VERSION ""

NS_ :

BS_:

BU_: HVESP01 HVESS

BO_ 2499742056 HVESP01_modTemperature_4: 8 HVESP01
 SG_ HVESP01_modTemperature_01_4 m0 : 16|8@1- (1,25) [-103|152] "Celsius"  HVESP01
 SG_ HVESP01_modTemperature_02_4 m0 : 24|8@1- (1,25) [-103|152] "Celsius"  HVESP01
 SG_ HVESP01_modTemperature_03_4 m0 : 32|8@1- (1,25) [-103|152] "Celsius"  HVESP01
 SG_ HVESP01_modTemperature_04_4 m0 : 40|8@1- (1,25) [-103|152] "Celsius"  HVESP01
 SG_ HVESP01_modTemperature_05_4 m0 : 48|8@1- (1,25) [-103|152] "Celsius"  HVESP01
 SG_ HVESP01_modTemperature_06_4 m1 : 16|8@1- (1,25) [-103|152] "Celsius"  HVESP01
 SG_ HVESP01_modTemperature_07_4 m1 : 24|8@1- (1,25) [-103|152] "Celsius"  HVESP01
 SG_ HVESP01_modTemperature_08_4 m1 : 32|8@1- (1,25) [-103|152] "Celsius"  HVESP01
 SG_ HVESP01_modTemperature_09_4 m1 : 40|8@1- (1,25) [-103|152] "Celsius"  HVESP01
 SG_ HVESP01_modTemperature_10_4 m1 : 48|8@1- (1,25) [-103|152] "Celsius"  HVESP01
 SG_ HVESP01_modTemperature_11_4 m2 : 16|8@1- (1,25) [-103|152] "Celsius"  HVESP01
 SG_ HVESP01_modTemperature_12_4 m2 : 24|8@1- (1,25) [-103|152] "Celsius"  HVESP01
 SG_ HVESP01_modTemperature_13_4 m2 : 32|8@1- (1,25) [-103|152] "Celsius"  HVESP01
 SG_ HVESP01_modTemperature_14_4 m2 : 40|8@1- (1,25) [-103|152] "Celsius"  HVESP01
 SG_ HVESP01_modTemperature_15_4 m2 : 48|8@1- (1,25) [-103|152] "Celsius"  HVESP01
 SG_ HVESP01_modTemperature_16_4 m3 : 16|8@1- (1,25) [-103|152] "Celsius"  HVESP01
 SG_ HVESP01_modTemperature_17_4 m3 : 24|8@1- (1,25) [-103|152] "Celsius"  HVESP01
 SG_ HVESP01_modTemperature_18_4 m3 : 32|8@1- (1,25) [-103|152] "Celsius"  HVESP01
 SG_ HVESP01_modTemperature_19_4 m3 : 40|8@1- (1,25) [-103|152] "Celsius"  HVESP01
 SG_ HVESP01_modTemperature_20_4 m3 : 48|8@1- (1,25) [-103|152] "Celsius"  HVESP01
 SG_ HVESP01_modTemperature_21_4 m4 : 16|8@1- (1,25) [-103|152] "Celsius"  HVESP01
 SG_ HVESP01_modTemperature_22_4 m4 : 24|8@1- (1,25) [-103|152] "Celsius"  HVESP01
 SG_ HVESP01_modTemperature_23_4 m4 : 32|8@1- (1,25) [-103|152] "Celsius"  HVESP01
 SG_ HVESP01_modTemperature_24_4 m4 : 40|8@1- (1,25) [-103|152] "Celsius"  HVESP01
 SG_ HVESP01_modTemperature_25_4 m4 : 48|8@1- (1,25) [-103|152] "Celsius"  HVESP01
 SG_ HVESP01_modTemperature_26_4 m5 : 16|8@1- (1,25) [-103|152] "Celsius"  HVESP01
 SG_ HVESP01_modTemperature_27_4 m5 : 24|8@1- (1,25) [-103|152] "Celsius"  HVESP01
 SG_ HVESP01_modTemperature_28_4 m5 : 32|8@1- (1,25) [-103|152] "Celsius"  HVESP01
 SG_ HVESP01_modTemperature_29_4 m5 : 40|8@1- (1,25) [-103|152] "Celsius"  HVESP01
 SG_ HVESP01_modTemperature_30_4 m5 : 48|8@1- (1,25) [-103|152] "Celsius"  HVESP01
 SG_ HVESP01_modTemperature_31_4 m6 : 16|8@1- (1,25) [-103|152] "Celsius"  HVESP01
 SG_ HVESP01_modTemperature_32_4 m6 : 24|8@1- (1,25) [-103|152] "Celsius"  HVESP01
 SG_ HVESP01_modTemperature_33_4 m6 : 32|8@1- (1,25) [-103|152] "Celsius"  HVESP01
 SG_ HVESP01_modTemperature_34_4 m6 : 40|8@1- (1,25) [-103|152] "Celsius"  HVESP01
 SG_ HVESP01_modTemperature_35_4 m6 : 48|8@1- (1,25) [-103|152] "Celsius"  HVESP01
 SG_ HVESP01_modTemperature_36_4 m7 : 16|8@1- (1,25) [-103|152] "Celsius"  HVESP01
 SG_ HVESP01_modTemperature_37_4 m7 : 24|8@1- (1,25) [-103|152] "Celsius"  HVESP01
 SG_ HVESP01_modTemperature_38_4 m7 : 32|8@1- (1,25) [-103|152] "Celsius"  HVESP01
 SG_ HVESP01_modTemperature_39_4 m7 : 40|8@1- (1,25) [-103|152] "Celsius"  HVESP01
 SG_ HVESP01_modTemperature_40_4 m7 : 48|8@1- (1,25) [-103|152] "Celsius"  HVESP01
 SG_ HVESP01_modTemperature_41_4 m8 : 16|8@1- (1,25) [-103|152] "Celsius"  HVESP01
 SG_ HVESP01_modTemperature_42_4 m8 : 24|8@1- (1,25) [-103|152] "Celsius"  HVESP01
 SG_ HVESP01_modTemperature_43_4 m8 : 32|8@1- (1,25) [-103|152] "Celsius"  HVESP01
 SG_ HVESP01_modTemperature_44_4 m8 : 40|8@1- (1,25) [-103|152] "Celsius"  HVESP01
 SG_ multiplexormt_4 M : 0|9@1+ (1,0) [0|255] ""  HVESP01

BO_ 2499742057 HVESP01_modTemperature_5: 8 HVESP01
 SG_ HVESP01_modTemperature_01_5 m0 : 16|8@1- (1,25) [-103|152] "Celsius"  HVESP01
 SG_ HVESP01_modTemperature_02_5 m0 : 24|8@1- (1,25) [-103|152] "Celsius"  HVESP01
 SG_ HVESP01_modTemperature_03_5 m0 : 32|8@1- (1,25) [-103|152] "Celsius"  HVESP01
 SG_ HVESP01_modTemperature_04_5 m0 : 40|8@1- (1,25) [-103|152] "Celsius"  HVESP01
 SG_ HVESP01_modTemperature_05_5 m0 : 48|8@1- (1,25) [-103|152] "Celsius"  HVESP01
 SG_ HVESP01_modTemperature_06_5 m1 : 16|8@1- (1,25) [-103|152] "Celsius"  HVESP01
 SG_ HVESP01_modTemperature_07_5 m1 : 24|8@1- (1,25) [-103|152] "Celsius"  HVESP01
 SG_ HVESP01_modTemperature_08_5 m1 : 32|8@1- (1,25) [-103|152] "Celsius"  HVESP01
 SG_ HVESP01_modTemperature_09_5 m1 : 40|8@1- (1,25) [-103|152] "Celsius"  HVESP01
 SG_ HVESP01_modTemperature_10_5 m1 : 48|8@1- (1,25) [-103|152] "Celsius"  HVESP01
 SG_ HVESP01_modTemperature_11_5 m2 : 16|8@1- (1,25) [-103|152] "Celsius"  HVESP01
 SG_ HVESP01_modTemperature_12_5 m2 : 24|8@1- (1,25) [-103|152] "Celsius"  HVESP01
 SG_ HVESP01_modTemperature_13_5 m2 : 32|8@1- (1,25) [-103|152] "Celsius"  HVESP01
 SG_ HVESP01_modTemperature_14_5 m2 : 40|8@1- (1,25) [-103|152] "Celsius"  HVESP01
 SG_ HVESP01_modTemperature_15_5 m2 : 48|8@1- (1,25) [-103|152] "Celsius"  HVESP01
 SG_ HVESP01_modTemperature_16_5 m3 : 16|8@1- (1,25) [-103|152] "Celsius"  HVESP01
 SG_ HVESP01_modTemperature_17_5 m3 : 24|8@1- (1,25) [-103|152] "Celsius"  HVESP01
 SG_ HVESP01_modTemperature_18_5 m3 : 32|8@1- (1,25) [-103|152] "Celsius"  HVESP01
 SG_ HVESP01_modTemperature_19_5 m3 : 40|8@1- (1,25) [-103|152] "Celsius"  HVESP01
 SG_ HVESP01_modTemperature_20_5 m3 : 48|8@1- (1,25) [-103|152] "Celsius"  HVESP01
 SG_ HVESP01_modTemperature_21_5 m4 : 16|8@1- (1,25) [-103|152] "Celsius"  HVESP01
 SG_ HVESP01_modTemperature_22_5 m4 : 24|8@1- (1,25) [-103|152] "Celsius"  HVESP01
 SG_ HVESP01_modTemperature_23_5 m4 : 32|8@1- (1,25) [-103|152] "Celsius"  HVESP01
 SG_ HVESP01_modTemperature_24_5 m4 : 40|8@1- (1,25) [-103|152] "Celsius"  HVESP01
 SG_ HVESP01_modTemperature_25_5 m4 : 48|8@1- (1,25) [-103|152] "Celsius"  HVESP01
 SG_ HVESP01_modTemperature_26_5 m5 : 16|8@1- (1,25) [-103|152] "Celsius"  HVESP01
 SG_ HVESP01_modTemperature_27_5 m5 : 24|8@1- (1,25) [-103|152] "Celsius"  HVESP01
 SG_ HVESP01_modTemperature_28_5 m5 : 32|8@1- (1,25) [-103|152] "Celsius"  HVESP01
 SG_ HVESP01_modTemperature_29_5 m5 : 40|8@1- (1,25) [-103|152] "Celsius"  HVESP01
 SG_ HVESP01_modTemperature_30_5 m5 : 48|8@1- (1,25) [-103|152] "Celsius"  HVESP01
 SG_ HVESP01_modTemperature_31_5 m6 : 16|8@1- (1,25) [-103|152] "Celsius"  HVESP01
 SG_ HVESP01_modTemperature_32_5 m6 : 24|8@1- (1,25) [-103|152] "Celsius"  HVESP01
 SG_ HVESP01_modTemperature_33_5 m6 : 32|8@1- (1,25) [-103|152] "Celsius"  HVESP01
 SG_ HVESP01_modTemperature_34_5 m6 : 40|8@1- (1,25) [-103|152] "Celsius"  HVESP01
 SG_ HVESP01_modTemperature_35_5 m6 : 48|8@1- (1,25) [-103|152] "Celsius"  HVESP01
 SG_ HVESP01_modTemperature_36_5 m7 : 16|8@1- (1,25) [-103|152] "Celsius"  HVESP01
 SG_ HVESP01_modTemperature_37_5 m7 : 24|8@1- (1,25) [-103|152] "Celsius"  HVESP01
 SG_ HVESP01_modTemperature_38_5 m7 : 32|8@1- (1,25) [-103|152] "Celsius"  HVESP01
 SG_ HVESP01_modTemperature_39_5 m7 : 40|8@1- (1,25) [-103|152] "Celsius"  HVESP01
 SG_ HVESP01_modTemperature_40_5 m7 : 48|8@1- (1,25) [-103|152] "Celsius"  HVESP01
 SG_ HVESP01_modTemperature_41_5 m8 : 16|8@1- (1,25) [-103|152] "Celsius"  HVESP01
 SG_ HVESP01_modTemperature_42_5 m8 : 24|8@1- (1,25) [-103|152] "Celsius"  HVESP01
 SG_ HVESP01_modTemperature_43_5 m8 : 32|8@1- (1,25) [-103|152] "Celsius"  HVESP01
 SG_ HVESP01_modTemperature_44_5 m8 : 40|8@1- (1,25) [-103|152] "Celsius"  HVESP01
 SG_ multiplexormt_5 M : 0|9@1+ (1,0) [0|255] ""  HVESP01

BO_ 2499742058 HVESP01_modTemperature_6: 8 HVESP01
 SG_ HVESP01_modTemperature_01_6 m0 : 16|8@1- (1,25) [-103|152] "Celsius"  HVESP01
 SG_ HVESP01_modTemperature_02_6 m0 : 24|8@1- (1,25) [-103|152] "Celsius"  HVESP01
 SG_ HVESP01_modTemperature_03_6 m0 : 32|8@1- (1,25) [-103|152] "Celsius"  HVESP01
 SG_ HVESP01_modTemperature_04_6 m0 : 40|8@1- (1,25) [-103|152] "Celsius"  HVESP01
 SG_ HVESP01_modTemperature_05_6 m0 : 48|8@1- (1,25) [-103|152] "Celsius"  HVESP01
 SG_ HVESP01_modTemperature_06_6 m1 : 16|8@1- (1,25) [-103|152] "Celsius"  HVESP01
 SG_ HVESP01_modTemperature_07_6 m1 : 24|8@1- (1,25) [-103|152] "Celsius"  HVESP01
 SG_ HVESP01_modTemperature_08_6 m1 : 32|8@1- (1,25) [-103|152] "Celsius"  HVESP01
 SG_ HVESP01_modTemperature_09_6 m1 : 40|8@1- (1,25) [-103|152] "Celsius"  HVESP01
 SG_ HVESP01_modTemperature_10_6 m1 : 48|8@1- (1,25) [-103|152] "Celsius"  HVESP01
 SG_ HVESP01_modTemperature_11_6 m2 : 16|8@1- (1,25) [-103|152] "Celsius"  HVESP01
 SG_ HVESP01_modTemperature_12_6 m2 : 24|8@1- (1,25) [-103|152] "Celsius"  HVESP01
 SG_ HVESP01_modTemperature_13_6 m2 : 32|8@1- (1,25) [-103|152] "Celsius"  HVESP01
 SG_ HVESP01_modTemperature_14_6 m2 : 40|8@1- (1,25) [-103|152] "Celsius"  HVESP01
 SG_ HVESP01_modTemperature_15_6 m2 : 48|8@1- (1,25) [-103|152] "Celsius"  HVESP01
 SG_ HVESP01_modTemperature_16_6 m3 : 16|8@1- (1,25) [-103|152] "Celsius"  HVESP01
 SG_ HVESP01_modTemperature_17_6 m3 : 24|8@1- (1,25) [-103|152] "Celsius"  HVESP01
 SG_ HVESP01_modTemperature_18_6 m3 : 32|8@1- (1,25) [-103|152] "Celsius"  HVESP01
 SG_ HVESP01_modTemperature_19_6 m3 : 40|8@1- (1,25) [-103|152] "Celsius"  HVESP01
 SG_ HVESP01_modTemperature_20_6 m3 : 48|8@1- (1,25) [-103|152] "Celsius"  HVESP01
 SG_ HVESP01_modTemperature_21_6 m4 : 16|8@1- (1,25) [-103|152] "Celsius"  HVESP01
 SG_ HVESP01_modTemperature_22_6 m4 : 24|8@1- (1,25) [-103|152] "Celsius"  HVESP01
 SG_ HVESP01_modTemperature_23_6 m4 : 32|8@1- (1,25) [-103|152] "Celsius"  HVESP01
 SG_ HVESP01_modTemperature_24_6 m4 : 40|8@1- (1,25) [-103|152] "Celsius"  HVESP01
 SG_ HVESP01_modTemperature_25_6 m4 : 48|8@1- (1,25) [-103|152] "Celsius"  HVESP01
 SG_ HVESP01_modTemperature_26_6 m5 : 16|8@1- (1,25) [-103|152] "Celsius"  HVESP01
 SG_ HVESP01_modTemperature_27_6 m5 : 24|8@1- (1,25) [-103|152] "Celsius"  HVESP01
 SG_ HVESP01_modTemperature_28_6 m5 : 32|8@1- (1,25) [-103|152] "Celsius"  HVESP01
 SG_ HVESP01_modTemperature_29_6 m5 : 40|8@1- (1,25) [-103|152] "Celsius"  HVESP01
 SG_ HVESP01_modTemperature_30_6 m5 : 48|8@1- (1,25) [-103|152] "Celsius"  HVESP01
 SG_ HVESP01_modTemperature_31_6 m6 : 16|8@1- (1,25) [-103|152] "Celsius"  HVESP01
 SG_ HVESP01_modTemperature_32_6 m6 : 24|8@1- (1,25) [-103|152] "Celsius"  HVESP01
 SG_ HVESP01_modTemperature_33_6 m6 : 32|8@1- (1,25) [-103|152] "Celsius"  HVESP01
 SG_ HVESP01_modTemperature_34_6 m6 : 40|8@1- (1,25) [-103|152] "Celsius"  HVESP01
 SG_ HVESP01_modTemperature_35_6 m6 : 48|8@1- (1,25) [-103|152] "Celsius"  HVESP01
 SG_ HVESP01_modTemperature_36_6 m7 : 16|8@1- (1,25) [-103|152] "Celsius"  HVESP01
 SG_ HVESP01_modTemperature_37_6 m7 : 24|8@1- (1,25) [-103|152] "Celsius"  HVESP01
 SG_ HVESP01_modTemperature_38_6 m7 : 32|8@1- (1,25) [-103|152] "Celsius"  HVESP01
 SG_ HVESP01_modTemperature_39_6 m7 : 40|8@1- (1,25) [-103|152] "Celsius"  HVESP01
 SG_ HVESP01_modTemperature_40_6 m7 : 48|8@1- (1,25) [-103|152] "Celsius"  HVESP01
 SG_ HVESP01_modTemperature_41_6 m8 : 16|8@1- (1,25) [-103|152] "Celsius"  HVESP01
 SG_ HVESP01_modTemperature_42_6 m8 : 24|8@1- (1,25) [-103|152] "Celsius"  HVESP01
 SG_ HVESP01_modTemperature_43_6 m8 : 32|8@1- (1,25) [-103|152] "Celsius"  HVESP01
 SG_ HVESP01_modTemperature_44_6 m8 : 40|8@1- (1,25) [-103|152] "Celsius"  HVESP01
 SG_ multiplexormt_6 M : 0|9@1+ (1,0) [0|255] ""  HVESP01

BO_ 2499742059 HVESP01_modTemperature_7: 8 HVESP01
 SG_ HVESP01_modTemperature_01_7 m0 : 16|8@1- (1,25) [-103|152] "Celsius"  HVESP01
 SG_ HVESP01_modTemperature_02_7 m0 : 24|8@1- (1,25) [-103|152] "Celsius"  HVESP01
 SG_ HVESP01_modTemperature_03_7 m0 : 32|8@1- (1,25) [-103|152] "Celsius"  HVESP01
 SG_ HVESP01_modTemperature_04_7 m0 : 40|8@1- (1,25) [-103|152] "Celsius"  HVESP01
 SG_ HVESP01_modTemperature_05_7 m0 : 48|8@1- (1,25) [-103|152] "Celsius"  HVESP01
 SG_ HVESP01_modTemperature_06_7 m1 : 16|8@1- (1,25) [-103|152] "Celsius"  HVESP01
 SG_ HVESP01_modTemperature_07_7 m1 : 24|8@1- (1,25) [-103|152] "Celsius"  HVESP01
 SG_ HVESP01_modTemperature_08_7 m1 : 32|8@1- (1,25) [-103|152] "Celsius"  HVESP01
 SG_ HVESP01_modTemperature_09_7 m1 : 40|8@1- (1,25) [-103|152] "Celsius"  HVESP01
 SG_ HVESP01_modTemperature_10_7 m1 : 48|8@1- (1,25) [-103|152] "Celsius"  HVESP01
 SG_ HVESP01_modTemperature_11_7 m2 : 16|8@1- (1,25) [-103|152] "Celsius"  HVESP01
 SG_ HVESP01_modTemperature_12_7 m2 : 24|8@1- (1,25) [-103|152] "Celsius"  HVESP01
 SG_ HVESP01_modTemperature_13_7 m2 : 32|8@1- (1,25) [-103|152] "Celsius"  HVESP01
 SG_ HVESP01_modTemperature_14_7 m2 : 40|8@1- (1,25) [-103|152] "Celsius"  HVESP01
 SG_ HVESP01_modTemperature_15_7 m2 : 48|8@1- (1,25) [-103|152] "Celsius"  HVESP01
 SG_ HVESP01_modTemperature_16_7 m3 : 16|8@1- (1,25) [-103|152] "Celsius"  HVESP01
 SG_ HVESP01_modTemperature_17_7 m3 : 24|8@1- (1,25) [-103|152] "Celsius"  HVESP01
 SG_ HVESP01_modTemperature_18_7 m3 : 32|8@1- (1,25) [-103|152] "Celsius"  HVESP01
 SG_ HVESP01_modTemperature_19_7 m3 : 40|8@1- (1,25) [-103|152] "Celsius"  HVESP01
 SG_ HVESP01_modTemperature_20_7 m3 : 48|8@1- (1,25) [-103|152] "Celsius"  HVESP01
 SG_ HVESP01_modTemperature_21_7 m4 : 16|8@1- (1,25) [-103|152] "Celsius"  HVESP01
 SG_ HVESP01_modTemperature_22_7 m4 : 24|8@1- (1,25) [-103|152] "Celsius"  HVESP01
 SG_ HVESP01_modTemperature_23_7 m4 : 32|8@1- (1,25) [-103|152] "Celsius"  HVESP01
 SG_ HVESP01_modTemperature_24_7 m4 : 40|8@1- (1,25) [-103|152] "Celsius"  HVESP01
 SG_ HVESP01_modTemperature_25_7 m4 : 48|8@1- (1,25) [-103|152] "Celsius"  HVESP01
 SG_ HVESP01_modTemperature_26_7 m5 : 16|8@1- (1,25) [-103|152] "Celsius"  HVESP01
 SG_ HVESP01_modTemperature_27_7 m5 : 24|8@1- (1,25) [-103|152] "Celsius"  HVESP01
 SG_ HVESP01_modTemperature_28_7 m5 : 32|8@1- (1,25) [-103|152] "Celsius"  HVESP01
 SG_ HVESP01_modTemperature_29_7 m5 : 40|8@1- (1,25) [-103|152] "Celsius"  HVESP01
 SG_ HVESP01_modTemperature_30_7 m5 : 48|8@1- (1,25) [-103|152] "Celsius"  HVESP01
 SG_ HVESP01_modTemperature_31_7 m6 : 16|8@1- (1,25) [-103|152] "Celsius"  HVESP01
 SG_ HVESP01_modTemperature_32_7 m6 : 24|8@1- (1,25) [-103|152] "Celsius"  HVESP01
 SG_ HVESP01_modTemperature_33_7 m6 : 32|8@1- (1,25) [-103|152] "Celsius"  HVESP01
 SG_ HVESP01_modTemperature_34_7 m6 : 40|8@1- (1,25) [-103|152] "Celsius"  HVESP01
 SG_ HVESP01_modTemperature_35_7 m6 : 48|8@1- (1,25) [-103|152] "Celsius"  HVESP01
 SG_ HVESP01_modTemperature_36_7 m7 : 16|8@1- (1,25) [-103|152] "Celsius"  HVESP01
 SG_ HVESP01_modTemperature_37_7 m7 : 24|8@1- (1,25) [-103|152] "Celsius"  HVESP01
 SG_ HVESP01_modTemperature_38_7 m7 : 32|8@1- (1,25) [-103|152] "Celsius"  HVESP01
 SG_ HVESP01_modTemperature_39_7 m7 : 40|8@1- (1,25) [-103|152] "Celsius"  HVESP01
 SG_ HVESP01_modTemperature_40_7 m7 : 48|8@1- (1,25) [-103|152] "Celsius"  HVESP01
 SG_ HVESP01_modTemperature_41_7 m8 : 16|8@1- (1,25) [-103|152] "Celsius"  HVESP01
 SG_ HVESP01_modTemperature_42_7 m8 : 24|8@1- (1,25) [-103|152] "Celsius"  HVESP01
 SG_ HVESP01_modTemperature_43_7 m8 : 32|8@1- (1,25) [-103|152] "Celsius"  HVESP01
 SG_ HVESP01_modTemperature_44_7 m8 : 40|8@1- (1,25) [-103|152] "Celsius"  HVESP01
 SG_ multiplexormt_7 M : 0|9@1+ (1,0) [0|255] ""  HVESP01

BO_ 2499742060 HVESP01_modTemperature_8: 8 HVESP01
 SG_ HVESP01_modTemperature_01_8 m0 : 16|8@1- (1,25) [-103|152] "Celsius"  HVESP01
 SG_ HVESP01_modTemperature_02_8 m0 : 24|8@1- (1,25) [-103|152] "Celsius"  HVESP01
 SG_ HVESP01_modTemperature_03_8 m0 : 32|8@1- (1,25) [-103|152] "Celsius"  HVESP01
 SG_ HVESP01_modTemperature_04_8 m0 : 40|8@1- (1,25) [-103|152] "Celsius"  HVESP01
 SG_ HVESP01_modTemperature_05_8 m0 : 48|8@1- (1,25) [-103|152] "Celsius"  HVESP01
 SG_ HVESP01_modTemperature_06_8 m1 : 16|8@1- (1,25) [-103|152] "Celsius"  HVESP01
 SG_ HVESP01_modTemperature_07_8 m1 : 24|8@1- (1,25) [-103|152] "Celsius"  HVESP01
 SG_ HVESP01_modTemperature_08_8 m1 : 32|8@1- (1,25) [-103|152] "Celsius"  HVESP01
 SG_ HVESP01_modTemperature_09_8 m1 : 40|8@1- (1,25) [-103|152] "Celsius"  HVESP01
 SG_ HVESP01_modTemperature_10_8 m1 : 48|8@1- (1,25) [-103|152] "Celsius"  HVESP01
 SG_ HVESP01_modTemperature_11_8 m2 : 16|8@1- (1,25) [-103|152] "Celsius"  HVESP01
 SG_ HVESP01_modTemperature_12_8 m2 : 24|8@1- (1,25) [-103|152] "Celsius"  HVESP01
 SG_ HVESP01_modTemperature_13_8 m2 : 32|8@1- (1,25) [-103|152] "Celsius"  HVESP01
 SG_ HVESP01_modTemperature_14_8 m2 : 40|8@1- (1,25) [-103|152] "Celsius"  HVESP01
 SG_ HVESP01_modTemperature_15_8 m2 : 48|8@1- (1,25) [-103|152] "Celsius"  HVESP01
 SG_ HVESP01_modTemperature_16_8 m3 : 16|8@1- (1,25) [-103|152] "Celsius"  HVESP01
 SG_ HVESP01_modTemperature_17_8 m3 : 24|8@1- (1,25) [-103|152] "Celsius"  HVESP01
 SG_ HVESP01_modTemperature_18_8 m3 : 32|8@1- (1,25) [-103|152] "Celsius"  HVESP01
 SG_ HVESP01_modTemperature_19_8 m3 : 40|8@1- (1,25) [-103|152] "Celsius"  HVESP01
 SG_ HVESP01_modTemperature_20_8 m3 : 48|8@1- (1,25) [-103|152] "Celsius"  HVESP01
 SG_ HVESP01_modTemperature_21_8 m4 : 16|8@1- (1,25) [-103|152] "Celsius"  HVESP01
 SG_ HVESP01_modTemperature_22_8 m4 : 24|8@1- (1,25) [-103|152] "Celsius"  HVESP01
 SG_ HVESP01_modTemperature_23_8 m4 : 32|8@1- (1,25) [-103|152] "Celsius"  HVESP01
 SG_ HVESP01_modTemperature_24_8 m4 : 40|8@1- (1,25) [-103|152] "Celsius"  HVESP01
 SG_ HVESP01_modTemperature_25_8 m4 : 48|8@1- (1,25) [-103|152] "Celsius"  HVESP01
 SG_ HVESP01_modTemperature_26_8 m5 : 16|8@1- (1,25) [-103|152] "Celsius"  HVESP01
 SG_ HVESP01_modTemperature_27_8 m5 : 24|8@1- (1,25) [-103|152] "Celsius"  HVESP01
 SG_ HVESP01_modTemperature_28_8 m5 : 32|8@1- (1,25) [-103|152] "Celsius"  HVESP01
 SG_ HVESP01_modTemperature_29_8 m5 : 40|8@1- (1,25) [-103|152] "Celsius"  HVESP01
 SG_ HVESP01_modTemperature_30_8 m5 : 48|8@1- (1,25) [-103|152] "Celsius"  HVESP01
 SG_ HVESP01_modTemperature_31_8 m6 : 16|8@1- (1,25) [-103|152] "Celsius"  HVESP01
 SG_ HVESP01_modTemperature_32_8 m6 : 24|8@1- (1,25) [-103|152] "Celsius"  HVESP01
 SG_ HVESP01_modTemperature_33_8 m6 : 32|8@1- (1,25) [-103|152] "Celsius"  HVESP01
 SG_ HVESP01_modTemperature_34_8 m6 : 40|8@1- (1,25) [-103|152] "Celsius"  HVESP01
 SG_ HVESP01_modTemperature_35_8 m6 : 48|8@1- (1,25) [-103|152] "Celsius"  HVESP01
 SG_ HVESP01_modTemperature_36_8 m7 : 16|8@1- (1,25) [-103|152] "Celsius"  HVESP01
 SG_ HVESP01_modTemperature_37_8 m7 : 24|8@1- (1,25) [-103|152] "Celsius"  HVESP01
 SG_ HVESP01_modTemperature_38_8 m7 : 32|8@1- (1,25) [-103|152] "Celsius"  HVESP01
 SG_ HVESP01_modTemperature_39_8 m7 : 40|8@1- (1,25) [-103|152] "Celsius"  HVESP01
 SG_ HVESP01_modTemperature_40_8 m7 : 48|8@1- (1,25) [-103|152] "Celsius"  HVESP01
 SG_ HVESP01_modTemperature_41_8 m8 : 16|8@1- (1,25) [-103|152] "Celsius"  HVESP01
 SG_ HVESP01_modTemperature_42_8 m8 : 24|8@1- (1,25) [-103|152] "Celsius"  HVESP01
 SG_ HVESP01_modTemperature_43_8 m8 : 32|8@1- (1,25) [-103|152] "Celsius"  HVESP01
 SG_ HVESP01_modTemperature_44_8 m8 : 40|8@1- (1,25) [-103|152] "Celsius"  HVESP01
 SG_ multiplexormt_8 M : 0|9@1+ (1,0) [0|255] ""  HVESP01

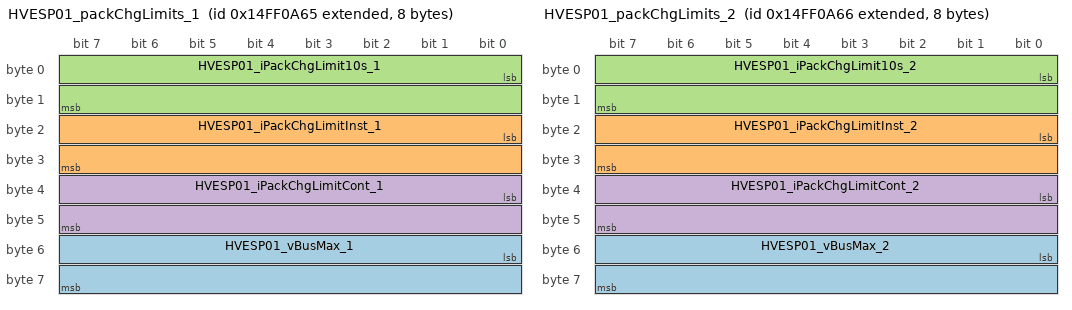
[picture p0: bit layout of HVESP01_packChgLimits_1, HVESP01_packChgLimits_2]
BO_ 2499742309 HVESP01_packChgLimits_1: 8 HVESP01
 SG_ HVESP01_vBusMax_1 : 48|16@1+ (0.02,0) [0|1310.7] "V"  HVESP01
 SG_ HVESP01_iPackChgLimitInst_1 : 16|16@1+ (0.025,0) [0|1638.375] "A"  HVESP01
 SG_ HVESP01_iPackChgLimit10s_1 : 0|16@1+ (0.025,0) [0|1638.375] "A"  HVESP01
 SG_ HVESP01_iPackChgLimitCont_1 : 32|16@1+ (0.01,0) [0|655.35] "A"  HVESP01

BO_ 2499742310 HVESP01_packChgLimits_2: 8 HVESP01
 SG_ HVESP01_vBusMax_2 : 48|16@1+ (0.02,0) [0|1310.7] "V"  HVESP01
 SG_ HVESP01_iPackChgLimitInst_2 : 16|16@1+ (0.025,0) [0|1638.375] "A"  HVESP01
 SG_ HVESP01_iPackChgLimit10s_2 : 0|16@1+ (0.025,0) [0|1638.375] "A"  HVESP01
 SG_ HVESP01_iPackChgLimitCont_2 : 32|16@1+ (0.01,0) [0|655.35] "A"  HVESP01

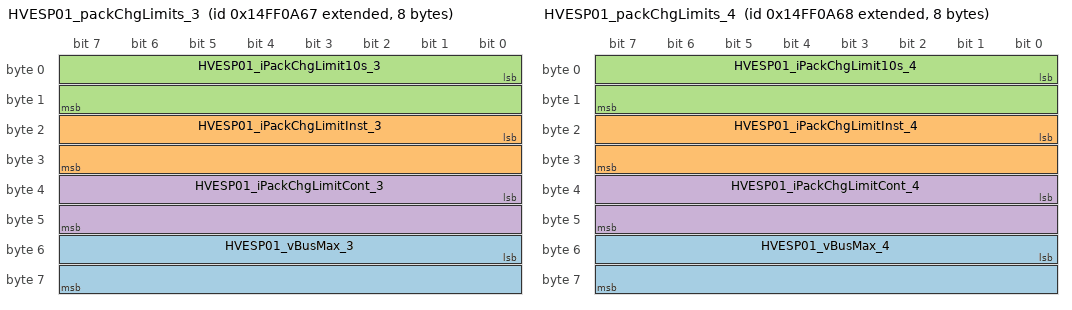
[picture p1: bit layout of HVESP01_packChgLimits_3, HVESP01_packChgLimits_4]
BO_ 2499742311 HVESP01_packChgLimits_3: 8 HVESP01
 SG_ HVESP01_vBusMax_3 : 48|16@1+ (0.02,0) [0|1310.7] "V"  HVESP01
 SG_ HVESP01_iPackChgLimitInst_3 : 16|16@1+ (0.025,0) [0|1638.375] "A"  HVESP01
 SG_ HVESP01_iPackChgLimit10s_3 : 0|16@1+ (0.025,0) [0|1638.375] "A"  HVESP01
 SG_ HVESP01_iPackChgLimitCont_3 : 32|16@1+ (0.01,0) [0|655.35] "A"  HVESP01

BO_ 2499742312 HVESP01_packChgLimits_4: 8 HVESP01
 SG_ HVESP01_vBusMax_4 : 48|16@1+ (0.02,0) [0|1310.7] "V"  HVESP01
 SG_ HVESP01_iPackChgLimitInst_4 : 16|16@1+ (0.025,0) [0|1638.375] "A"  HVESP01
 SG_ HVESP01_iPackChgLimit10s_4 : 0|16@1+ (0.025,0) [0|1638.375] "A"  HVESP01
 SG_ HVESP01_iPackChgLimitCont_4 : 32|16@1+ (0.01,0) [0|655.35] "A"  HVESP01

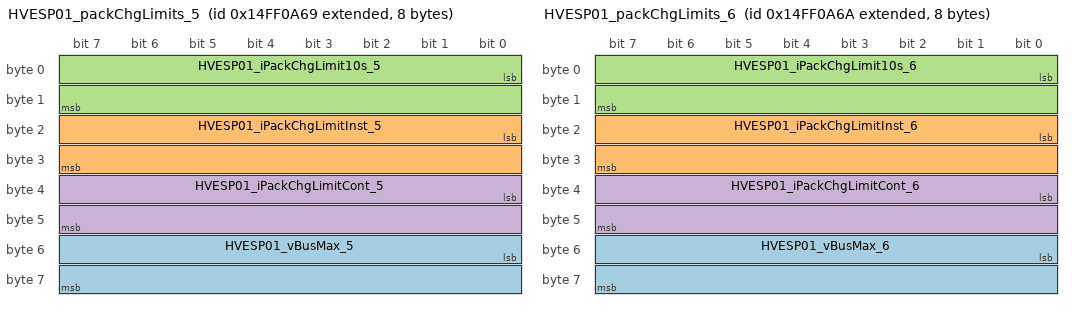
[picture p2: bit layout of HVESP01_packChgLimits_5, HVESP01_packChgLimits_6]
BO_ 2499742313 HVESP01_packChgLimits_5: 8 HVESP01
 SG_ HVESP01_vBusMax_5 : 48|16@1+ (0.02,0) [0|1310.7] "V"  HVESP01
 SG_ HVESP01_iPackChgLimitInst_5 : 16|16@1+ (0.025,0) [0|1638.375] "A"  HVESP01
 SG_ HVESP01_iPackChgLimit10s_5 : 0|16@1+ (0.025,0) [0|1638.375] "A"  HVESP01
 SG_ HVESP01_iPackChgLimitCont_5 : 32|16@1+ (0.01,0) [0|655.35] "A"  HVESP01

BO_ 2499742314 HVESP01_packChgLimits_6: 8 HVESP01
 SG_ HVESP01_vBusMax_6 : 48|16@1+ (0.02,0) [0|1310.7] "V"  HVESP01
 SG_ HVESP01_iPackChgLimitInst_6 : 16|16@1+ (0.025,0) [0|1638.375] "A"  HVESP01
 SG_ HVESP01_iPackChgLimit10s_6 : 0|16@1+ (0.025,0) [0|1638.375] "A"  HVESP01
 SG_ HVESP01_iPackChgLimitCont_6 : 32|16@1+ (0.01,0) [0|655.35] "A"  HVESP01

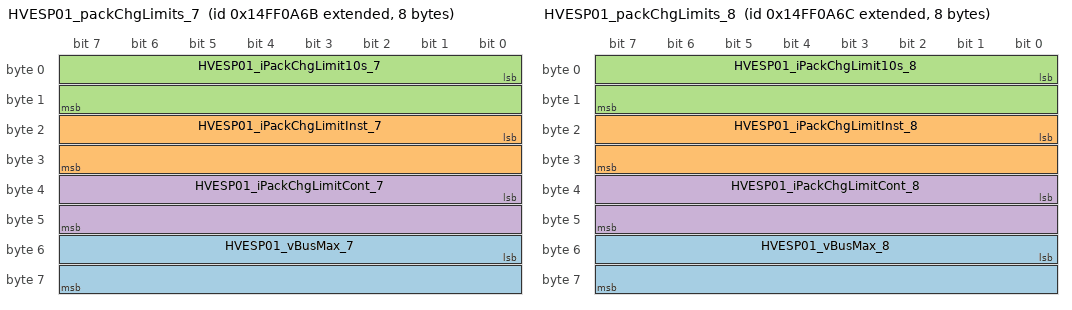
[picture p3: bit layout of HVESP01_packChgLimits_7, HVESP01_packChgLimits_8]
BO_ 2499742315 HVESP01_packChgLimits_7: 8 HVESP01
 SG_ HVESP01_vBusMax_7 : 48|16@1+ (0.02,0) [0|1310.7] "V"  HVESP01
 SG_ HVESP01_iPackChgLimitInst_7 : 16|16@1+ (0.025,0) [0|1638.375] "A"  HVESP01
 SG_ HVESP01_iPackChgLimit10s_7 : 0|16@1+ (0.025,0) [0|1638.375] "A"  HVESP01
 SG_ HVESP01_iPackChgLimitCont_7 : 32|16@1+ (0.01,0) [0|655.35] "A"  HVESP01

BO_ 2499742316 HVESP01_packChgLimits_8: 8 HVESP01
 SG_ HVESP01_vBusMax_8 : 48|16@1+ (0.02,0) [0|1310.7] "V"  HVESP01
 SG_ HVESP01_iPackChgLimitInst_8 : 16|16@1+ (0.025,0) [0|1638.375] "A"  HVESP01
 SG_ HVESP01_iPackChgLimit10s_8 : 0|16@1+ (0.025,0) [0|1638.375] "A"  HVESP01
 SG_ HVESP01_iPackChgLimitCont_8 : 32|16@1+ (0.01,0) [0|655.35] "A"  HVESP01

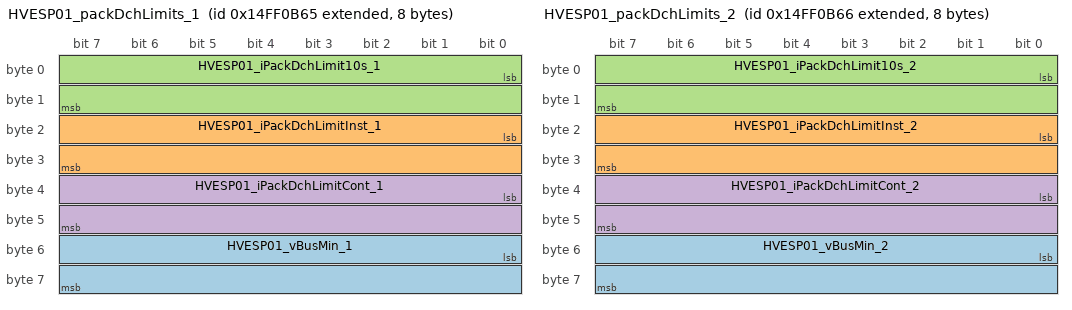
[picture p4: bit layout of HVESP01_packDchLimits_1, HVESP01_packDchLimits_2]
BO_ 2499742565 HVESP01_packDchLimits_1: 8 HVESP01
 SG_ HVESP01_vBusMin_1 : 48|16@1+ (0.02,0) [0|1310.7] "V"  HVESP01
 SG_ HVESP01_iPackDchLimitInst_1 : 16|16@1- (0.1,0) [-3276.8|0] "A"  HVESP01
 SG_ HVESP01_iPackDchLimit10s_1 : 0|16@1- (-0.1,0) [-3276.7|0] "A"  HVESP01
 SG_ HVESP01_iPackDchLimitCont_1 : 32|16@1- (0.02,0) [-655.36|0] "A"  HVESP01

BO_ 2499742566 HVESP01_packDchLimits_2: 8 HVESP01
 SG_ HVESP01_vBusMin_2 : 48|16@1+ (0.02,0) [0|1310.7] "V"  HVESP01
 SG_ HVESP01_iPackDchLimitInst_2 : 16|16@1- (0.1,0) [-3276.8|0] "A"  HVESP01
 SG_ HVESP01_iPackDchLimit10s_2 : 0|16@1- (-0.1,0) [-3276.7|0] "A"  HVESP01
 SG_ HVESP01_iPackDchLimitCont_2 : 32|16@1- (0.02,0) [-655.36|0] "A"  HVESP01

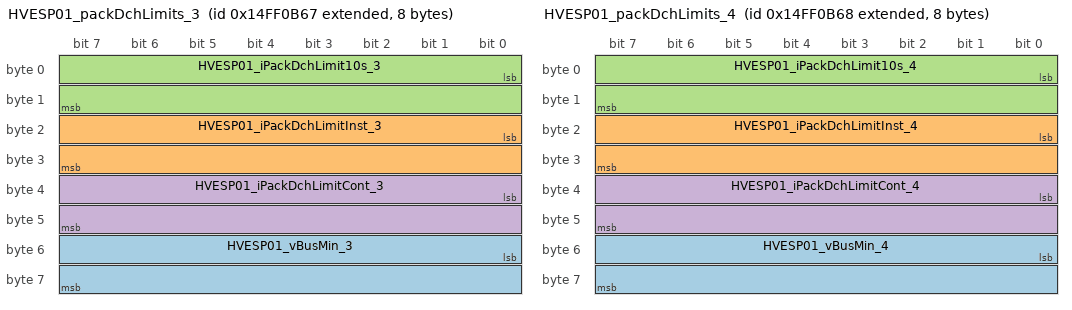
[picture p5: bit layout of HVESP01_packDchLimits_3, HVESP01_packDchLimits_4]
BO_ 2499742567 HVESP01_packDchLimits_3: 8 HVESP01
 SG_ HVESP01_vBusMin_3 : 48|16@1+ (0.02,0) [0|1310.7] "V"  HVESP01
 SG_ HVESP01_iPackDchLimitInst_3 : 16|16@1- (0.1,0) [-3276.8|0] "A"  HVESP01
 SG_ HVESP01_iPackDchLimit10s_3 : 0|16@1- (-0.1,0) [-3276.7|0] "A"  HVESP01
 SG_ HVESP01_iPackDchLimitCont_3 : 32|16@1- (0.02,0) [-655.36|0] "A"  HVESP01

BO_ 2499742568 HVESP01_packDchLimits_4: 8 HVESP01
 SG_ HVESP01_vBusMin_4 : 48|16@1+ (0.02,0) [0|1310.7] "V"  HVESP01
 SG_ HVESP01_iPackDchLimitInst_4 : 16|16@1- (0.1,0) [-3276.8|0] "A"  HVESP01
 SG_ HVESP01_iPackDchLimit10s_4 : 0|16@1- (-0.1,0) [-3276.7|0] "A"  HVESP01
 SG_ HVESP01_iPackDchLimitCont_4 : 32|16@1- (0.02,0) [-655.36|0] "A"  HVESP01

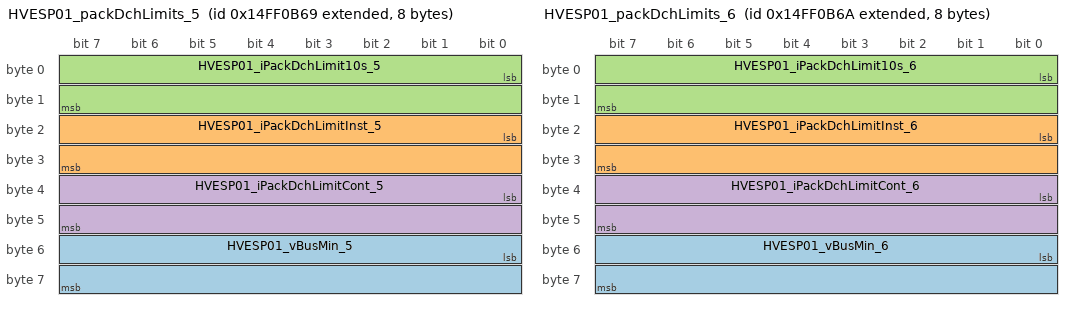
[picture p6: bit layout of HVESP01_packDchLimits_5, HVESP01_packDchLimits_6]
BO_ 2499742569 HVESP01_packDchLimits_5: 8 HVESP01
 SG_ HVESP01_vBusMin_5 : 48|16@1+ (0.02,0) [0|1310.7] "V"  HVESP01
 SG_ HVESP01_iPackDchLimitInst_5 : 16|16@1- (0.1,0) [-3276.8|0] "A"  HVESP01
 SG_ HVESP01_iPackDchLimit10s_5 : 0|16@1- (-0.1,0) [-3276.7|0] "A"  HVESP01
 SG_ HVESP01_iPackDchLimitCont_5 : 32|16@1- (0.02,0) [-655.36|0] "A"  HVESP01

BO_ 2499742570 HVESP01_packDchLimits_6: 8 HVESP01
 SG_ HVESP01_vBusMin_6 : 48|16@1+ (0.02,0) [0|1310.7] "V"  HVESP01
 SG_ HVESP01_iPackDchLimitInst_6 : 16|16@1- (0.1,0) [-3276.8|0] "A"  HVESP01
 SG_ HVESP01_iPackDchLimit10s_6 : 0|16@1- (-0.1,0) [-3276.7|0] "A"  HVESP01
 SG_ HVESP01_iPackDchLimitCont_6 : 32|16@1- (0.02,0) [-655.36|0] "A"  HVESP01

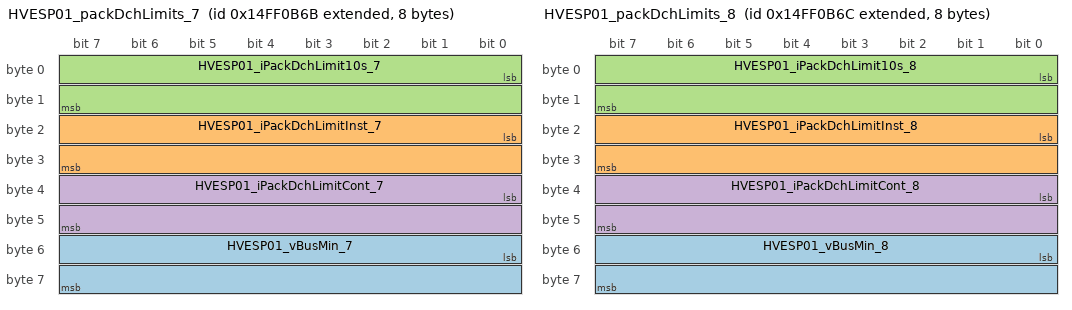
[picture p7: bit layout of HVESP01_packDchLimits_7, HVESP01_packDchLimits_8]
BO_ 2499742571 HVESP01_packDchLimits_7: 8 HVESP01
 SG_ HVESP01_vBusMin_7 : 48|16@1+ (0.02,0) [0|1310.7] "V"  HVESP01
 SG_ HVESP01_iPackDchLimitInst_7 : 16|16@1- (0.1,0) [-3276.8|0] "A"  HVESP01
 SG_ HVESP01_iPackDchLimit10s_7 : 0|16@1- (-0.1,0) [-3276.7|0] "A"  HVESP01
 SG_ HVESP01_iPackDchLimitCont_7 : 32|16@1- (0.02,0) [-655.36|0] "A"  HVESP01

BO_ 2499742572 HVESP01_packDchLimits_8: 8 HVESP01
 SG_ HVESP01_vBusMin_8 : 48|16@1+ (0.02,0) [0|1310.7] "V"  HVESP01
 SG_ HVESP01_iPackDchLimitInst_8 : 16|16@1- (0.1,0) [-3276.8|0] "A"  HVESP01
 SG_ HVESP01_iPackDchLimit10s_8 : 0|16@1- (-0.1,0) [-3276.7|0] "A"  HVESP01
 SG_ HVESP01_iPackDchLimitCont_8 : 32|16@1- (0.02,0) [-655.36|0] "A"  HVESP01

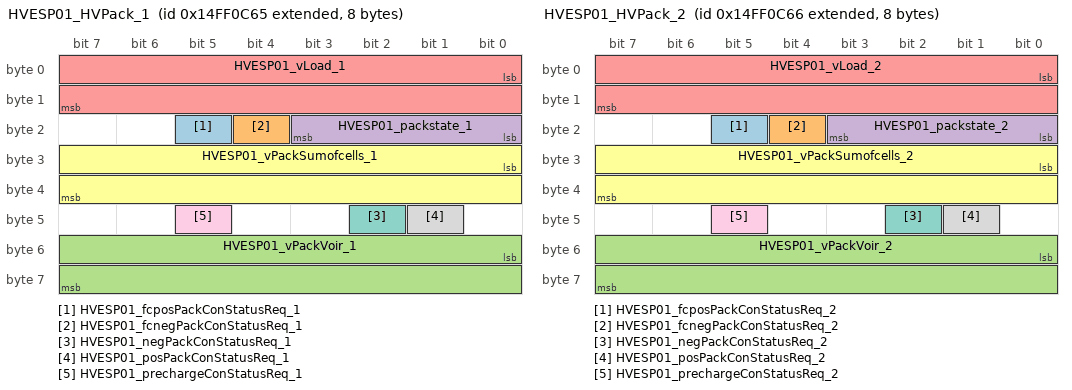
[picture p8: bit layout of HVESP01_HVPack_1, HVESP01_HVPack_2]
BO_ 2499742821 HVESP01_HVPack_1: 8 HVESP01
 SG_ HVESP01_fcposPackConStatusReq_1 : 21|1@1+ (1,0) [0|1] ""  HVESP01
 SG_ HVESP01_fcnegPackConStatusReq_1 : 20|1@1+ (1,0) [0|1] ""  HVESP01
 SG_ HVESP01_vPackVoir_1 : 48|16@1+ (0.05,0) [0|3276.75] "V"  HVESP01
 SG_ HVESP01_packstate_1 : 16|4@1+ (1,0) [0|15] ""  HVESP01
 SG_ HVESP01_vLoad_1 : 0|16@1+ (0.05,0) [0|3276.75] "V"  HVESP01
 SG_ HVESP01_vPackSumofcells_1 : 24|16@1+ (0.05,0) [0|3276.75] "V"  HVESP01
 SG_ HVESP01_negPackConStatusReq_1 : 42|1@1+ (1,0) [0|1] ""  HVESP01
 SG_ HVESP01_posPackConStatusReq_1 : 41|1@1+ (1,0) [0|1] ""  HVESP01
 SG_ HVESP01_prechargeConStatusReq_1 : 45|1@1+ (1,0) [0|1] ""  HVESP01

BO_ 2499742822 HVESP01_HVPack_2: 8 HVESP01
 SG_ HVESP01_fcposPackConStatusReq_2 : 21|1@1+ (1,0) [0|1] ""  HVESP01
 SG_ HVESP01_fcnegPackConStatusReq_2 : 20|1@1+ (1,0) [0|1] ""  HVESP01
 SG_ HVESP01_vPackVoir_2 : 48|16@1+ (0.05,0) [0|3276.75] "V"  HVESP01
 SG_ HVESP01_packstate_2 : 16|4@1+ (1,0) [0|15] ""  HVESP01
 SG_ HVESP01_vLoad_2 : 0|16@1+ (0.05,0) [0|3276.75] "V"  HVESP01
 SG_ HVESP01_vPackSumofcells_2 : 24|16@1+ (0.05,0) [0|3276.75] "V"  HVESP01
 SG_ HVESP01_negPackConStatusReq_2 : 42|1@1+ (1,0) [0|1] ""  HVESP01
 SG_ HVESP01_posPackConStatusReq_2 : 41|1@1+ (1,0) [0|1] ""  HVESP01
 SG_ HVESP01_prechargeConStatusReq_2 : 45|1@1+ (1,0) [0|1] ""  HVESP01

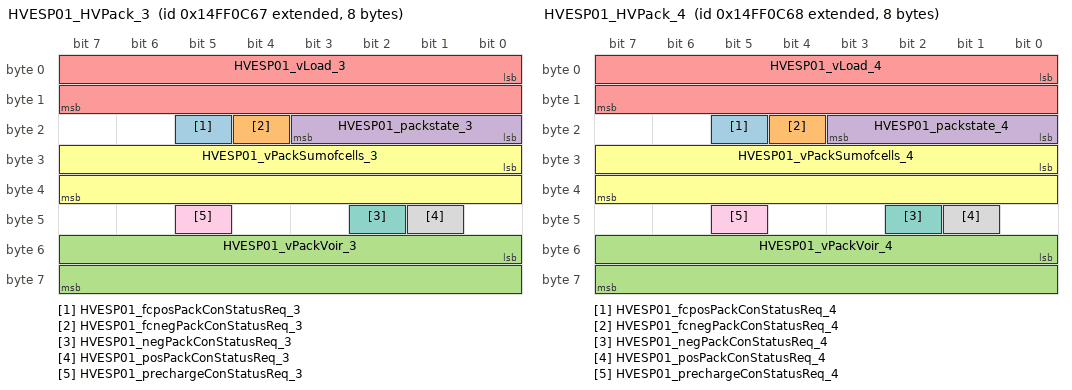
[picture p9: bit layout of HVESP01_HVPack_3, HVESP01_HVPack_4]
BO_ 2499742823 HVESP01_HVPack_3: 8 HVESP01
 SG_ HVESP01_fcposPackConStatusReq_3 : 21|1@1+ (1,0) [0|1] ""  HVESP01
 SG_ HVESP01_fcnegPackConStatusReq_3 : 20|1@1+ (1,0) [0|1] ""  HVESP01
 SG_ HVESP01_vPackVoir_3 : 48|16@1+ (0.05,0) [0|3276.75] "V"  HVESP01
 SG_ HVESP01_packstate_3 : 16|4@1+ (1,0) [0|15] ""  HVESP01
 SG_ HVESP01_vLoad_3 : 0|16@1+ (0.05,0) [0|3276.75] "V"  HVESP01
 SG_ HVESP01_vPackSumofcells_3 : 24|16@1+ (0.05,0) [0|3276.75] "V"  HVESP01
 SG_ HVESP01_negPackConStatusReq_3 : 42|1@1+ (1,0) [0|1] ""  HVESP01
 SG_ HVESP01_posPackConStatusReq_3 : 41|1@1+ (1,0) [0|1] ""  HVESP01
 SG_ HVESP01_prechargeConStatusReq_3 : 45|1@1+ (1,0) [0|1] ""  HVESP01

BO_ 2499742824 HVESP01_HVPack_4: 8 HVESP01
 SG_ HVESP01_fcposPackConStatusReq_4 : 21|1@1+ (1,0) [0|1] ""  HVESP01
 SG_ HVESP01_fcnegPackConStatusReq_4 : 20|1@1+ (1,0) [0|1] ""  HVESP01
 SG_ HVESP01_vPackVoir_4 : 48|16@1+ (0.05,0) [0|3276.75] "V"  HVESP01
 SG_ HVESP01_packstate_4 : 16|4@1+ (1,0) [0|15] ""  HVESP01
 SG_ HVESP01_vLoad_4 : 0|16@1+ (0.05,0) [0|3276.75] "V"  HVESP01
 SG_ HVESP01_vPackSumofcells_4 : 24|16@1+ (0.05,0) [0|3276.75] "V"  HVESP01
 SG_ HVESP01_negPackConStatusReq_4 : 42|1@1+ (1,0) [0|1] ""  HVESP01
 SG_ HVESP01_posPackConStatusReq_4 : 41|1@1+ (1,0) [0|1] ""  HVESP01
 SG_ HVESP01_prechargeConStatusReq_4 : 45|1@1+ (1,0) [0|1] ""  HVESP01

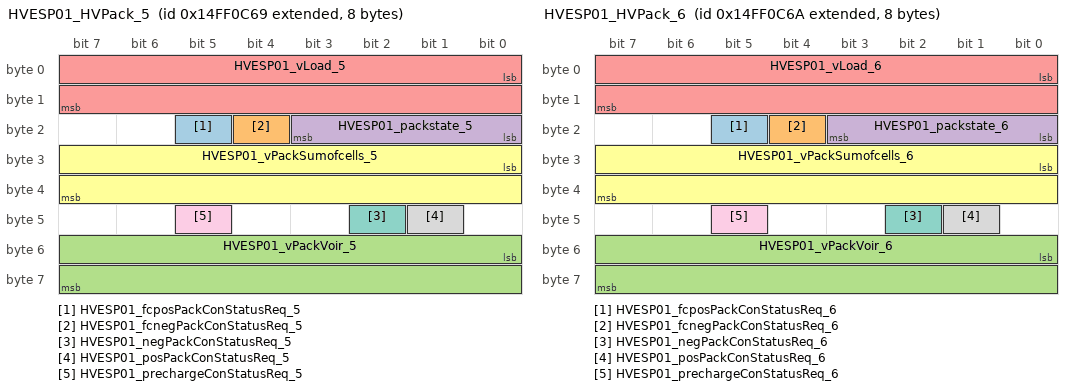
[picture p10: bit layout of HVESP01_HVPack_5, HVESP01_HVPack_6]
BO_ 2499742825 HVESP01_HVPack_5: 8 HVESP01
 SG_ HVESP01_fcposPackConStatusReq_5 : 21|1@1+ (1,0) [0|1] ""  HVESP01
 SG_ HVESP01_fcnegPackConStatusReq_5 : 20|1@1+ (1,0) [0|1] ""  HVESP01
 SG_ HVESP01_vPackVoir_5 : 48|16@1+ (0.05,0) [0|3276.75] "V"  HVESP01
 SG_ HVESP01_packstate_5 : 16|4@1+ (1,0) [0|15] ""  HVESP01
 SG_ HVESP01_vLoad_5 : 0|16@1+ (0.05,0) [0|3276.75] "V"  HVESP01
 SG_ HVESP01_vPackSumofcells_5 : 24|16@1+ (0.05,0) [0|3276.75] "V"  HVESP01
 SG_ HVESP01_negPackConStatusReq_5 : 42|1@1+ (1,0) [0|1] ""  HVESP01
 SG_ HVESP01_posPackConStatusReq_5 : 41|1@1+ (1,0) [0|1] ""  HVESP01
 SG_ HVESP01_prechargeConStatusReq_5 : 45|1@1+ (1,0) [0|1] ""  HVESP01

BO_ 2499742826 HVESP01_HVPack_6: 8 HVESP01
 SG_ HVESP01_fcposPackConStatusReq_6 : 21|1@1+ (1,0) [0|1] ""  HVESP01
 SG_ HVESP01_fcnegPackConStatusReq_6 : 20|1@1+ (1,0) [0|1] ""  HVESP01
 SG_ HVESP01_vPackVoir_6 : 48|16@1+ (0.05,0) [0|3276.75] "V"  HVESP01
 SG_ HVESP01_packstate_6 : 16|4@1+ (1,0) [0|15] ""  HVESP01
 SG_ HVESP01_vLoad_6 : 0|16@1+ (0.05,0) [0|3276.75] "V"  HVESP01
 SG_ HVESP01_vPackSumofcells_6 : 24|16@1+ (0.05,0) [0|3276.75] "V"  HVESP01
 SG_ HVESP01_negPackConStatusReq_6 : 42|1@1+ (1,0) [0|1] ""  HVESP01
 SG_ HVESP01_posPackConStatusReq_6 : 41|1@1+ (1,0) [0|1] ""  HVESP01
 SG_ HVESP01_prechargeConStatusReq_6 : 45|1@1+ (1,0) [0|1] ""  HVESP01

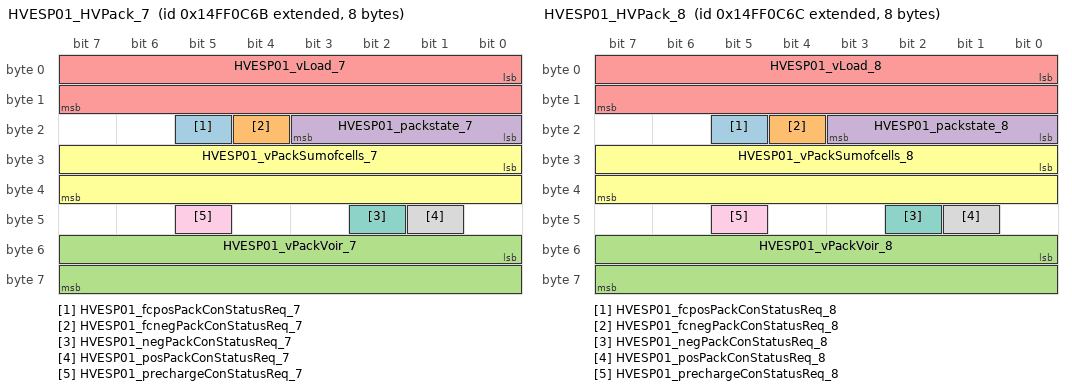
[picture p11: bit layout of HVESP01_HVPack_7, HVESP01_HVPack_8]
BO_ 2499742827 HVESP01_HVPack_7: 8 HVESP01
 SG_ HVESP01_fcposPackConStatusReq_7 : 21|1@1+ (1,0) [0|1] ""  HVESP01
 SG_ HVESP01_fcnegPackConStatusReq_7 : 20|1@1+ (1,0) [0|1] ""  HVESP01
 SG_ HVESP01_vPackVoir_7 : 48|16@1+ (0.05,0) [0|3276.75] "V"  HVESP01
 SG_ HVESP01_packstate_7 : 16|4@1+ (1,0) [0|15] ""  HVESP01
 SG_ HVESP01_vLoad_7 : 0|16@1+ (0.05,0) [0|3276.75] "V"  HVESP01
 SG_ HVESP01_vPackSumofcells_7 : 24|16@1+ (0.05,0) [0|3276.75] "V"  HVESP01
 SG_ HVESP01_negPackConStatusReq_7 : 42|1@1+ (1,0) [0|1] ""  HVESP01
 SG_ HVESP01_posPackConStatusReq_7 : 41|1@1+ (1,0) [0|1] ""  HVESP01
 SG_ HVESP01_prechargeConStatusReq_7 : 45|1@1+ (1,0) [0|1] ""  HVESP01

BO_ 2499742828 HVESP01_HVPack_8: 8 HVESP01
 SG_ HVESP01_fcposPackConStatusReq_8 : 21|1@1+ (1,0) [0|1] ""  HVESP01
 SG_ HVESP01_fcnegPackConStatusReq_8 : 20|1@1+ (1,0) [0|1] ""  HVESP01
 SG_ HVESP01_vPackVoir_8 : 48|16@1+ (0.05,0) [0|3276.75] "V"  HVESP01
 SG_ HVESP01_packstate_8 : 16|4@1+ (1,0) [0|15] ""  HVESP01
 SG_ HVESP01_vLoad_8 : 0|16@1+ (0.05,0) [0|3276.75] "V"  HVESP01
 SG_ HVESP01_vPackSumofcells_8 : 24|16@1+ (0.05,0) [0|3276.75] "V"  HVESP01
 SG_ HVESP01_negPackConStatusReq_8 : 42|1@1+ (1,0) [0|1] ""  HVESP01
 SG_ HVESP01_posPackConStatusReq_8 : 41|1@1+ (1,0) [0|1] ""  HVESP01
 SG_ HVESP01_prechargeConStatusReq_8 : 45|1@1+ (1,0) [0|1] ""  HVESP01

BO_ 2499743077 HVESP01_Version_1: 8 HVESP01
 SG_ HVESP01_SerNum_Prod_Serial_No_1 m4 : 32|16@1+ (1,0) [0|9999] ""  HVESP01
 SG_ HVESP01_SerNum_Location_1 m4 : 48|8@1+ (1,0) [0|3] ""  HVESP01
 SG_ HVESP01_SerNum_Julian_Date_1 m4 : 8|17@1+ (1,0) [0|9999] ""  HVESP01
 SG_ HVESP01_SerNum_PartNo_SubVersion m3 : 40|10@1+ (1,0) [0|1023] ""  HVESP01
 SG_ HVESP01_SerNum_PartNo_Main_1 m3 : 8|32@1+ (1,0) [0|99999999] ""  HVESP01
 SG_ HVESP01_SwVerSubMinorApp_1 m0 : 24|8@1+ (1,0) [0|255] ""  HVESP01
 SG_ HVESP01_SwVerMinorApp_1 m0 : 16|8@1+ (1,0) [0|255] ""  HVESP01
 SG_ HVESP01_SwVerMajorApp_1 m0 : 8|8@1+ (1,0) [0|255] ""  HVESP01
 SG_ HVESP01_HwVerApp_1 m0 : 32|8@1+ (1,0) [0|255] ""  HVESP01
 SG_ HVESP01_SwVerAbsCusApp_1 m0 : 40|8@1+ (1,0) [0|255] ""  HVESP01
 SG_ HVESP01_SwVerAbsIntApp_1 m0 : 48|8@1+ (1,0) [0|255] ""  HVESP01
 SG_ HVESP01_SwVerSubMinorBl_1 m1 : 24|8@1+ (1,0) [0|255] ""  HVESP01
 SG_ HVESP01_SwVerMinorBl_1 m1 : 16|8@1+ (1,0) [0|255] ""  HVESP01
 SG_ HVESP01_SwVerMajorBl_1 m1 : 8|8@1+ (1,0) [0|255] ""  HVESP01
 SG_ HVESP01_HwVerBl_1 m1 : 32|8@1+ (1,0) [0|255] ""  HVESP01
 SG_ HVESP01_SwVerAbsCusBl_1 m1 : 40|8@1+ (1,0) [0|255] ""  HVESP01
 SG_ HVESP01_SwVerAbsIntBl_1 m1 : 48|8@1+ (1,0) [0|255] ""  HVESP01
 SG_ HVESP01_SwVerSubMinorCal_1 m2 : 24|8@1+ (1,0) [0|255] ""  HVESP01
 SG_ HVESP01_SwVerMinorCal_1 m2 : 16|8@1+ (1,0) [0|255] ""  HVESP01
 SG_ HVESP01_SwVerMajorCal_1 m2 : 8|8@1+ (1,0) [0|255] ""  HVESP01
 SG_ HVESP01_HwVerCal_1 m2 : 32|8@1+ (1,0) [0|255] ""  HVESP01
 SG_ HVESP01_SwVerAbsCusCal_1 m2 : 40|8@1+ (1,0) [0|255] ""  HVESP01
 SG_ HVESP01_SwVerAbsIntCal_1 m2 : 48|8@1+ (1,0) [0|255] ""  HVESP01
 SG_ multiplexorvr_1 M : 0|4@1+ (1,0) [0|15] ""  HVESP01

BO_ 2499743078 HVESP01_Version_2: 8 HVESP01
 SG_ HVESP01_SerNum_Prod_Serial_No_2 m4 : 32|16@1+ (1,0) [0|9999] ""  HVESP01
 SG_ HVESP01_SerNum_Location_2 m4 : 48|8@1+ (1,0) [0|3] ""  HVESP01
 SG_ HVESP01_SerNum_Julian_Date_2 m4 : 8|17@1+ (1,0) [0|9999] ""  HVESP01
 SG_ HVESP01_SerNum_PartNo_SubVe_0000 m3 : 40|10@1+ (1,0) [0|1023] ""  HVESP01
 SG_ HVESP01_SerNum_PartNo_Main_2 m3 : 8|32@1+ (1,0) [0|99999999] ""  HVESP01
 SG_ HVESP01_SwVerSubMinorApp_2 m0 : 24|8@1+ (1,0) [0|255] ""  HVESP01
 SG_ HVESP01_SwVerMinorApp_2 m0 : 16|8@1+ (1,0) [0|255] ""  HVESP01
 SG_ HVESP01_SwVerMajorApp_2 m0 : 8|8@1+ (1,0) [0|255] ""  HVESP01
 SG_ HVESP01_HwVerApp_2 m0 : 32|8@1+ (1,0) [0|255] ""  HVESP01
 SG_ HVESP01_SwVerAbsCusApp_2 m0 : 40|8@1+ (1,0) [0|255] ""  HVESP01
 SG_ HVESP01_SwVerAbsIntApp_2 m0 : 48|8@1+ (1,0) [0|255] ""  HVESP01
 SG_ HVESP01_SwVerSubMinorBl_2 m1 : 24|8@1+ (1,0) [0|255] ""  HVESP01
 SG_ HVESP01_SwVerMinorBl_2 m1 : 16|8@1+ (1,0) [0|255] ""  HVESP01
 SG_ HVESP01_SwVerMajorBl_2 m1 : 8|8@1+ (1,0) [0|255] ""  HVESP01
 SG_ HVESP01_HwVerBl_2 m1 : 32|8@1+ (1,0) [0|255] ""  HVESP01
 SG_ HVESP01_SwVerAbsCusBl_2 m1 : 40|8@1+ (1,0) [0|255] ""  HVESP01
 SG_ HVESP01_SwVerAbsIntBl_2 m1 : 48|8@1+ (1,0) [0|255] ""  HVESP01
 SG_ HVESP01_SwVerSubMinorCal_2 m2 : 24|8@1+ (1,0) [0|255] ""  HVESP01
 SG_ HVESP01_SwVerMinorCal_2 m2 : 16|8@1+ (1,0) [0|255] ""  HVESP01
 SG_ HVESP01_SwVerMajorCal_2 m2 : 8|8@1+ (1,0) [0|255] ""  HVESP01
 SG_ HVESP01_HwVerCal_2 m2 : 32|8@1+ (1,0) [0|255] ""  HVESP01
 SG_ HVESP01_SwVerAbsCusCal_2 m2 : 40|8@1+ (1,0) [0|255] ""  HVESP01
 SG_ HVESP01_SwVerAbsIntCal_2 m2 : 48|8@1+ (1,0) [0|255] ""  HVESP01
 SG_ multiplexorvr_2 M : 0|4@1+ (1,0) [0|15] ""  HVESP01

BO_ 2499743079 HVESP01_Version_3: 8 HVESP01
 SG_ HVESP01_SerNum_Prod_Serial_No_3 m4 : 32|16@1+ (1,0) [0|9999] ""  HVESP01
 SG_ HVESP01_SerNum_Location_3 m4 : 48|8@1+ (1,0) [0|3] ""  HVESP01
 SG_ HVESP01_SerNum_Julian_Date_3 m4 : 8|17@1+ (1,0) [0|9999] ""  HVESP01
 SG_ HVESP01_SerNum_PartNo_SubVe_0001 m3 : 40|10@1+ (1,0) [0|1023] ""  HVESP01
 SG_ HVESP01_SerNum_PartNo_Main_3 m3 : 8|32@1+ (1,0) [0|99999999] ""  HVESP01
 SG_ HVESP01_SwVerSubMinorApp_3 m0 : 24|8@1+ (1,0) [0|255] ""  HVESP01
 SG_ HVESP01_SwVerMinorApp_3 m0 : 16|8@1+ (1,0) [0|255] ""  HVESP01
 SG_ HVESP01_SwVerMajorApp_3 m0 : 8|8@1+ (1,0) [0|255] ""  HVESP01
 SG_ HVESP01_HwVerApp_3 m0 : 32|8@1+ (1,0) [0|255] ""  HVESP01
 SG_ HVESP01_SwVerAbsCusApp_3 m0 : 40|8@1+ (1,0) [0|255] ""  HVESP01
 SG_ HVESP01_SwVerAbsIntApp_3 m0 : 48|8@1+ (1,0) [0|255] ""  HVESP01
 SG_ HVESP01_SwVerSubMinorBl_3 m1 : 24|8@1+ (1,0) [0|255] ""  HVESP01
 SG_ HVESP01_SwVerMinorBl_3 m1 : 16|8@1+ (1,0) [0|255] ""  HVESP01
 SG_ HVESP01_SwVerMajorBl_3 m1 : 8|8@1+ (1,0) [0|255] ""  HVESP01
 SG_ HVESP01_HwVerBl_3 m1 : 32|8@1+ (1,0) [0|255] ""  HVESP01
 SG_ HVESP01_SwVerAbsCusBl_3 m1 : 40|8@1+ (1,0) [0|255] ""  HVESP01
 SG_ HVESP01_SwVerAbsIntBl_3 m1 : 48|8@1+ (1,0) [0|255] ""  HVESP01
 SG_ HVESP01_SwVerSubMinorCal_3 m2 : 24|8@1+ (1,0) [0|255] ""  HVESP01
 SG_ HVESP01_SwVerMinorCal_3 m2 : 16|8@1+ (1,0) [0|255] ""  HVESP01
 SG_ HVESP01_SwVerMajorCal_3 m2 : 8|8@1+ (1,0) [0|255] ""  HVESP01
 SG_ HVESP01_HwVerCal_3 m2 : 32|8@1+ (1,0) [0|255] ""  HVESP01
 SG_ HVESP01_SwVerAbsCusCal_3 m2 : 40|8@1+ (1,0) [0|255] ""  HVESP01
 SG_ HVESP01_SwVerAbsIntCal_3 m2 : 48|8@1+ (1,0) [0|255] ""  HVESP01
 SG_ multiplexorvr_3 M : 0|4@1+ (1,0) [0|15] ""  HVESP01

BO_ 2499743080 HVESP01_Version_4: 8 HVESP01
 SG_ HVESP01_SerNum_Prod_Serial_No_4 m4 : 32|16@1+ (1,0) [0|9999] ""  HVESP01
 SG_ HVESP01_SerNum_Location_4 m4 : 48|8@1+ (1,0) [0|3] ""  HVESP01
 SG_ HVESP01_SerNum_Julian_Date_4 m4 : 8|17@1+ (1,0) [0|9999] ""  HVESP01
 SG_ HVESP01_SerNum_PartNo_SubVe_0002 m3 : 40|10@1+ (1,0) [0|1023] ""  HVESP01
 SG_ HVESP01_SerNum_PartNo_Main_4 m3 : 8|32@1+ (1,0) [0|99999999] ""  HVESP01
 SG_ HVESP01_SwVerSubMinorApp_4 m0 : 24|8@1+ (1,0) [0|255] ""  HVESP01
 SG_ HVESP01_SwVerMinorApp_4 m0 : 16|8@1+ (1,0) [0|255] ""  HVESP01
 SG_ HVESP01_SwVerMajorApp_4 m0 : 8|8@1+ (1,0) [0|255] ""  HVESP01
 SG_ HVESP01_HwVerApp_4 m0 : 32|8@1+ (1,0) [0|255] ""  HVESP01
 SG_ HVESP01_SwVerAbsCusApp_4 m0 : 40|8@1+ (1,0) [0|255] ""  HVESP01
 SG_ HVESP01_SwVerAbsIntApp_4 m0 : 48|8@1+ (1,0) [0|255] ""  HVESP01
 SG_ HVESP01_SwVerSubMinorBl_4 m1 : 24|8@1+ (1,0) [0|255] ""  HVESP01
 SG_ HVESP01_SwVerMinorBl_4 m1 : 16|8@1+ (1,0) [0|255] ""  HVESP01
 SG_ HVESP01_SwVerMajorBl_4 m1 : 8|8@1+ (1,0) [0|255] ""  HVESP01
 SG_ HVESP01_HwVerBl_4 m1 : 32|8@1+ (1,0) [0|255] ""  HVESP01
 SG_ HVESP01_SwVerAbsCusBl_4 m1 : 40|8@1+ (1,0) [0|255] ""  HVESP01
 SG_ HVESP01_SwVerAbsIntBl_4 m1 : 48|8@1+ (1,0) [0|255] ""  HVESP01
 SG_ HVESP01_SwVerSubMinorCal_4 m2 : 24|8@1+ (1,0) [0|255] ""  HVESP01
 SG_ HVESP01_SwVerMinorCal_4 m2 : 16|8@1+ (1,0) [0|255] ""  HVESP01
 SG_ HVESP01_SwVerMajorCal_4 m2 : 8|8@1+ (1,0) [0|255] ""  HVESP01
 SG_ HVESP01_HwVerCal_4 m2 : 32|8@1+ (1,0) [0|255] ""  HVESP01
 SG_ HVESP01_SwVerAbsCusCal_4 m2 : 40|8@1+ (1,0) [0|255] ""  HVESP01
 SG_ HVESP01_SwVerAbsIntCal_4 m2 : 48|8@1+ (1,0) [0|255] ""  HVESP01
 SG_ multiplexorvr_4 M : 0|4@1+ (1,0) [0|15] ""  HVESP01

BO_ 2499743081 HVESP01_Version_5: 8 HVESP01
 SG_ HVESP01_SerNum_Prod_Serial_No_5 m4 : 32|16@1+ (1,0) [0|9999] ""  HVESP01
 SG_ HVESP01_SerNum_Location_5 m4 : 48|8@1+ (1,0) [0|3] ""  HVESP01
 SG_ HVESP01_SerNum_Julian_Date_5 m4 : 8|17@1+ (1,0) [0|9999] ""  HVESP01
 SG_ HVESP01_SerNum_PartNo_SubVe_0003 m3 : 40|10@1+ (1,0) [0|1023] ""  HVESP01
 SG_ HVESP01_SerNum_PartNo_Main_5 m3 : 8|32@1+ (1,0) [0|99999999] ""  HVESP01
 SG_ HVESP01_SwVerSubMinorApp_5 m0 : 24|8@1+ (1,0) [0|255] ""  HVESP01
 SG_ HVESP01_SwVerMinorApp_5 m0 : 16|8@1+ (1,0) [0|255] ""  HVESP01
 SG_ HVESP01_SwVerMajorApp_5 m0 : 8|8@1+ (1,0) [0|255] ""  HVESP01
 SG_ HVESP01_HwVerApp_5 m0 : 32|8@1+ (1,0) [0|255] ""  HVESP01
 SG_ HVESP01_SwVerAbsCusApp_5 m0 : 40|8@1+ (1,0) [0|255] ""  HVESP01
 SG_ HVESP01_SwVerAbsIntApp_5 m0 : 48|8@1+ (1,0) [0|255] ""  HVESP01
 SG_ HVESP01_SwVerSubMinorBl_5 m1 : 24|8@1+ (1,0) [0|255] ""  HVESP01
 SG_ HVESP01_SwVerMinorBl_5 m1 : 16|8@1+ (1,0) [0|255] ""  HVESP01
 SG_ HVESP01_SwVerMajorBl_5 m1 : 8|8@1+ (1,0) [0|255] ""  HVESP01
 SG_ HVESP01_HwVerBl_5 m1 : 32|8@1+ (1,0) [0|255] ""  HVESP01
 SG_ HVESP01_SwVerAbsCusBl_5 m1 : 40|8@1+ (1,0) [0|255] ""  HVESP01
 SG_ HVESP01_SwVerAbsIntBl_5 m1 : 48|8@1+ (1,0) [0|255] ""  HVESP01
 SG_ HVESP01_SwVerSubMinorCal_5 m2 : 24|8@1+ (1,0) [0|255] ""  HVESP01
 SG_ HVESP01_SwVerMinorCal_5 m2 : 16|8@1+ (1,0) [0|255] ""  HVESP01
 SG_ HVESP01_SwVerMajorCal_5 m2 : 8|8@1+ (1,0) [0|255] ""  HVESP01
 SG_ HVESP01_HwVerCal_5 m2 : 32|8@1+ (1,0) [0|255] ""  HVESP01
 SG_ HVESP01_SwVerAbsCusCal_5 m2 : 40|8@1+ (1,0) [0|255] ""  HVESP01
 SG_ HVESP01_SwVerAbsIntCal_5 m2 : 48|8@1+ (1,0) [0|255] ""  HVESP01
 SG_ multiplexorvr_5 M : 0|4@1+ (1,0) [0|15] ""  HVESP01

BO_ 2499743082 HVESP01_Version_6: 8 HVESP01
 SG_ HVESP01_SerNum_Prod_Serial_No_6 m4 : 32|16@1+ (1,0) [0|9999] ""  HVESP01
 SG_ HVESP01_SerNum_Location_6 m4 : 48|8@1+ (1,0) [0|3] ""  HVESP01
 SG_ HVESP01_SerNum_Julian_Date_6 m4 : 8|17@1+ (1,0) [0|9999] ""  HVESP01
 SG_ HVESP01_SerNum_PartNo_SubVe_0004 m3 : 40|10@1+ (1,0) [0|1023] ""  HVESP01
 SG_ HVESP01_SerNum_PartNo_Main_6 m3 : 8|32@1+ (1,0) [0|99999999] ""  HVESP01
 SG_ HVESP01_SwVerSubMinorApp_6 m0 : 24|8@1+ (1,0) [0|255] ""  HVESP01
 SG_ HVESP01_SwVerMinorApp_6 m0 : 16|8@1+ (1,0) [0|255] ""  HVESP01
 SG_ HVESP01_SwVerMajorApp_6 m0 : 8|8@1+ (1,0) [0|255] ""  HVESP01
 SG_ HVESP01_HwVerApp_6 m0 : 32|8@1+ (1,0) [0|255] ""  HVESP01
 SG_ HVESP01_SwVerAbsCusApp_6 m0 : 40|8@1+ (1,0) [0|255] ""  HVESP01
 SG_ HVESP01_SwVerAbsIntApp_6 m0 : 48|8@1+ (1,0) [0|255] ""  HVESP01
 SG_ HVESP01_SwVerSubMinorBl_6 m1 : 24|8@1+ (1,0) [0|255] ""  HVESP01
 SG_ HVESP01_SwVerMinorBl_6 m1 : 16|8@1+ (1,0) [0|255] ""  HVESP01
 SG_ HVESP01_SwVerMajorBl_6 m1 : 8|8@1+ (1,0) [0|255] ""  HVESP01
 SG_ HVESP01_HwVerBl_6 m1 : 32|8@1+ (1,0) [0|255] ""  HVESP01
 SG_ HVESP01_SwVerAbsCusBl_6 m1 : 40|8@1+ (1,0) [0|255] ""  HVESP01
 SG_ HVESP01_SwVerAbsIntBl_6 m1 : 48|8@1+ (1,0) [0|255] ""  HVESP01
 SG_ HVESP01_SwVerSubMinorCal_6 m2 : 24|8@1+ (1,0) [0|255] ""  HVESP01
 SG_ HVESP01_SwVerMinorCal_6 m2 : 16|8@1+ (1,0) [0|255] ""  HVESP01
 SG_ HVESP01_SwVerMajorCal_6 m2 : 8|8@1+ (1,0) [0|255] ""  HVESP01
 SG_ HVESP01_HwVerCal_6 m2 : 32|8@1+ (1,0) [0|255] ""  HVESP01
 SG_ HVESP01_SwVerAbsCusCal_6 m2 : 40|8@1+ (1,0) [0|255] ""  HVESP01
 SG_ HVESP01_SwVerAbsIntCal_6 m2 : 48|8@1+ (1,0) [0|255] ""  HVESP01
 SG_ multiplexorvr_6 M : 0|4@1+ (1,0) [0|15] ""  HVESP01

BO_ 2499743083 HVESP01_Version_7: 8 HVESP01
 SG_ HVESP01_SerNum_Prod_Serial_No_7 m4 : 32|16@1+ (1,0) [0|9999] ""  HVESP01
 SG_ HVESP01_SerNum_Location_7 m4 : 48|8@1+ (1,0) [0|3] ""  HVESP01
 SG_ HVESP01_SerNum_Julian_Date_7 m4 : 8|17@1+ (1,0) [0|9999] ""  HVESP01
 SG_ HVESP01_SerNum_PartNo_SubVe_0005 m3 : 40|10@1+ (1,0) [0|1023] ""  HVESP01
 SG_ HVESP01_SerNum_PartNo_Main_7 m3 : 8|32@1+ (1,0) [0|99999999] ""  HVESP01
 SG_ HVESP01_SwVerSubMinorApp_7 m0 : 24|8@1+ (1,0) [0|255] ""  HVESP01
 SG_ HVESP01_SwVerMinorApp_7 m0 : 16|8@1+ (1,0) [0|255] ""  HVESP01
 SG_ HVESP01_SwVerMajorApp_7 m0 : 8|8@1+ (1,0) [0|255] ""  HVESP01
 SG_ HVESP01_HwVerApp_7 m0 : 32|8@1+ (1,0) [0|255] ""  HVESP01
 SG_ HVESP01_SwVerAbsCusApp_7 m0 : 40|8@1+ (1,0) [0|255] ""  HVESP01
 SG_ HVESP01_SwVerAbsIntApp_7 m0 : 48|8@1+ (1,0) [0|255] ""  HVESP01
 SG_ HVESP01_SwVerSubMinorBl_7 m1 : 24|8@1+ (1,0) [0|255] ""  HVESP01
 SG_ HVESP01_SwVerMinorBl_7 m1 : 16|8@1+ (1,0) [0|255] ""  HVESP01
 SG_ HVESP01_SwVerMajorBl_7 m1 : 8|8@1+ (1,0) [0|255] ""  HVESP01
 SG_ HVESP01_HwVerBl_7 m1 : 32|8@1+ (1,0) [0|255] ""  HVESP01
 SG_ HVESP01_SwVerAbsCusBl_7 m1 : 40|8@1+ (1,0) [0|255] ""  HVESP01
 SG_ HVESP01_SwVerAbsIntBl_7 m1 : 48|8@1+ (1,0) [0|255] ""  HVESP01
 SG_ HVESP01_SwVerSubMinorCal_7 m2 : 24|8@1+ (1,0) [0|255] ""  HVESP01
 SG_ HVESP01_SwVerMinorCal_7 m2 : 16|8@1+ (1,0) [0|255] ""  HVESP01
 SG_ HVESP01_SwVerMajorCal_7 m2 : 8|8@1+ (1,0) [0|255] ""  HVESP01
 SG_ HVESP01_HwVerCal_7 m2 : 32|8@1+ (1,0) [0|255] ""  HVESP01
 SG_ HVESP01_SwVerAbsCusCal_7 m2 : 40|8@1+ (1,0) [0|255] ""  HVESP01
 SG_ HVESP01_SwVerAbsIntCal_7 m2 : 48|8@1+ (1,0) [0|255] ""  HVESP01
 SG_ multiplexorvr_7 M : 0|4@1+ (1,0) [0|15] ""  HVESP01

BO_ 2499743084 HVESP01_Version_8: 8 HVESP01
 SG_ HVESP01_SerNum_Prod_Serial_No_8 m4 : 32|16@1+ (1,0) [0|9999] ""  HVESP01
 SG_ HVESP01_SerNum_Location_8 m4 : 48|8@1+ (1,0) [0|3] ""  HVESP01
 SG_ HVESP01_SerNum_Julian_Date_8 m4 : 8|17@1+ (1,0) [0|9999] ""  HVESP01
 SG_ HVESP01_SerNum_PartNo_SubVe_0006 m3 : 40|10@1+ (1,0) [0|1023] ""  HVESP01
 SG_ HVESP01_SerNum_PartNo_Main_8 m3 : 8|32@1+ (1,0) [0|99999999] ""  HVESP01
 SG_ HVESP01_SwVerSubMinorApp_8 m0 : 24|8@1+ (1,0) [0|255] ""  HVESP01
 SG_ HVESP01_SwVerMinorApp_8 m0 : 16|8@1+ (1,0) [0|255] ""  HVESP01
 SG_ HVESP01_SwVerMajorApp_8 m0 : 8|8@1+ (1,0) [0|255] ""  HVESP01
 SG_ HVESP01_HwVerApp_8 m0 : 32|8@1+ (1,0) [0|255] ""  HVESP01
 SG_ HVESP01_SwVerAbsCusApp_8 m0 : 40|8@1+ (1,0) [0|255] ""  HVESP01
 SG_ HVESP01_SwVerAbsIntApp_8 m0 : 48|8@1+ (1,0) [0|255] ""  HVESP01
 SG_ HVESP01_SwVerSubMinorBl_8 m1 : 24|8@1+ (1,0) [0|255] ""  HVESP01
 SG_ HVESP01_SwVerMinorBl_8 m1 : 16|8@1+ (1,0) [0|255] ""  HVESP01
 SG_ HVESP01_SwVerMajorBl_8 m1 : 8|8@1+ (1,0) [0|255] ""  HVESP01
 SG_ HVESP01_HwVerBl_8 m1 : 32|8@1+ (1,0) [0|255] ""  HVESP01
 SG_ HVESP01_SwVerAbsCusBl_8 m1 : 40|8@1+ (1,0) [0|255] ""  HVESP01
 SG_ HVESP01_SwVerAbsIntBl_8 m1 : 48|8@1+ (1,0) [0|255] ""  HVESP01
 SG_ HVESP01_SwVerSubMinorCal_8 m2 : 24|8@1+ (1,0) [0|255] ""  HVESP01
 SG_ HVESP01_SwVerMinorCal_8 m2 : 16|8@1+ (1,0) [0|255] ""  HVESP01
 SG_ HVESP01_SwVerMajorCal_8 m2 : 8|8@1+ (1,0) [0|255] ""  HVESP01
 SG_ HVESP01_HwVerCal_8 m2 : 32|8@1+ (1,0) [0|255] ""  HVESP01
 SG_ HVESP01_SwVerAbsCusCal_8 m2 : 40|8@1+ (1,0) [0|255] ""  HVESP01
 SG_ HVESP01_SwVerAbsIntCal_8 m2 : 48|8@1+ (1,0) [0|255] ""  HVESP01
 SG_ multiplexorvr_8 M : 0|4@1+ (1,0) [0|15] ""  HVESP01

BO_ 2499743333 HVESP01_CellBalance_1: 8 HVESP01
 SG_ HVESP01_CellBalance_01_1 m0 : 8|1@1+ (1,0) [0|1] ""  HVESP01
 SG_ HVESP01_CellBalance_02_1 m0 : 9|1@1+ (1,0) [0|1] ""  HVESP01
 SG_ HVESP01_CellBalance_03_1 m0 : 10|1@1+ (1,0) [0|1] ""  HVESP01
 SG_ HVESP01_CellBalance_04_1 m0 : 11|1@1+ (1,0) [0|1] ""  HVESP01
 SG_ HVESP01_CellBalance_05_1 m0 : 12|1@1+ (1,0) [0|1] ""  HVESP01
 SG_ HVESP01_CellBalance_06_1 m0 : 13|1@1+ (1,0) [0|1] ""  HVESP01
 SG_ HVESP01_CellBalance_07_1 m0 : 14|1@1+ (1,0) [0|1] ""  HVESP01
 SG_ HVESP01_CellBalance_08_1 m0 : 15|1@1+ (1,0) [0|1] ""  HVESP01
 SG_ HVESP01_CellBalance_09_1 m1 : 8|1@1+ (1,0) [0|1] ""  HVESP01
 SG_ HVESP01_CellBalance_10_1 m1 : 9|1@1+ (1,0) [0|1] ""  HVESP01
 SG_ HVESP01_CellBalance_11_1 m1 : 10|1@1+ (1,0) [0|1] ""  HVESP01
 SG_ HVESP01_CellBalance_12_1 m1 : 11|1@1+ (1,0) [0|1] ""  HVESP01
 SG_ HVESP01_CellBalance_13_1 m1 : 12|1@1+ (1,0) [0|1] ""  HVESP01
 SG_ HVESP01_CellBalance_14_1 m1 : 13|1@1+ (1,0) [0|1] ""  HVESP01
 SG_ HVESP01_CellBalance_15_1 m1 : 14|1@1+ (1,0) [0|1] ""  HVESP01
 SG_ HVESP01_CellBalance_16_1 m1 : 15|1@1+ (1,0) [0|1] ""  HVESP01
 SG_ HVESP01_CellBalance_17_1 m2 : 8|1@1+ (1,0) [0|1] ""  HVESP01
 SG_ HVESP01_CellBalance_18_1 m2 : 9|1@1+ (1,0) [0|1] ""  HVESP01
 SG_ HVESP01_CellBalance_19_1 m2 : 10|1@1+ (1,0) [0|1] ""  HVESP01
 SG_ HVESP01_CellBalance_20_1 m2 : 11|1@1+ (1,0) [0|1] ""  HVESP01
 SG_ HVESP01_CellBalance_21_1 m2 : 12|1@1+ (1,0) [0|1] ""  HVESP01
 SG_ HVESP01_CellBalance_22_1 m2 : 13|1@1+ (1,0) [0|1] ""  HVESP01
 SG_ HVESP01_CellBalance_23_1 m2 : 14|1@1+ (1,0) [0|1] ""  HVESP01
 SG_ HVESP01_CellBalance_24_1 m2 : 15|1@1+ (1,0) [0|1] ""  HVESP01
 SG_ HVESP01_CellBalance_25_1 m3 : 8|1@1+ (1,0) [0|1] ""  HVESP01
 SG_ HVESP01_CellBalance_26_1 m3 : 9|1@1+ (1,0) [0|1] ""  HVESP01
 SG_ HVESP01_CellBalance_27_1 m3 : 10|1@1+ (1,0) [0|1] ""  HVESP01
 SG_ HVESP01_CellBalance_28_1 m3 : 11|1@1+ (1,0) [0|1] ""  HVESP01
 SG_ HVESP01_CellBalance_29_1 m3 : 12|1@1+ (1,0) [0|1] ""  HVESP01
 SG_ HVESP01_CellBalance_30_1 m3 : 13|1@1+ (1,0) [0|1] ""  HVESP01
 SG_ HVESP01_CellBalance_31_1 m3 : 14|1@1+ (1,0) [0|1] ""  HVESP01
 SG_ HVESP01_CellBalance_32_1 m3 : 15|1@1+ (1,0) [0|1] ""  HVESP01
 SG_ HVESP01_CellBalance_33_1 m4 : 8|1@1+ (1,0) [0|1] ""  HVESP01
 SG_ HVESP01_CellBalance_34_1 m4 : 9|1@1+ (1,0) [0|1] ""  HVESP01
 SG_ HVESP01_CellBalance_35_1 m4 : 10|1@1+ (1,0) [0|1] ""  HVESP01
 SG_ HVESP01_CellBalance_36_1 m4 : 11|1@1+ (1,0) [0|1] ""  HVESP01
 SG_ HVESP01_CellBalance_37_1 m4 : 12|1@1+ (1,0) [0|1] ""  HVESP01
 SG_ HVESP01_CellBalance_38_1 m4 : 13|1@1+ (1,0) [0|1] ""  HVESP01
 SG_ HVESP01_CellBalance_39_1 m4 : 14|1@1+ (1,0) [0|1] ""  HVESP01
 SG_ HVESP01_CellBalance_40_1 m4 : 15|1@1+ (1,0) [0|1] ""  HVESP01
 SG_ HVESP01_CellBalance_41_1 m5 : 8|1@1+ (1,0) [0|1] ""  HVESP01
 SG_ HVESP01_CellBalance_42_1 m5 : 9|1@1+ (1,0) [0|1] ""  HVESP01
 SG_ HVESP01_CellBalance_43_1 m5 : 10|1@1+ (1,0) [0|1] ""  HVESP01
 SG_ HVESP01_CellBalance_44_1 m5 : 11|1@1+ (1,0) [0|1] ""  HVESP01
 SG_ HVESP01_CellBalance_45_1 m5 : 12|1@1+ (1,0) [0|1] ""  HVESP01
 SG_ HVESP01_CellBalance_46_1 m5 : 13|1@1+ (1,0) [0|1] ""  HVESP01
 SG_ HVESP01_CellBalance_47_1 m5 : 14|1@1+ (1,0) [0|1] ""  HVESP01
 SG_ HVESP01_CellBalance_48_1 m5 : 15|1@1+ (1,0) [0|1] ""  HVESP01
 SG_ HVESP01_CellBalance_49_1 m6 : 8|1@1+ (1,0) [0|1] ""  HVESP01
 SG_ HVESP01_CellBalance_50_1 m6 : 9|1@1+ (1,0) [0|1] ""  HVESP01
 SG_ HVESP01_CellBalance_51_1 m6 : 10|1@1+ (1,0) [0|1] ""  HVESP01
 SG_ HVESP01_CellBalance_52_1 m6 : 11|1@1+ (1,0) [0|1] ""  HVESP01
 SG_ HVESP01_CellBalance_53_1 m6 : 12|1@1+ (1,0) [0|1] ""  HVESP01
 SG_ HVESP01_CellBalance_54_1 m6 : 13|1@1+ (1,0) [0|1] ""  HVESP01
 SG_ HVESP01_CellBalance_55_1 m6 : 14|1@1+ (1,0) [0|1] ""  HVESP01
 SG_ HVESP01_CellBalance_56_1 m6 : 15|1@1+ (1,0) [0|1] ""  HVESP01
 SG_ HVESP01_CellBalance_57_1 m7 : 8|1@1+ (1,0) [0|1] ""  HVESP01
 SG_ HVESP01_CellBalance_58_1 m7 : 9|1@1+ (1,0) [0|1] ""  HVESP01
 SG_ HVESP01_CellBalance_59_1 m7 : 10|1@1+ (1,0) [0|1] ""  HVESP01
 SG_ HVESP01_CellBalance_60_1 m7 : 11|1@1+ (1,0) [0|1] ""  HVESP01
 SG_ HVESP01_CellBalance_61_1 m7 : 12|1@1+ (1,0) [0|1] ""  HVESP01
 SG_ HVESP01_CellBalance_62_1 m7 : 13|1@1+ (1,0) [0|1] ""  HVESP01
 SG_ HVESP01_CellBalance_63_1 m7 : 14|1@1+ (1,0) [0|1] ""  HVESP01
 SG_ HVESP01_CellBalance_64_1 m7 : 15|1@1+ (1,0) [0|1] ""  HVESP01
 SG_ HVESP01_CellBalance_65_1 m8 : 8|1@1+ (1,0) [0|1] ""  HVESP01
 SG_ HVESP01_CellBalance_66_1 m8 : 9|1@1+ (1,0) [0|1] ""  HVESP01
 SG_ HVESP01_CellBalance_67_1 m8 : 10|1@1+ (1,0) [0|1] ""  HVESP01
 SG_ HVESP01_CellBalance_68_1 m8 : 11|1@1+ (1,0) [0|1] ""  HVESP01
 SG_ HVESP01_CellBalance_69_1 m8 : 12|1@1+ (1,0) [0|1] ""  HVESP01
 SG_ HVESP01_CellBalance_70_1 m8 : 13|1@1+ (1,0) [0|1] ""  HVESP01
 SG_ HVESP01_CellBalance_71_1 m8 : 14|1@1+ (1,0) [0|1] ""  HVESP01
 SG_ HVESP01_CellBalance_72_1 m8 : 15|1@1+ (1,0) [0|1] ""  HVESP01
 SG_ HVESP01_CellBalance_73_1 m9 : 8|1@1+ (1,0) [0|1] ""  HVESP01
 SG_ HVESP01_CellBalance_74_1 m9 : 9|1@1+ (1,0) [0|1] ""  HVESP01
 SG_ HVESP01_CellBalance_75_1 m9 : 10|1@1+ (1,0) [0|1] ""  HVESP01
 SG_ HVESP01_CellBalance_76_1 m9 : 11|1@1+ (1,0) [0|1] ""  HVESP01
 SG_ HVESP01_CellBalance_77_1 m9 : 12|1@1+ (1,0) [0|1] ""  HVESP01
 SG_ HVESP01_CellBalance_78_1 m9 : 13|1@1+ (1,0) [0|1] ""  HVESP01
 SG_ HVESP01_CellBalance_79_1 m9 : 14|1@1+ (1,0) [0|1] ""  HVESP01
 SG_ HVESP01_CellBalance_80_1 m9 : 15|1@1+ (1,0) [0|1] ""  HVESP01
 SG_ HVESP01_CellBalance_81_1 m10 : 8|1@1+ (1,0) [0|1] ""  HVESP01
 SG_ HVESP01_CellBalance_82_1 m10 : 9|1@1+ (1,0) [0|1] ""  HVESP01
 SG_ HVESP01_CellBalance_83_1 m10 : 10|1@1+ (1,0) [0|1] ""  HVESP01
 SG_ HVESP01_CellBalance_84_1 m10 : 11|1@1+ (1,0) [0|1] ""  HVESP01
 SG_ HVESP01_CellBalance_85_1 m10 : 12|1@1+ (1,0) [0|1] ""  HVESP01
 SG_ HVESP01_CellBalance_86_1 m10 : 13|1@1+ (1,0) [0|1] ""  HVESP01
 SG_ HVESP01_CellBalance_87_1 m10 : 14|1@1+ (1,0) [0|1] ""  HVESP01
 SG_ HVESP01_CellBalance_88_1 m10 : 15|1@1+ (1,0) [0|1] ""  HVESP01
 SG_ HVESP01_CellBalance_89_1 m11 : 8|1@1+ (1,0) [0|1] ""  HVESP01
 SG_ HVESP01_CellBalance_90_1 m11 : 9|1@1+ (1,0) [0|1] ""  HVESP01
 SG_ HVESP01_CellBalance_91_1 m11 : 10|1@1+ (1,0) [0|1] ""  HVESP01
 SG_ HVESP01_CellBalance_92_1 m11 : 11|1@1+ (1,0) [0|1] ""  HVESP01
 SG_ HVESP01_CellBalance_93_1 m11 : 12|1@1+ (1,0) [0|1] ""  HVESP01
 SG_ HVESP01_CellBalance_94_1 m11 : 13|1@1+ (1,0) [0|1] ""  HVESP01
 SG_ HVESP01_CellBalance_95_1 m11 : 14|1@1+ (1,0) [0|1] ""  HVESP01
 SG_ HVESP01_CellBalance_96_1 m11 : 15|1@1+ (1,0) [0|1] ""  HVESP01
 SG_ HVESP01_CellBalance_97_1 m12 : 8|1@1+ (1,0) [0|1] ""  HVESP01
 SG_ HVESP01_CellBalance_98_1 m12 : 9|1@1+ (1,0) [0|1] ""  HVESP01
 SG_ HVESP01_CellBalance_99_1 m12 : 10|1@1+ (1,0) [0|1] ""  HVESP01
 SG_ HVESP01_CellBalance_100_1 m12 : 11|1@1+ (1,0) [0|1] ""  HVESP01
 SG_ HVESP01_CellBalance_101_1 m12 : 12|1@1+ (1,0) [0|1] ""  HVESP01
 SG_ HVESP01_CellBalance_102_1 m12 : 13|1@1+ (1,0) [0|1] ""  HVESP01
 SG_ HVESP01_CellBalance_103_1 m12 : 14|1@1+ (1,0) [0|1] ""  HVESP01
 SG_ HVESP01_CellBalance_104_1 m12 : 15|1@1+ (1,0) [0|1] ""  HVESP01
 SG_ HVESP01_CellBalance_105_1 m13 : 8|1@1+ (1,0) [0|1] ""  HVESP01
 SG_ HVESP01_CellBalance_106_1 m13 : 9|1@1+ (1,0) [0|1] ""  HVESP01
 SG_ HVESP01_CellBalance_107_1 m13 : 10|1@1+ (1,0) [0|1] ""  HVESP01
 SG_ HVESP01_CellBalance_108_1 m13 : 11|1@1+ (1,0) [0|1] ""  HVESP01
 SG_ HVESP01_CellBalance_109_1 m13 : 12|1@1+ (1,0) [0|1] ""  HVESP01
 SG_ HVESP01_CellBalance_110_1 m13 : 13|1@1+ (1,0) [0|1] ""  HVESP01
 SG_ HVESP01_CellBalance_111_1 m13 : 14|1@1+ (1,0) [0|1] ""  HVESP01
 SG_ HVESP01_CellBalance_112_1 m13 : 15|1@1+ (1,0) [0|1] ""  HVESP01
 SG_ HVESP01_CellBalance_113_1 m14 : 8|1@1+ (1,0) [0|1] ""  HVESP01
 SG_ HVESP01_CellBalance_114_1 m14 : 9|1@1+ (1,0) [0|1] ""  HVESP01
 SG_ HVESP01_CellBalance_115_1 m14 : 10|1@1+ (1,0) [0|1] ""  HVESP01
 SG_ HVESP01_CellBalance_116_1 m14 : 11|1@1+ (1,0) [0|1] ""  HVESP01
 SG_ HVESP01_CellBalance_117_1 m14 : 12|1@1+ (1,0) [0|1] ""  HVESP01
 SG_ HVESP01_CellBalance_118_1 m14 : 13|1@1+ (1,0) [0|1] ""  HVESP01
 SG_ HVESP01_CellBalance_119_1 m14 : 14|1@1+ (1,0) [0|1] ""  HVESP01
 SG_ HVESP01_CellBalance_120_1 m14 : 15|1@1+ (1,0) [0|1] ""  HVESP01
 SG_ HVESP01_CellBalance_121_1 m15 : 8|1@1+ (1,0) [0|1] ""  HVESP01
 SG_ HVESP01_CellBalance_122_1 m15 : 9|1@1+ (1,0) [0|1] ""  HVESP01
 SG_ HVESP01_CellBalance_123_1 m15 : 10|1@1+ (1,0) [0|1] ""  HVESP01
 SG_ HVESP01_CellBalance_124_1 m15 : 11|1@1+ (1,0) [0|1] ""  HVESP01
 SG_ HVESP01_CellBalance_125_1 m15 : 12|1@1+ (1,0) [0|1] ""  HVESP01
 SG_ HVESP01_CellBalance_126_1 m15 : 13|1@1+ (1,0) [0|1] ""  HVESP01
 SG_ HVESP01_CellBalance_127_1 m15 : 14|1@1+ (1,0) [0|1] ""  HVESP01
 SG_ HVESP01_CellBalance_128_1 m15 : 15|1@1+ (1,0) [0|1] ""  HVESP01
 SG_ HVESP01_CellBalance_129_1 m16 : 8|1@1+ (1,0) [0|1] ""  HVESP01
 SG_ HVESP01_CellBalance_130_1 m16 : 9|1@1+ (1,0) [0|1] ""  HVESP01
 SG_ HVESP01_CellBalance_131_1 m16 : 10|1@1+ (1,0) [0|1] ""  HVESP01
 SG_ HVESP01_CellBalance_132_1 m16 : 11|1@1+ (1,0) [0|1] ""  HVESP01
 SG_ HVESP01_CellBalance_133_1 m16 : 12|1@1+ (1,0) [0|1] ""  HVESP01
 SG_ HVESP01_CellBalance_134_1 m16 : 13|1@1+ (1,0) [0|1] ""  HVESP01
 SG_ HVESP01_CellBalance_135_1 m16 : 14|1@1+ (1,0) [0|1] ""  HVESP01
 SG_ HVESP01_CellBalance_136_1 m16 : 15|1@1+ (1,0) [0|1] ""  HVESP01
 SG_ HVESP01_CellBalance_137_1 m17 : 8|1@1+ (1,0) [0|1] ""  HVESP01
 SG_ HVESP01_CellBalance_138_1 m17 : 9|1@1+ (1,0) [0|1] ""  HVESP01
 SG_ HVESP01_CellBalance_139_1 m17 : 10|1@1+ (1,0) [0|1] ""  HVESP01
 SG_ HVESP01_CellBalance_140_1 m17 : 11|1@1+ (1,0) [0|1] ""  HVESP01
 SG_ HVESP01_CellBalance_141_1 m17 : 12|1@1+ (1,0) [0|1] ""  HVESP01
 SG_ HVESP01_CellBalance_142_1 m17 : 13|1@1+ (1,0) [0|1] ""  HVESP01
 SG_ HVESP01_CellBalance_143_1 m17 : 14|1@1+ (1,0) [0|1] ""  HVESP01
 SG_ HVESP01_CellBalance_144_1 m17 : 15|1@1+ (1,0) [0|1] ""  HVESP01
 SG_ HVESP01_CellBalance_145_1 m18 : 8|1@1+ (1,0) [0|1] ""  HVESP01
 SG_ HVESP01_CellBalance_146_1 m18 : 9|1@1+ (1,0) [0|1] ""  HVESP01
 SG_ HVESP01_CellBalance_147_1 m18 : 10|1@1+ (1,0) [0|1] ""  HVESP01
 SG_ HVESP01_CellBalance_148_1 m18 : 11|1@1+ (1,0) [0|1] ""  HVESP01
 SG_ HVESP01_CellBalance_149_1 m18 : 12|1@1+ (1,0) [0|1] ""  HVESP01
 SG_ HVESP01_CellBalance_150_1 m18 : 13|1@1+ (1,0) [0|1] ""  HVESP01
 SG_ HVESP01_CellBalance_151_1 m18 : 14|1@1+ (1,0) [0|1] ""  HVESP01
 SG_ HVESP01_CellBalance_152_1 m18 : 15|1@1+ (1,0) [0|1] ""  HVESP01
 SG_ HVESP01_CellBalance_153_1 m19 : 8|1@1+ (1,0) [0|1] ""  HVESP01
 SG_ HVESP01_CellBalance_154_1 m19 : 9|1@1+ (1,0) [0|1] ""  HVESP01
 SG_ HVESP01_CellBalance_155_1 m19 : 10|1@1+ (1,0) [0|1] ""  HVESP01
 SG_ HVESP01_CellBalance_156_1 m19 : 11|1@1+ (1,0) [0|1] ""  HVESP01
 SG_ HVESP01_CellBalance_157_1 m19 : 12|1@1+ (1,0) [0|1] ""  HVESP01
 SG_ HVESP01_CellBalance_158_1 m19 : 13|1@1+ (1,0) [0|1] ""  HVESP01
 SG_ HVESP01_CellBalance_159_1 m19 : 14|1@1+ (1,0) [0|1] ""  HVESP01
 SG_ HVESP01_CellBalance_160_1 m19 : 15|1@1+ (1,0) [0|1] ""  HVESP01
 SG_ HVESP01_CellBalance_161_1 m20 : 8|1@1+ (1,0) [0|1] ""  HVESP01
 SG_ HVESP01_CellBalance_162_1 m20 : 9|1@1+ (1,0) [0|1] ""  HVESP01
 SG_ HVESP01_CellBalance_163_1 m20 : 10|1@1+ (1,0) [0|1] ""  HVESP01
 SG_ HVESP01_CellBalance_164_1 m20 : 11|1@1+ (1,0) [0|1] ""  HVESP01
 SG_ HVESP01_CellBalance_165_1 m20 : 12|1@1+ (1,0) [0|1] ""  HVESP01
 SG_ HVESP01_CellBalance_166_1 m20 : 13|1@1+ (1,0) [0|1] ""  HVESP01
 SG_ HVESP01_CellBalance_167_1 m20 : 14|1@1+ (1,0) [0|1] ""  HVESP01
 SG_ HVESP01_CellBalance_168_1 m20 : 15|1@1+ (1,0) [0|1] ""  HVESP01
 SG_ HVESP01_CellBalance_169_1 m21 : 8|1@1+ (1,0) [0|1] ""  HVESP01
 SG_ HVESP01_CellBalance_170_1 m21 : 9|1@1+ (1,0) [0|1] ""  HVESP01
 SG_ HVESP01_CellBalance_171_1 m21 : 10|1@1+ (1,0) [0|1] ""  HVESP01
 SG_ HVESP01_CellBalance_172_1 m21 : 11|1@1+ (1,0) [0|1] ""  HVESP01
 SG_ HVESP01_CellBalance_173_1 m21 : 12|1@1+ (1,0) [0|1] ""  HVESP01
 SG_ HVESP01_CellBalance_174_1 m21 : 13|1@1+ (1,0) [0|1] ""  HVESP01
 SG_ HVESP01_CellBalance_175_1 m21 : 14|1@1+ (1,0) [0|1] ""  HVESP01
 SG_ HVESP01_CellBalance_176_1 m21 : 15|1@1+ (1,0) [0|1] ""  HVESP01
 SG_ HVESP01_CellBalance_177_1 m22 : 8|1@1+ (1,0) [0|1] ""  HVESP01
 SG_ HVESP01_CellBalance_178_1 m22 : 9|1@1+ (1,0) [0|1] ""  HVESP01
 SG_ HVESP01_CellBalance_179_1 m22 : 10|1@1+ (1,0) [0|1] ""  HVESP01
 SG_ HVESP01_CellBalance_180_1 m22 : 11|1@1+ (1,0) [0|1] ""  HVESP01
 SG_ HVESP01_CellBalance_181_1 m22 : 12|1@1+ (1,0) [0|1] ""  HVESP01
 SG_ HVESP01_CellBalance_182_1 m22 : 13|1@1+ (1,0) [0|1] ""  HVESP01
 SG_ HVESP01_CellBalance_183_1 m22 : 14|1@1+ (1,0) [0|1] ""  HVESP01
 SG_ HVESP01_CellBalance_184_1 m22 : 15|1@1+ (1,0) [0|1] ""  HVESP01
 SG_ multiplexorcb_1 M : 0|8@1+ (1,0) [0|255] ""  HVESP01

BO_ 2499743334 HVESP01_CellBalance_2: 8 HVESP01
 SG_ HVESP01_CellBalance_01_2 m0 : 8|1@1+ (1,0) [0|1] ""  HVESP01
 SG_ HVESP01_CellBalance_02_2 m0 : 9|1@1+ (1,0) [0|1] ""  HVESP01
 SG_ HVESP01_CellBalance_03_2 m0 : 10|1@1+ (1,0) [0|1] ""  HVESP01
 SG_ HVESP01_CellBalance_04_2 m0 : 11|1@1+ (1,0) [0|1] ""  HVESP01
 SG_ HVESP01_CellBalance_05_2 m0 : 12|1@1+ (1,0) [0|1] ""  HVESP01
 SG_ HVESP01_CellBalance_06_2 m0 : 13|1@1+ (1,0) [0|1] ""  HVESP01
 SG_ HVESP01_CellBalance_07_2 m0 : 14|1@1+ (1,0) [0|1] ""  HVESP01
 SG_ HVESP01_CellBalance_08_2 m0 : 15|1@1+ (1,0) [0|1] ""  HVESP01
 SG_ HVESP01_CellBalance_09_2 m1 : 8|1@1+ (1,0) [0|1] ""  HVESP01
 SG_ HVESP01_CellBalance_10_2 m1 : 9|1@1+ (1,0) [0|1] ""  HVESP01
 SG_ HVESP01_CellBalance_11_2 m1 : 10|1@1+ (1,0) [0|1] ""  HVESP01
 SG_ HVESP01_CellBalance_12_2 m1 : 11|1@1+ (1,0) [0|1] ""  HVESP01
 SG_ HVESP01_CellBalance_13_2 m1 : 12|1@1+ (1,0) [0|1] ""  HVESP01
 SG_ HVESP01_CellBalance_14_2 m1 : 13|1@1+ (1,0) [0|1] ""  HVESP01
 SG_ HVESP01_CellBalance_15_2 m1 : 14|1@1+ (1,0) [0|1] ""  HVESP01
 SG_ HVESP01_CellBalance_16_2 m1 : 15|1@1+ (1,0) [0|1] ""  HVESP01
 SG_ HVESP01_CellBalance_17_2 m2 : 8|1@1+ (1,0) [0|1] ""  HVESP01
 SG_ HVESP01_CellBalance_18_2 m2 : 9|1@1+ (1,0) [0|1] ""  HVESP01
 SG_ HVESP01_CellBalance_19_2 m2 : 10|1@1+ (1,0) [0|1] ""  HVESP01
 SG_ HVESP01_CellBalance_20_2 m2 : 11|1@1+ (1,0) [0|1] ""  HVESP01
 SG_ HVESP01_CellBalance_21_2 m2 : 12|1@1+ (1,0) [0|1] ""  HVESP01
 SG_ HVESP01_CellBalance_22_2 m2 : 13|1@1+ (1,0) [0|1] ""  HVESP01
 SG_ HVESP01_CellBalance_23_2 m2 : 14|1@1+ (1,0) [0|1] ""  HVESP01
 SG_ HVESP01_CellBalance_24_2 m2 : 15|1@1+ (1,0) [0|1] ""  HVESP01
 SG_ HVESP01_CellBalance_25_2 m3 : 8|1@1+ (1,0) [0|1] ""  HVESP01
 SG_ HVESP01_CellBalance_26_2 m3 : 9|1@1+ (1,0) [0|1] ""  HVESP01
 SG_ HVESP01_CellBalance_27_2 m3 : 10|1@1+ (1,0) [0|1] ""  HVESP01
 SG_ HVESP01_CellBalance_28_2 m3 : 11|1@1+ (1,0) [0|1] ""  HVESP01
 SG_ HVESP01_CellBalance_29_2 m3 : 12|1@1+ (1,0) [0|1] ""  HVESP01
 SG_ HVESP01_CellBalance_30_2 m3 : 13|1@1+ (1,0) [0|1] ""  HVESP01
 SG_ HVESP01_CellBalance_31_2 m3 : 14|1@1+ (1,0) [0|1] ""  HVESP01
 SG_ HVESP01_CellBalance_32_2 m3 : 15|1@1+ (1,0) [0|1] ""  HVESP01
 SG_ HVESP01_CellBalance_33_2 m4 : 8|1@1+ (1,0) [0|1] ""  HVESP01
 SG_ HVESP01_CellBalance_34_2 m4 : 9|1@1+ (1,0) [0|1] ""  HVESP01
 SG_ HVESP01_CellBalance_35_2 m4 : 10|1@1+ (1,0) [0|1] ""  HVESP01
 SG_ HVESP01_CellBalance_36_2 m4 : 11|1@1+ (1,0) [0|1] ""  HVESP01
 SG_ HVESP01_CellBalance_37_2 m4 : 12|1@1+ (1,0) [0|1] ""  HVESP01
 SG_ HVESP01_CellBalance_38_2 m4 : 13|1@1+ (1,0) [0|1] ""  HVESP01
 SG_ HVESP01_CellBalance_39_2 m4 : 14|1@1+ (1,0) [0|1] ""  HVESP01
 SG_ HVESP01_CellBalance_40_2 m4 : 15|1@1+ (1,0) [0|1] ""  HVESP01
 SG_ HVESP01_CellBalance_41_2 m5 : 8|1@1+ (1,0) [0|1] ""  HVESP01
 SG_ HVESP01_CellBalance_42_2 m5 : 9|1@1+ (1,0) [0|1] ""  HVESP01
 SG_ HVESP01_CellBalance_43_2 m5 : 10|1@1+ (1,0) [0|1] ""  HVESP01
 SG_ HVESP01_CellBalance_44_2 m5 : 11|1@1+ (1,0) [0|1] ""  HVESP01
 SG_ HVESP01_CellBalance_45_2 m5 : 12|1@1+ (1,0) [0|1] ""  HVESP01
 SG_ HVESP01_CellBalance_46_2 m5 : 13|1@1+ (1,0) [0|1] ""  HVESP01
 SG_ HVESP01_CellBalance_47_2 m5 : 14|1@1+ (1,0) [0|1] ""  HVESP01
 SG_ HVESP01_CellBalance_48_2 m5 : 15|1@1+ (1,0) [0|1] ""  HVESP01
 SG_ HVESP01_CellBalance_49_2 m6 : 8|1@1+ (1,0) [0|1] ""  HVESP01
 SG_ HVESP01_CellBalance_50_2 m6 : 9|1@1+ (1,0) [0|1] ""  HVESP01
 SG_ HVESP01_CellBalance_51_2 m6 : 10|1@1+ (1,0) [0|1] ""  HVESP01
 SG_ HVESP01_CellBalance_52_2 m6 : 11|1@1+ (1,0) [0|1] ""  HVESP01
 SG_ HVESP01_CellBalance_53_2 m6 : 12|1@1+ (1,0) [0|1] ""  HVESP01
 SG_ HVESP01_CellBalance_54_2 m6 : 13|1@1+ (1,0) [0|1] ""  HVESP01
 SG_ HVESP01_CellBalance_55_2 m6 : 14|1@1+ (1,0) [0|1] ""  HVESP01
 SG_ HVESP01_CellBalance_56_2 m6 : 15|1@1+ (1,0) [0|1] ""  HVESP01
 SG_ HVESP01_CellBalance_57_2 m7 : 8|1@1+ (1,0) [0|1] ""  HVESP01
 SG_ HVESP01_CellBalance_58_2 m7 : 9|1@1+ (1,0) [0|1] ""  HVESP01
 SG_ HVESP01_CellBalance_59_2 m7 : 10|1@1+ (1,0) [0|1] ""  HVESP01
 SG_ HVESP01_CellBalance_60_2 m7 : 11|1@1+ (1,0) [0|1] ""  HVESP01
 SG_ HVESP01_CellBalance_61_2 m7 : 12|1@1+ (1,0) [0|1] ""  HVESP01
 SG_ HVESP01_CellBalance_62_2 m7 : 13|1@1+ (1,0) [0|1] ""  HVESP01
 SG_ HVESP01_CellBalance_63_2 m7 : 14|1@1+ (1,0) [0|1] ""  HVESP01
 SG_ HVESP01_CellBalance_64_2 m7 : 15|1@1+ (1,0) [0|1] ""  HVESP01
 SG_ HVESP01_CellBalance_65_2 m8 : 8|1@1+ (1,0) [0|1] ""  HVESP01
 SG_ HVESP01_CellBalance_66_2 m8 : 9|1@1+ (1,0) [0|1] ""  HVESP01
 SG_ HVESP01_CellBalance_67_2 m8 : 10|1@1+ (1,0) [0|1] ""  HVESP01
 SG_ HVESP01_CellBalance_68_2 m8 : 11|1@1+ (1,0) [0|1] ""  HVESP01
 SG_ HVESP01_CellBalance_69_2 m8 : 12|1@1+ (1,0) [0|1] ""  HVESP01
 SG_ HVESP01_CellBalance_70_2 m8 : 13|1@1+ (1,0) [0|1] ""  HVESP01
 SG_ HVESP01_CellBalance_71_2 m8 : 14|1@1+ (1,0) [0|1] ""  HVESP01
 SG_ HVESP01_CellBalance_72_2 m8 : 15|1@1+ (1,0) [0|1] ""  HVESP01
 SG_ HVESP01_CellBalance_73_2 m9 : 8|1@1+ (1,0) [0|1] ""  HVESP01
 SG_ HVESP01_CellBalance_74_2 m9 : 9|1@1+ (1,0) [0|1] ""  HVESP01
 SG_ HVESP01_CellBalance_75_2 m9 : 10|1@1+ (1,0) [0|1] ""  HVESP01
 SG_ HVESP01_CellBalance_76_2 m9 : 11|1@1+ (1,0) [0|1] ""  HVESP01
 SG_ HVESP01_CellBalance_77_2 m9 : 12|1@1+ (1,0) [0|1] ""  HVESP01
 SG_ HVESP01_CellBalance_78_2 m9 : 13|1@1+ (1,0) [0|1] ""  HVESP01
 SG_ HVESP01_CellBalance_79_2 m9 : 14|1@1+ (1,0) [0|1] ""  HVESP01
 SG_ HVESP01_CellBalance_80_2 m9 : 15|1@1+ (1,0) [0|1] ""  HVESP01
 SG_ HVESP01_CellBalance_81_2 m10 : 8|1@1+ (1,0) [0|1] ""  HVESP01
 SG_ HVESP01_CellBalance_82_2 m10 : 9|1@1+ (1,0) [0|1] ""  HVESP01
 SG_ HVESP01_CellBalance_83_2 m10 : 10|1@1+ (1,0) [0|1] ""  HVESP01
 SG_ HVESP01_CellBalance_84_2 m10 : 11|1@1+ (1,0) [0|1] ""  HVESP01
 SG_ HVESP01_CellBalance_85_2 m10 : 12|1@1+ (1,0) [0|1] ""  HVESP01
 SG_ HVESP01_CellBalance_86_2 m10 : 13|1@1+ (1,0) [0|1] ""  HVESP01
 SG_ HVESP01_CellBalance_87_2 m10 : 14|1@1+ (1,0) [0|1] ""  HVESP01
 SG_ HVESP01_CellBalance_88_2 m10 : 15|1@1+ (1,0) [0|1] ""  HVESP01
 SG_ HVESP01_CellBalance_89_2 m11 : 8|1@1+ (1,0) [0|1] ""  HVESP01
 SG_ HVESP01_CellBalance_90_2 m11 : 9|1@1+ (1,0) [0|1] ""  HVESP01
 SG_ HVESP01_CellBalance_91_2 m11 : 10|1@1+ (1,0) [0|1] ""  HVESP01
 SG_ HVESP01_CellBalance_92_2 m11 : 11|1@1+ (1,0) [0|1] ""  HVESP01
 SG_ HVESP01_CellBalance_93_2 m11 : 12|1@1+ (1,0) [0|1] ""  HVESP01
 SG_ HVESP01_CellBalance_94_2 m11 : 13|1@1+ (1,0) [0|1] ""  HVESP01
 SG_ HVESP01_CellBalance_95_2 m11 : 14|1@1+ (1,0) [0|1] ""  HVESP01
 SG_ HVESP01_CellBalance_96_2 m11 : 15|1@1+ (1,0) [0|1] ""  HVESP01
 SG_ HVESP01_CellBalance_97_2 m12 : 8|1@1+ (1,0) [0|1] ""  HVESP01
 SG_ HVESP01_CellBalance_98_2 m12 : 9|1@1+ (1,0) [0|1] ""  HVESP01
 SG_ HVESP01_CellBalance_99_2 m12 : 10|1@1+ (1,0) [0|1] ""  HVESP01
 SG_ HVESP01_CellBalance_100_2 m12 : 11|1@1+ (1,0) [0|1] ""  HVESP01
 SG_ HVESP01_CellBalance_101_2 m12 : 12|1@1+ (1,0) [0|1] ""  HVESP01
 SG_ HVESP01_CellBalance_102_2 m12 : 13|1@1+ (1,0) [0|1] ""  HVESP01
 SG_ HVESP01_CellBalance_103_2 m12 : 14|1@1+ (1,0) [0|1] ""  HVESP01
 SG_ HVESP01_CellBalance_104_2 m12 : 15|1@1+ (1,0) [0|1] ""  HVESP01
 SG_ HVESP01_CellBalance_105_2 m13 : 8|1@1+ (1,0) [0|1] ""  HVESP01
 SG_ HVESP01_CellBalance_106_2 m13 : 9|1@1+ (1,0) [0|1] ""  HVESP01
 SG_ HVESP01_CellBalance_107_2 m13 : 10|1@1+ (1,0) [0|1] ""  HVESP01
 SG_ HVESP01_CellBalance_108_2 m13 : 11|1@1+ (1,0) [0|1] ""  HVESP01
 SG_ HVESP01_CellBalance_109_2 m13 : 12|1@1+ (1,0) [0|1] ""  HVESP01
 SG_ HVESP01_CellBalance_110_2 m13 : 13|1@1+ (1,0) [0|1] ""  HVESP01
 SG_ HVESP01_CellBalance_111_2 m13 : 14|1@1+ (1,0) [0|1] ""  HVESP01
 SG_ HVESP01_CellBalance_112_2 m13 : 15|1@1+ (1,0) [0|1] ""  HVESP01
 SG_ HVESP01_CellBalance_113_2 m14 : 8|1@1+ (1,0) [0|1] ""  HVESP01
 SG_ HVESP01_CellBalance_114_2 m14 : 9|1@1+ (1,0) [0|1] ""  HVESP01
 SG_ HVESP01_CellBalance_115_2 m14 : 10|1@1+ (1,0) [0|1] ""  HVESP01
 SG_ HVESP01_CellBalance_116_2 m14 : 11|1@1+ (1,0) [0|1] ""  HVESP01
 SG_ HVESP01_CellBalance_117_2 m14 : 12|1@1+ (1,0) [0|1] ""  HVESP01
 SG_ HVESP01_CellBalance_118_2 m14 : 13|1@1+ (1,0) [0|1] ""  HVESP01
 SG_ HVESP01_CellBalance_119_2 m14 : 14|1@1+ (1,0) [0|1] ""  HVESP01
 SG_ HVESP01_CellBalance_120_2 m14 : 15|1@1+ (1,0) [0|1] ""  HVESP01
 SG_ HVESP01_CellBalance_121_2 m15 : 8|1@1+ (1,0) [0|1] ""  HVESP01
 SG_ HVESP01_CellBalance_122_2 m15 : 9|1@1+ (1,0) [0|1] ""  HVESP01
 SG_ HVESP01_CellBalance_123_2 m15 : 10|1@1+ (1,0) [0|1] ""  HVESP01
 SG_ HVESP01_CellBalance_124_2 m15 : 11|1@1+ (1,0) [0|1] ""  HVESP01
 SG_ HVESP01_CellBalance_125_2 m15 : 12|1@1+ (1,0) [0|1] ""  HVESP01
 SG_ HVESP01_CellBalance_126_2 m15 : 13|1@1+ (1,0) [0|1] ""  HVESP01
 SG_ HVESP01_CellBalance_127_2 m15 : 14|1@1+ (1,0) [0|1] ""  HVESP01
 SG_ HVESP01_CellBalance_128_2 m15 : 15|1@1+ (1,0) [0|1] ""  HVESP01
 SG_ HVESP01_CellBalance_129_2 m16 : 8|1@1+ (1,0) [0|1] ""  HVESP01
 SG_ HVESP01_CellBalance_130_2 m16 : 9|1@1+ (1,0) [0|1] ""  HVESP01
 SG_ HVESP01_CellBalance_131_2 m16 : 10|1@1+ (1,0) [0|1] ""  HVESP01
 SG_ HVESP01_CellBalance_132_2 m16 : 11|1@1+ (1,0) [0|1] ""  HVESP01
 SG_ HVESP01_CellBalance_133_2 m16 : 12|1@1+ (1,0) [0|1] ""  HVESP01
 SG_ HVESP01_CellBalance_134_2 m16 : 13|1@1+ (1,0) [0|1] ""  HVESP01
 SG_ HVESP01_CellBalance_135_2 m16 : 14|1@1+ (1,0) [0|1] ""  HVESP01
 SG_ HVESP01_CellBalance_136_2 m16 : 15|1@1+ (1,0) [0|1] ""  HVESP01
 SG_ HVESP01_CellBalance_137_2 m17 : 8|1@1+ (1,0) [0|1] ""  HVESP01
 SG_ HVESP01_CellBalance_138_2 m17 : 9|1@1+ (1,0) [0|1] ""  HVESP01
 SG_ HVESP01_CellBalance_139_2 m17 : 10|1@1+ (1,0) [0|1] ""  HVESP01
 SG_ HVESP01_CellBalance_140_2 m17 : 11|1@1+ (1,0) [0|1] ""  HVESP01
 SG_ HVESP01_CellBalance_141_2 m17 : 12|1@1+ (1,0) [0|1] ""  HVESP01
 SG_ HVESP01_CellBalance_142_2 m17 : 13|1@1+ (1,0) [0|1] ""  HVESP01
 SG_ HVESP01_CellBalance_143_2 m17 : 14|1@1+ (1,0) [0|1] ""  HVESP01
 SG_ HVESP01_CellBalance_144_2 m17 : 15|1@1+ (1,0) [0|1] ""  HVESP01
 SG_ HVESP01_CellBalance_145_2 m18 : 8|1@1+ (1,0) [0|1] ""  HVESP01
 SG_ HVESP01_CellBalance_146_2 m18 : 9|1@1+ (1,0) [0|1] ""  HVESP01
 SG_ HVESP01_CellBalance_147_2 m18 : 10|1@1+ (1,0) [0|1] ""  HVESP01
 SG_ HVESP01_CellBalance_148_2 m18 : 11|1@1+ (1,0) [0|1] ""  HVESP01
 SG_ HVESP01_CellBalance_149_2 m18 : 12|1@1+ (1,0) [0|1] ""  HVESP01
 SG_ HVESP01_CellBalance_150_2 m18 : 13|1@1+ (1,0) [0|1] ""  HVESP01
 SG_ HVESP01_CellBalance_151_2 m18 : 14|1@1+ (1,0) [0|1] ""  HVESP01
 SG_ HVESP01_CellBalance_152_2 m18 : 15|1@1+ (1,0) [0|1] ""  HVESP01
 SG_ HVESP01_CellBalance_153_2 m19 : 8|1@1+ (1,0) [0|1] ""  HVESP01
 SG_ HVESP01_CellBalance_154_2 m19 : 9|1@1+ (1,0) [0|1] ""  HVESP01
 SG_ HVESP01_CellBalance_155_2 m19 : 10|1@1+ (1,0) [0|1] ""  HVESP01
 SG_ HVESP01_CellBalance_156_2 m19 : 11|1@1+ (1,0) [0|1] ""  HVESP01
 SG_ HVESP01_CellBalance_157_2 m19 : 12|1@1+ (1,0) [0|1] ""  HVESP01
 SG_ HVESP01_CellBalance_158_2 m19 : 13|1@1+ (1,0) [0|1] ""  HVESP01
 SG_ HVESP01_CellBalance_159_2 m19 : 14|1@1+ (1,0) [0|1] ""  HVESP01
 SG_ HVESP01_CellBalance_160_2 m19 : 15|1@1+ (1,0) [0|1] ""  HVESP01
 SG_ HVESP01_CellBalance_161_2 m20 : 8|1@1+ (1,0) [0|1] ""  HVESP01
 SG_ HVESP01_CellBalance_162_2 m20 : 9|1@1+ (1,0) [0|1] ""  HVESP01
 SG_ HVESP01_CellBalance_163_2 m20 : 10|1@1+ (1,0) [0|1] ""  HVESP01
 SG_ HVESP01_CellBalance_164_2 m20 : 11|1@1+ (1,0) [0|1] ""  HVESP01
 SG_ HVESP01_CellBalance_165_2 m20 : 12|1@1+ (1,0) [0|1] ""  HVESP01
 SG_ HVESP01_CellBalance_166_2 m20 : 13|1@1+ (1,0) [0|1] ""  HVESP01
 SG_ HVESP01_CellBalance_167_2 m20 : 14|1@1+ (1,0) [0|1] ""  HVESP01
 SG_ HVESP01_CellBalance_168_2 m20 : 15|1@1+ (1,0) [0|1] ""  HVESP01
 SG_ HVESP01_CellBalance_169_2 m21 : 8|1@1+ (1,0) [0|1] ""  HVESP01
 SG_ HVESP01_CellBalance_170_2 m21 : 9|1@1+ (1,0) [0|1] ""  HVESP01
 SG_ HVESP01_CellBalance_171_2 m21 : 10|1@1+ (1,0) [0|1] ""  HVESP01
 SG_ HVESP01_CellBalance_172_2 m21 : 11|1@1+ (1,0) [0|1] ""  HVESP01
 SG_ HVESP01_CellBalance_173_2 m21 : 12|1@1+ (1,0) [0|1] ""  HVESP01
 SG_ HVESP01_CellBalance_174_2 m21 : 13|1@1+ (1,0) [0|1] ""  HVESP01
 SG_ HVESP01_CellBalance_175_2 m21 : 14|1@1+ (1,0) [0|1] ""  HVESP01
 SG_ HVESP01_CellBalance_176_2 m21 : 15|1@1+ (1,0) [0|1] ""  HVESP01
 SG_ HVESP01_CellBalance_177_2 m22 : 8|1@1+ (1,0) [0|1] ""  HVESP01
 SG_ HVESP01_CellBalance_178_2 m22 : 9|1@1+ (1,0) [0|1] ""  HVESP01
 SG_ HVESP01_CellBalance_179_2 m22 : 10|1@1+ (1,0) [0|1] ""  HVESP01
 SG_ HVESP01_CellBalance_180_2 m22 : 11|1@1+ (1,0) [0|1] ""  HVESP01
 SG_ HVESP01_CellBalance_181_2 m22 : 12|1@1+ (1,0) [0|1] ""  HVESP01
 SG_ HVESP01_CellBalance_182_2 m22 : 13|1@1+ (1,0) [0|1] ""  HVESP01
 SG_ HVESP01_CellBalance_183_2 m22 : 14|1@1+ (1,0) [0|1] ""  HVESP01
 SG_ HVESP01_CellBalance_184_2 m22 : 15|1@1+ (1,0) [0|1] ""  HVESP01
 SG_ multiplexorcb_2 M : 0|8@1+ (1,0) [0|255] ""  HVESP01

BO_ 2499743335 HVESP01_CellBalance_3: 8 HVESP01
 SG_ HVESP01_CellBalance_01_3 m0 : 8|1@1+ (1,0) [0|1] ""  HVESP01
 SG_ HVESP01_CellBalance_02_3 m0 : 9|1@1+ (1,0) [0|1] ""  HVESP01
 SG_ HVESP01_CellBalance_03_3 m0 : 10|1@1+ (1,0) [0|1] ""  HVESP01
 SG_ HVESP01_CellBalance_04_3 m0 : 11|1@1+ (1,0) [0|1] ""  HVESP01
 SG_ HVESP01_CellBalance_05_3 m0 : 12|1@1+ (1,0) [0|1] ""  HVESP01
 SG_ HVESP01_CellBalance_06_3 m0 : 13|1@1+ (1,0) [0|1] ""  HVESP01
 SG_ HVESP01_CellBalance_07_3 m0 : 14|1@1+ (1,0) [0|1] ""  HVESP01
 SG_ HVESP01_CellBalance_08_3 m0 : 15|1@1+ (1,0) [0|1] ""  HVESP01
 SG_ HVESP01_CellBalance_09_3 m1 : 8|1@1+ (1,0) [0|1] ""  HVESP01
 SG_ HVESP01_CellBalance_10_3 m1 : 9|1@1+ (1,0) [0|1] ""  HVESP01
 SG_ HVESP01_CellBalance_11_3 m1 : 10|1@1+ (1,0) [0|1] ""  HVESP01
 SG_ HVESP01_CellBalance_12_3 m1 : 11|1@1+ (1,0) [0|1] ""  HVESP01
 SG_ HVESP01_CellBalance_13_3 m1 : 12|1@1+ (1,0) [0|1] ""  HVESP01
 SG_ HVESP01_CellBalance_14_3 m1 : 13|1@1+ (1,0) [0|1] ""  HVESP01
 SG_ HVESP01_CellBalance_15_3 m1 : 14|1@1+ (1,0) [0|1] ""  HVESP01
 SG_ HVESP01_CellBalance_16_3 m1 : 15|1@1+ (1,0) [0|1] ""  HVESP01
 SG_ HVESP01_CellBalance_17_3 m2 : 8|1@1+ (1,0) [0|1] ""  HVESP01
 SG_ HVESP01_CellBalance_18_3 m2 : 9|1@1+ (1,0) [0|1] ""  HVESP01
 SG_ HVESP01_CellBalance_19_3 m2 : 10|1@1+ (1,0) [0|1] ""  HVESP01
 SG_ HVESP01_CellBalance_20_3 m2 : 11|1@1+ (1,0) [0|1] ""  HVESP01
 SG_ HVESP01_CellBalance_21_3 m2 : 12|1@1+ (1,0) [0|1] ""  HVESP01
 SG_ HVESP01_CellBalance_22_3 m2 : 13|1@1+ (1,0) [0|1] ""  HVESP01
 SG_ HVESP01_CellBalance_23_3 m2 : 14|1@1+ (1,0) [0|1] ""  HVESP01
 SG_ HVESP01_CellBalance_24_3 m2 : 15|1@1+ (1,0) [0|1] ""  HVESP01
 SG_ HVESP01_CellBalance_25_3 m3 : 8|1@1+ (1,0) [0|1] ""  HVESP01
 SG_ HVESP01_CellBalance_26_3 m3 : 9|1@1+ (1,0) [0|1] ""  HVESP01
 SG_ HVESP01_CellBalance_27_3 m3 : 10|1@1+ (1,0) [0|1] ""  HVESP01
 SG_ HVESP01_CellBalance_28_3 m3 : 11|1@1+ (1,0) [0|1] ""  HVESP01
 SG_ HVESP01_CellBalance_29_3 m3 : 12|1@1+ (1,0) [0|1] ""  HVESP01
 SG_ HVESP01_CellBalance_30_3 m3 : 13|1@1+ (1,0) [0|1] ""  HVESP01
 SG_ HVESP01_CellBalance_31_3 m3 : 14|1@1+ (1,0) [0|1] ""  HVESP01
 SG_ HVESP01_CellBalance_32_3 m3 : 15|1@1+ (1,0) [0|1] ""  HVESP01
 SG_ HVESP01_CellBalance_33_3 m4 : 8|1@1+ (1,0) [0|1] ""  HVESP01
 SG_ HVESP01_CellBalance_34_3 m4 : 9|1@1+ (1,0) [0|1] ""  HVESP01
 SG_ HVESP01_CellBalance_35_3 m4 : 10|1@1+ (1,0) [0|1] ""  HVESP01
 SG_ HVESP01_CellBalance_36_3 m4 : 11|1@1+ (1,0) [0|1] ""  HVESP01
 SG_ HVESP01_CellBalance_37_3 m4 : 12|1@1+ (1,0) [0|1] ""  HVESP01
 SG_ HVESP01_CellBalance_38_3 m4 : 13|1@1+ (1,0) [0|1] ""  HVESP01
 SG_ HVESP01_CellBalance_39_3 m4 : 14|1@1+ (1,0) [0|1] ""  HVESP01
 SG_ HVESP01_CellBalance_40_3 m4 : 15|1@1+ (1,0) [0|1] ""  HVESP01
 SG_ HVESP01_CellBalance_41_3 m5 : 8|1@1+ (1,0) [0|1] ""  HVESP01
 SG_ HVESP01_CellBalance_42_3 m5 : 9|1@1+ (1,0) [0|1] ""  HVESP01
 SG_ HVESP01_CellBalance_43_3 m5 : 10|1@1+ (1,0) [0|1] ""  HVESP01
 SG_ HVESP01_CellBalance_44_3 m5 : 11|1@1+ (1,0) [0|1] ""  HVESP01
 SG_ HVESP01_CellBalance_45_3 m5 : 12|1@1+ (1,0) [0|1] ""  HVESP01
 SG_ HVESP01_CellBalance_46_3 m5 : 13|1@1+ (1,0) [0|1] ""  HVESP01
 SG_ HVESP01_CellBalance_47_3 m5 : 14|1@1+ (1,0) [0|1] ""  HVESP01
 SG_ HVESP01_CellBalance_48_3 m5 : 15|1@1+ (1,0) [0|1] ""  HVESP01
 SG_ HVESP01_CellBalance_49_3 m6 : 8|1@1+ (1,0) [0|1] ""  HVESP01
 SG_ HVESP01_CellBalance_50_3 m6 : 9|1@1+ (1,0) [0|1] ""  HVESP01
 SG_ HVESP01_CellBalance_51_3 m6 : 10|1@1+ (1,0) [0|1] ""  HVESP01
 SG_ HVESP01_CellBalance_52_3 m6 : 11|1@1+ (1,0) [0|1] ""  HVESP01
 SG_ HVESP01_CellBalance_53_3 m6 : 12|1@1+ (1,0) [0|1] ""  HVESP01
 SG_ HVESP01_CellBalance_54_3 m6 : 13|1@1+ (1,0) [0|1] ""  HVESP01
 SG_ HVESP01_CellBalance_55_3 m6 : 14|1@1+ (1,0) [0|1] ""  HVESP01
 SG_ HVESP01_CellBalance_56_3 m6 : 15|1@1+ (1,0) [0|1] ""  HVESP01
 SG_ HVESP01_CellBalance_57_3 m7 : 8|1@1+ (1,0) [0|1] ""  HVESP01
 SG_ HVESP01_CellBalance_58_3 m7 : 9|1@1+ (1,0) [0|1] ""  HVESP01
 SG_ HVESP01_CellBalance_59_3 m7 : 10|1@1+ (1,0) [0|1] ""  HVESP01
 SG_ HVESP01_CellBalance_60_3 m7 : 11|1@1+ (1,0) [0|1] ""  HVESP01
 SG_ HVESP01_CellBalance_61_3 m7 : 12|1@1+ (1,0) [0|1] ""  HVESP01
 SG_ HVESP01_CellBalance_62_3 m7 : 13|1@1+ (1,0) [0|1] ""  HVESP01
 SG_ HVESP01_CellBalance_63_3 m7 : 14|1@1+ (1,0) [0|1] ""  HVESP01
 SG_ HVESP01_CellBalance_64_3 m7 : 15|1@1+ (1,0) [0|1] ""  HVESP01
 SG_ HVESP01_CellBalance_65_3 m8 : 8|1@1+ (1,0) [0|1] ""  HVESP01
 SG_ HVESP01_CellBalance_66_3 m8 : 9|1@1+ (1,0) [0|1] ""  HVESP01
 SG_ HVESP01_CellBalance_67_3 m8 : 10|1@1+ (1,0) [0|1] ""  HVESP01
 SG_ HVESP01_CellBalance_68_3 m8 : 11|1@1+ (1,0) [0|1] ""  HVESP01
 SG_ HVESP01_CellBalance_69_3 m8 : 12|1@1+ (1,0) [0|1] ""  HVESP01
 SG_ HVESP01_CellBalance_70_3 m8 : 13|1@1+ (1,0) [0|1] ""  HVESP01
 SG_ HVESP01_CellBalance_71_3 m8 : 14|1@1+ (1,0) [0|1] ""  HVESP01
 SG_ HVESP01_CellBalance_72_3 m8 : 15|1@1+ (1,0) [0|1] ""  HVESP01
 SG_ HVESP01_CellBalance_73_3 m9 : 8|1@1+ (1,0) [0|1] ""  HVESP01
 SG_ HVESP01_CellBalance_74_3 m9 : 9|1@1+ (1,0) [0|1] ""  HVESP01
 SG_ HVESP01_CellBalance_75_3 m9 : 10|1@1+ (1,0) [0|1] ""  HVESP01
 SG_ HVESP01_CellBalance_76_3 m9 : 11|1@1+ (1,0) [0|1] ""  HVESP01
 SG_ HVESP01_CellBalance_77_3 m9 : 12|1@1+ (1,0) [0|1] ""  HVESP01
 SG_ HVESP01_CellBalance_78_3 m9 : 13|1@1+ (1,0) [0|1] ""  HVESP01
 SG_ HVESP01_CellBalance_79_3 m9 : 14|1@1+ (1,0) [0|1] ""  HVESP01
 SG_ HVESP01_CellBalance_80_3 m9 : 15|1@1+ (1,0) [0|1] ""  HVESP01
 SG_ HVESP01_CellBalance_81_3 m10 : 8|1@1+ (1,0) [0|1] ""  HVESP01
 SG_ HVESP01_CellBalance_82_3 m10 : 9|1@1+ (1,0) [0|1] ""  HVESP01
 SG_ HVESP01_CellBalance_83_3 m10 : 10|1@1+ (1,0) [0|1] ""  HVESP01
 SG_ HVESP01_CellBalance_84_3 m10 : 11|1@1+ (1,0) [0|1] ""  HVESP01
 SG_ HVESP01_CellBalance_85_3 m10 : 12|1@1+ (1,0) [0|1] ""  HVESP01
 SG_ HVESP01_CellBalance_86_3 m10 : 13|1@1+ (1,0) [0|1] ""  HVESP01
 SG_ HVESP01_CellBalance_87_3 m10 : 14|1@1+ (1,0) [0|1] ""  HVESP01
 SG_ HVESP01_CellBalance_88_3 m10 : 15|1@1+ (1,0) [0|1] ""  HVESP01
 SG_ HVESP01_CellBalance_89_3 m11 : 8|1@1+ (1,0) [0|1] ""  HVESP01
 SG_ HVESP01_CellBalance_90_3 m11 : 9|1@1+ (1,0) [0|1] ""  HVESP01
 SG_ HVESP01_CellBalance_91_3 m11 : 10|1@1+ (1,0) [0|1] ""  HVESP01
 SG_ HVESP01_CellBalance_92_3 m11 : 11|1@1+ (1,0) [0|1] ""  HVESP01
 SG_ HVESP01_CellBalance_93_3 m11 : 12|1@1+ (1,0) [0|1] ""  HVESP01
 SG_ HVESP01_CellBalance_94_3 m11 : 13|1@1+ (1,0) [0|1] ""  HVESP01
 SG_ HVESP01_CellBalance_95_3 m11 : 14|1@1+ (1,0) [0|1] ""  HVESP01
 SG_ HVESP01_CellBalance_96_3 m11 : 15|1@1+ (1,0) [0|1] ""  HVESP01
 SG_ HVESP01_CellBalance_97_3 m12 : 8|1@1+ (1,0) [0|1] ""  HVESP01
 SG_ HVESP01_CellBalance_98_3 m12 : 9|1@1+ (1,0) [0|1] ""  HVESP01
 SG_ HVESP01_CellBalance_99_3 m12 : 10|1@1+ (1,0) [0|1] ""  HVESP01
 SG_ HVESP01_CellBalance_100_3 m12 : 11|1@1+ (1,0) [0|1] ""  HVESP01
 SG_ HVESP01_CellBalance_101_3 m12 : 12|1@1+ (1,0) [0|1] ""  HVESP01
 SG_ HVESP01_CellBalance_102_3 m12 : 13|1@1+ (1,0) [0|1] ""  HVESP01
 SG_ HVESP01_CellBalance_103_3 m12 : 14|1@1+ (1,0) [0|1] ""  HVESP01
 SG_ HVESP01_CellBalance_104_3 m12 : 15|1@1+ (1,0) [0|1] ""  HVESP01
 SG_ HVESP01_CellBalance_105_3 m13 : 8|1@1+ (1,0) [0|1] ""  HVESP01
 SG_ HVESP01_CellBalance_106_3 m13 : 9|1@1+ (1,0) [0|1] ""  HVESP01
 SG_ HVESP01_CellBalance_107_3 m13 : 10|1@1+ (1,0) [0|1] ""  HVESP01
 SG_ HVESP01_CellBalance_108_3 m13 : 11|1@1+ (1,0) [0|1] ""  HVESP01
 SG_ HVESP01_CellBalance_109_3 m13 : 12|1@1+ (1,0) [0|1] ""  HVESP01
 SG_ HVESP01_CellBalance_110_3 m13 : 13|1@1+ (1,0) [0|1] ""  HVESP01
 SG_ HVESP01_CellBalance_111_3 m13 : 14|1@1+ (1,0) [0|1] ""  HVESP01
 SG_ HVESP01_CellBalance_112_3 m13 : 15|1@1+ (1,0) [0|1] ""  HVESP01
 SG_ HVESP01_CellBalance_113_3 m14 : 8|1@1+ (1,0) [0|1] ""  HVESP01
 SG_ HVESP01_CellBalance_114_3 m14 : 9|1@1+ (1,0) [0|1] ""  HVESP01
 SG_ HVESP01_CellBalance_115_3 m14 : 10|1@1+ (1,0) [0|1] ""  HVESP01
 SG_ HVESP01_CellBalance_116_3 m14 : 11|1@1+ (1,0) [0|1] ""  HVESP01
 SG_ HVESP01_CellBalance_117_3 m14 : 12|1@1+ (1,0) [0|1] ""  HVESP01
 SG_ HVESP01_CellBalance_118_3 m14 : 13|1@1+ (1,0) [0|1] ""  HVESP01
 SG_ HVESP01_CellBalance_119_3 m14 : 14|1@1+ (1,0) [0|1] ""  HVESP01
 SG_ HVESP01_CellBalance_120_3 m14 : 15|1@1+ (1,0) [0|1] ""  HVESP01
 SG_ HVESP01_CellBalance_121_3 m15 : 8|1@1+ (1,0) [0|1] ""  HVESP01
 SG_ HVESP01_CellBalance_122_3 m15 : 9|1@1+ (1,0) [0|1] ""  HVESP01
 SG_ HVESP01_CellBalance_123_3 m15 : 10|1@1+ (1,0) [0|1] ""  HVESP01
 SG_ HVESP01_CellBalance_124_3 m15 : 11|1@1+ (1,0) [0|1] ""  HVESP01
 SG_ HVESP01_CellBalance_125_3 m15 : 12|1@1+ (1,0) [0|1] ""  HVESP01
 SG_ HVESP01_CellBalance_126_3 m15 : 13|1@1+ (1,0) [0|1] ""  HVESP01
 SG_ HVESP01_CellBalance_127_3 m15 : 14|1@1+ (1,0) [0|1] ""  HVESP01
 SG_ HVESP01_CellBalance_128_3 m15 : 15|1@1+ (1,0) [0|1] ""  HVESP01
 SG_ HVESP01_CellBalance_129_3 m16 : 8|1@1+ (1,0) [0|1] ""  HVESP01
 SG_ HVESP01_CellBalance_130_3 m16 : 9|1@1+ (1,0) [0|1] ""  HVESP01
 SG_ HVESP01_CellBalance_131_3 m16 : 10|1@1+ (1,0) [0|1] ""  HVESP01
 SG_ HVESP01_CellBalance_132_3 m16 : 11|1@1+ (1,0) [0|1] ""  HVESP01
 SG_ HVESP01_CellBalance_133_3 m16 : 12|1@1+ (1,0) [0|1] ""  HVESP01
 SG_ HVESP01_CellBalance_134_3 m16 : 13|1@1+ (1,0) [0|1] ""  HVESP01
 SG_ HVESP01_CellBalance_135_3 m16 : 14|1@1+ (1,0) [0|1] ""  HVESP01
 SG_ HVESP01_CellBalance_136_3 m16 : 15|1@1+ (1,0) [0|1] ""  HVESP01
 SG_ HVESP01_CellBalance_137_3 m17 : 8|1@1+ (1,0) [0|1] ""  HVESP01
 SG_ HVESP01_CellBalance_138_3 m17 : 9|1@1+ (1,0) [0|1] ""  HVESP01
 SG_ HVESP01_CellBalance_139_3 m17 : 10|1@1+ (1,0) [0|1] ""  HVESP01
 SG_ HVESP01_CellBalance_140_3 m17 : 11|1@1+ (1,0) [0|1] ""  HVESP01
 SG_ HVESP01_CellBalance_141_3 m17 : 12|1@1+ (1,0) [0|1] ""  HVESP01
 SG_ HVESP01_CellBalance_142_3 m17 : 13|1@1+ (1,0) [0|1] ""  HVESP01
 SG_ HVESP01_CellBalance_143_3 m17 : 14|1@1+ (1,0) [0|1] ""  HVESP01
 SG_ HVESP01_CellBalance_144_3 m17 : 15|1@1+ (1,0) [0|1] ""  HVESP01
 SG_ HVESP01_CellBalance_145_3 m18 : 8|1@1+ (1,0) [0|1] ""  HVESP01
 SG_ HVESP01_CellBalance_146_3 m18 : 9|1@1+ (1,0) [0|1] ""  HVESP01
 SG_ HVESP01_CellBalance_147_3 m18 : 10|1@1+ (1,0) [0|1] ""  HVESP01
 SG_ HVESP01_CellBalance_148_3 m18 : 11|1@1+ (1,0) [0|1] ""  HVESP01
 SG_ HVESP01_CellBalance_149_3 m18 : 12|1@1+ (1,0) [0|1] ""  HVESP01
 SG_ HVESP01_CellBalance_150_3 m18 : 13|1@1+ (1,0) [0|1] ""  HVESP01
 SG_ HVESP01_CellBalance_151_3 m18 : 14|1@1+ (1,0) [0|1] ""  HVESP01
 SG_ HVESP01_CellBalance_152_3 m18 : 15|1@1+ (1,0) [0|1] ""  HVESP01
 SG_ HVESP01_CellBalance_153_3 m19 : 8|1@1+ (1,0) [0|1] ""  HVESP01
 SG_ HVESP01_CellBalance_154_3 m19 : 9|1@1+ (1,0) [0|1] ""  HVESP01
 SG_ HVESP01_CellBalance_155_3 m19 : 10|1@1+ (1,0) [0|1] ""  HVESP01
 SG_ HVESP01_CellBalance_156_3 m19 : 11|1@1+ (1,0) [0|1] ""  HVESP01
 SG_ HVESP01_CellBalance_157_3 m19 : 12|1@1+ (1,0) [0|1] ""  HVESP01
 SG_ HVESP01_CellBalance_158_3 m19 : 13|1@1+ (1,0) [0|1] ""  HVESP01
 SG_ HVESP01_CellBalance_159_3 m19 : 14|1@1+ (1,0) [0|1] ""  HVESP01
 SG_ HVESP01_CellBalance_160_3 m19 : 15|1@1+ (1,0) [0|1] ""  HVESP01
 SG_ HVESP01_CellBalance_161_3 m20 : 8|1@1+ (1,0) [0|1] ""  HVESP01
 SG_ HVESP01_CellBalance_162_3 m20 : 9|1@1+ (1,0) [0|1] ""  HVESP01
 SG_ HVESP01_CellBalance_163_3 m20 : 10|1@1+ (1,0) [0|1] ""  HVESP01
 SG_ HVESP01_CellBalance_164_3 m20 : 11|1@1+ (1,0) [0|1] ""  HVESP01
 SG_ HVESP01_CellBalance_165_3 m20 : 12|1@1+ (1,0) [0|1] ""  HVESP01
 SG_ HVESP01_CellBalance_166_3 m20 : 13|1@1+ (1,0) [0|1] ""  HVESP01
 SG_ HVESP01_CellBalance_167_3 m20 : 14|1@1+ (1,0) [0|1] ""  HVESP01
 SG_ HVESP01_CellBalance_168_3 m20 : 15|1@1+ (1,0) [0|1] ""  HVESP01
 SG_ HVESP01_CellBalance_169_3 m21 : 8|1@1+ (1,0) [0|1] ""  HVESP01
 SG_ HVESP01_CellBalance_170_3 m21 : 9|1@1+ (1,0) [0|1] ""  HVESP01
 SG_ HVESP01_CellBalance_171_3 m21 : 10|1@1+ (1,0) [0|1] ""  HVESP01
 SG_ HVESP01_CellBalance_172_3 m21 : 11|1@1+ (1,0) [0|1] ""  HVESP01
 SG_ HVESP01_CellBalance_173_3 m21 : 12|1@1+ (1,0) [0|1] ""  HVESP01
 SG_ HVESP01_CellBalance_174_3 m21 : 13|1@1+ (1,0) [0|1] ""  HVESP01
 SG_ HVESP01_CellBalance_175_3 m21 : 14|1@1+ (1,0) [0|1] ""  HVESP01
 SG_ HVESP01_CellBalance_176_3 m21 : 15|1@1+ (1,0) [0|1] ""  HVESP01
 SG_ HVESP01_CellBalance_177_3 m22 : 8|1@1+ (1,0) [0|1] ""  HVESP01
 SG_ HVESP01_CellBalance_178_3 m22 : 9|1@1+ (1,0) [0|1] ""  HVESP01
 SG_ HVESP01_CellBalance_179_3 m22 : 10|1@1+ (1,0) [0|1] ""  HVESP01
 SG_ HVESP01_CellBalance_180_3 m22 : 11|1@1+ (1,0) [0|1] ""  HVESP01
 SG_ HVESP01_CellBalance_181_3 m22 : 12|1@1+ (1,0) [0|1] ""  HVESP01
 SG_ HVESP01_CellBalance_182_3 m22 : 13|1@1+ (1,0) [0|1] ""  HVESP01
 SG_ HVESP01_CellBalance_183_3 m22 : 14|1@1+ (1,0) [0|1] ""  HVESP01
 SG_ HVESP01_CellBalance_184_3 m22 : 15|1@1+ (1,0) [0|1] ""  HVESP01
 SG_ multiplexorcb_3 M : 0|8@1+ (1,0) [0|255] ""  HVESP01

BO_ 2499743336 HVESP01_CellBalance_4: 8 HVESP01
 SG_ HVESP01_CellBalance_01_4 m0 : 8|1@1+ (1,0) [0|1] ""  HVESP01
 SG_ HVESP01_CellBalance_02_4 m0 : 9|1@1+ (1,0) [0|1] ""  HVESP01
 SG_ HVESP01_CellBalance_03_4 m0 : 10|1@1+ (1,0) [0|1] ""  HVESP01
 SG_ HVESP01_CellBalance_04_4 m0 : 11|1@1+ (1,0) [0|1] ""  HVESP01
 SG_ HVESP01_CellBalance_05_4 m0 : 12|1@1+ (1,0) [0|1] ""  HVESP01
 SG_ HVESP01_CellBalance_06_4 m0 : 13|1@1+ (1,0) [0|1] ""  HVESP01
 SG_ HVESP01_CellBalance_07_4 m0 : 14|1@1+ (1,0) [0|1] ""  HVESP01
 SG_ HVESP01_CellBalance_08_4 m0 : 15|1@1+ (1,0) [0|1] ""  HVESP01
 SG_ HVESP01_CellBalance_09_4 m1 : 8|1@1+ (1,0) [0|1] ""  HVESP01
 SG_ HVESP01_CellBalance_10_4 m1 : 9|1@1+ (1,0) [0|1] ""  HVESP01
 SG_ HVESP01_CellBalance_11_4 m1 : 10|1@1+ (1,0) [0|1] ""  HVESP01
 SG_ HVESP01_CellBalance_12_4 m1 : 11|1@1+ (1,0) [0|1] ""  HVESP01
 SG_ HVESP01_CellBalance_13_4 m1 : 12|1@1+ (1,0) [0|1] ""  HVESP01
 SG_ HVESP01_CellBalance_14_4 m1 : 13|1@1+ (1,0) [0|1] ""  HVESP01
 SG_ HVESP01_CellBalance_15_4 m1 : 14|1@1+ (1,0) [0|1] ""  HVESP01
 SG_ HVESP01_CellBalance_16_4 m1 : 15|1@1+ (1,0) [0|1] ""  HVESP01
 SG_ HVESP01_CellBalance_17_4 m2 : 8|1@1+ (1,0) [0|1] ""  HVESP01
 SG_ HVESP01_CellBalance_18_4 m2 : 9|1@1+ (1,0) [0|1] ""  HVESP01
 SG_ HVESP01_CellBalance_19_4 m2 : 10|1@1+ (1,0) [0|1] ""  HVESP01
 SG_ HVESP01_CellBalance_20_4 m2 : 11|1@1+ (1,0) [0|1] ""  HVESP01
 SG_ HVESP01_CellBalance_21_4 m2 : 12|1@1+ (1,0) [0|1] ""  HVESP01
 SG_ HVESP01_CellBalance_22_4 m2 : 13|1@1+ (1,0) [0|1] ""  HVESP01
 SG_ HVESP01_CellBalance_23_4 m2 : 14|1@1+ (1,0) [0|1] ""  HVESP01
 SG_ HVESP01_CellBalance_24_4 m2 : 15|1@1+ (1,0) [0|1] ""  HVESP01
 SG_ HVESP01_CellBalance_25_4 m3 : 8|1@1+ (1,0) [0|1] ""  HVESP01
 SG_ HVESP01_CellBalance_26_4 m3 : 9|1@1+ (1,0) [0|1] ""  HVESP01
 SG_ HVESP01_CellBalance_27_4 m3 : 10|1@1+ (1,0) [0|1] ""  HVESP01
 SG_ HVESP01_CellBalance_28_4 m3 : 11|1@1+ (1,0) [0|1] ""  HVESP01
 SG_ HVESP01_CellBalance_29_4 m3 : 12|1@1+ (1,0) [0|1] ""  HVESP01
 SG_ HVESP01_CellBalance_30_4 m3 : 13|1@1+ (1,0) [0|1] ""  HVESP01
 SG_ HVESP01_CellBalance_31_4 m3 : 14|1@1+ (1,0) [0|1] ""  HVESP01
 SG_ HVESP01_CellBalance_32_4 m3 : 15|1@1+ (1,0) [0|1] ""  HVESP01
 SG_ HVESP01_CellBalance_33_4 m4 : 8|1@1+ (1,0) [0|1] ""  HVESP01
 SG_ HVESP01_CellBalance_34_4 m4 : 9|1@1+ (1,0) [0|1] ""  HVESP01
 SG_ HVESP01_CellBalance_35_4 m4 : 10|1@1+ (1,0) [0|1] ""  HVESP01
 SG_ HVESP01_CellBalance_36_4 m4 : 11|1@1+ (1,0) [0|1] ""  HVESP01
 SG_ HVESP01_CellBalance_37_4 m4 : 12|1@1+ (1,0) [0|1] ""  HVESP01
 SG_ HVESP01_CellBalance_38_4 m4 : 13|1@1+ (1,0) [0|1] ""  HVESP01
 SG_ HVESP01_CellBalance_39_4 m4 : 14|1@1+ (1,0) [0|1] ""  HVESP01
 SG_ HVESP01_CellBalance_40_4 m4 : 15|1@1+ (1,0) [0|1] ""  HVESP01
 SG_ HVESP01_CellBalance_41_4 m5 : 8|1@1+ (1,0) [0|1] ""  HVESP01
 SG_ HVESP01_CellBalance_42_4 m5 : 9|1@1+ (1,0) [0|1] ""  HVESP01
 SG_ HVESP01_CellBalance_43_4 m5 : 10|1@1+ (1,0) [0|1] ""  HVESP01
 SG_ HVESP01_CellBalance_44_4 m5 : 11|1@1+ (1,0) [0|1] ""  HVESP01
 SG_ HVESP01_CellBalance_45_4 m5 : 12|1@1+ (1,0) [0|1] ""  HVESP01
 SG_ HVESP01_CellBalance_46_4 m5 : 13|1@1+ (1,0) [0|1] ""  HVESP01
 SG_ HVESP01_CellBalance_47_4 m5 : 14|1@1+ (1,0) [0|1] ""  HVESP01
 SG_ HVESP01_CellBalance_48_4 m5 : 15|1@1+ (1,0) [0|1] ""  HVESP01
 SG_ HVESP01_CellBalance_49_4 m6 : 8|1@1+ (1,0) [0|1] ""  HVESP01
 SG_ HVESP01_CellBalance_50_4 m6 : 9|1@1+ (1,0) [0|1] ""  HVESP01
 SG_ HVESP01_CellBalance_51_4 m6 : 10|1@1+ (1,0) [0|1] ""  HVESP01
 SG_ HVESP01_CellBalance_52_4 m6 : 11|1@1+ (1,0) [0|1] ""  HVESP01
 SG_ HVESP01_CellBalance_53_4 m6 : 12|1@1+ (1,0) [0|1] ""  HVESP01
 SG_ HVESP01_CellBalance_54_4 m6 : 13|1@1+ (1,0) [0|1] ""  HVESP01
 SG_ HVESP01_CellBalance_55_4 m6 : 14|1@1+ (1,0) [0|1] ""  HVESP01
 SG_ HVESP01_CellBalance_56_4 m6 : 15|1@1+ (1,0) [0|1] ""  HVESP01
 SG_ HVESP01_CellBalance_57_4 m7 : 8|1@1+ (1,0) [0|1] ""  HVESP01
 SG_ HVESP01_CellBalance_58_4 m7 : 9|1@1+ (1,0) [0|1] ""  HVESP01
 SG_ HVESP01_CellBalance_59_4 m7 : 10|1@1+ (1,0) [0|1] ""  HVESP01
 SG_ HVESP01_CellBalance_60_4 m7 : 11|1@1+ (1,0) [0|1] ""  HVESP01
 SG_ HVESP01_CellBalance_61_4 m7 : 12|1@1+ (1,0) [0|1] ""  HVESP01
 SG_ HVESP01_CellBalance_62_4 m7 : 13|1@1+ (1,0) [0|1] ""  HVESP01
 SG_ HVESP01_CellBalance_63_4 m7 : 14|1@1+ (1,0) [0|1] ""  HVESP01
 SG_ HVESP01_CellBalance_64_4 m7 : 15|1@1+ (1,0) [0|1] ""  HVESP01
 SG_ HVESP01_CellBalance_65_4 m8 : 8|1@1+ (1,0) [0|1] ""  HVESP01
 SG_ HVESP01_CellBalance_66_4 m8 : 9|1@1+ (1,0) [0|1] ""  HVESP01
 SG_ HVESP01_CellBalance_67_4 m8 : 10|1@1+ (1,0) [0|1] ""  HVESP01
 SG_ HVESP01_CellBalance_68_4 m8 : 11|1@1+ (1,0) [0|1] ""  HVESP01
 SG_ HVESP01_CellBalance_69_4 m8 : 12|1@1+ (1,0) [0|1] ""  HVESP01
 SG_ HVESP01_CellBalance_70_4 m8 : 13|1@1+ (1,0) [0|1] ""  HVESP01
 SG_ HVESP01_CellBalance_71_4 m8 : 14|1@1+ (1,0) [0|1] ""  HVESP01
 SG_ HVESP01_CellBalance_72_4 m8 : 15|1@1+ (1,0) [0|1] ""  HVESP01
 SG_ HVESP01_CellBalance_73_4 m9 : 8|1@1+ (1,0) [0|1] ""  HVESP01
 SG_ HVESP01_CellBalance_74_4 m9 : 9|1@1+ (1,0) [0|1] ""  HVESP01
 SG_ HVESP01_CellBalance_75_4 m9 : 10|1@1+ (1,0) [0|1] ""  HVESP01
 SG_ HVESP01_CellBalance_76_4 m9 : 11|1@1+ (1,0) [0|1] ""  HVESP01
 SG_ HVESP01_CellBalance_77_4 m9 : 12|1@1+ (1,0) [0|1] ""  HVESP01
 SG_ HVESP01_CellBalance_78_4 m9 : 13|1@1+ (1,0) [0|1] ""  HVESP01
 SG_ HVESP01_CellBalance_79_4 m9 : 14|1@1+ (1,0) [0|1] ""  HVESP01
 SG_ HVESP01_CellBalance_80_4 m9 : 15|1@1+ (1,0) [0|1] ""  HVESP01
 SG_ HVESP01_CellBalance_81_4 m10 : 8|1@1+ (1,0) [0|1] ""  HVESP01
 SG_ HVESP01_CellBalance_82_4 m10 : 9|1@1+ (1,0) [0|1] ""  HVESP01
 SG_ HVESP01_CellBalance_83_4 m10 : 10|1@1+ (1,0) [0|1] ""  HVESP01
 SG_ HVESP01_CellBalance_84_4 m10 : 11|1@1+ (1,0) [0|1] ""  HVESP01
 SG_ HVESP01_CellBalance_85_4 m10 : 12|1@1+ (1,0) [0|1] ""  HVESP01
 SG_ HVESP01_CellBalance_86_4 m10 : 13|1@1+ (1,0) [0|1] ""  HVESP01
 SG_ HVESP01_CellBalance_87_4 m10 : 14|1@1+ (1,0) [0|1] ""  HVESP01
 SG_ HVESP01_CellBalance_88_4 m10 : 15|1@1+ (1,0) [0|1] ""  HVESP01
 SG_ HVESP01_CellBalance_89_4 m11 : 8|1@1+ (1,0) [0|1] ""  HVESP01
 SG_ HVESP01_CellBalance_90_4 m11 : 9|1@1+ (1,0) [0|1] ""  HVESP01
 SG_ HVESP01_CellBalance_91_4 m11 : 10|1@1+ (1,0) [0|1] ""  HVESP01
 SG_ HVESP01_CellBalance_92_4 m11 : 11|1@1+ (1,0) [0|1] ""  HVESP01
 SG_ HVESP01_CellBalance_93_4 m11 : 12|1@1+ (1,0) [0|1] ""  HVESP01
 SG_ HVESP01_CellBalance_94_4 m11 : 13|1@1+ (1,0) [0|1] ""  HVESP01
 SG_ HVESP01_CellBalance_95_4 m11 : 14|1@1+ (1,0) [0|1] ""  HVESP01
 SG_ HVESP01_CellBalance_96_4 m11 : 15|1@1+ (1,0) [0|1] ""  HVESP01
 SG_ HVESP01_CellBalance_97_4 m12 : 8|1@1+ (1,0) [0|1] ""  HVESP01
 SG_ HVESP01_CellBalance_98_4 m12 : 9|1@1+ (1,0) [0|1] ""  HVESP01
 SG_ HVESP01_CellBalance_99_4 m12 : 10|1@1+ (1,0) [0|1] ""  HVESP01
 SG_ HVESP01_CellBalance_100_4 m12 : 11|1@1+ (1,0) [0|1] ""  HVESP01
 SG_ HVESP01_CellBalance_101_4 m12 : 12|1@1+ (1,0) [0|1] ""  HVESP01
 SG_ HVESP01_CellBalance_102_4 m12 : 13|1@1+ (1,0) [0|1] ""  HVESP01
 SG_ HVESP01_CellBalance_103_4 m12 : 14|1@1+ (1,0) [0|1] ""  HVESP01
 SG_ HVESP01_CellBalance_104_4 m12 : 15|1@1+ (1,0) [0|1] ""  HVESP01
 SG_ HVESP01_CellBalance_105_4 m13 : 8|1@1+ (1,0) [0|1] ""  HVESP01
 SG_ HVESP01_CellBalance_106_4 m13 : 9|1@1+ (1,0) [0|1] ""  HVESP01
 SG_ HVESP01_CellBalance_107_4 m13 : 10|1@1+ (1,0) [0|1] ""  HVESP01
 SG_ HVESP01_CellBalance_108_4 m13 : 11|1@1+ (1,0) [0|1] ""  HVESP01
 SG_ HVESP01_CellBalance_109_4 m13 : 12|1@1+ (1,0) [0|1] ""  HVESP01
 SG_ HVESP01_CellBalance_110_4 m13 : 13|1@1+ (1,0) [0|1] ""  HVESP01
 SG_ HVESP01_CellBalance_111_4 m13 : 14|1@1+ (1,0) [0|1] ""  HVESP01
 SG_ HVESP01_CellBalance_112_4 m13 : 15|1@1+ (1,0) [0|1] ""  HVESP01
 SG_ HVESP01_CellBalance_113_4 m14 : 8|1@1+ (1,0) [0|1] ""  HVESP01
 SG_ HVESP01_CellBalance_114_4 m14 : 9|1@1+ (1,0) [0|1] ""  HVESP01
 SG_ HVESP01_CellBalance_115_4 m14 : 10|1@1+ (1,0) [0|1] ""  HVESP01
 SG_ HVESP01_CellBalance_116_4 m14 : 11|1@1+ (1,0) [0|1] ""  HVESP01
 SG_ HVESP01_CellBalance_117_4 m14 : 12|1@1+ (1,0) [0|1] ""  HVESP01
 SG_ HVESP01_CellBalance_118_4 m14 : 13|1@1+ (1,0) [0|1] ""  HVESP01
 SG_ HVESP01_CellBalance_119_4 m14 : 14|1@1+ (1,0) [0|1] ""  HVESP01
 SG_ HVESP01_CellBalance_120_4 m14 : 15|1@1+ (1,0) [0|1] ""  HVESP01
 SG_ HVESP01_CellBalance_121_4 m15 : 8|1@1+ (1,0) [0|1] ""  HVESP01
 SG_ HVESP01_CellBalance_122_4 m15 : 9|1@1+ (1,0) [0|1] ""  HVESP01
 SG_ HVESP01_CellBalance_123_4 m15 : 10|1@1+ (1,0) [0|1] ""  HVESP01
 SG_ HVESP01_CellBalance_124_4 m15 : 11|1@1+ (1,0) [0|1] ""  HVESP01
 SG_ HVESP01_CellBalance_125_4 m15 : 12|1@1+ (1,0) [0|1] ""  HVESP01
 SG_ HVESP01_CellBalance_126_4 m15 : 13|1@1+ (1,0) [0|1] ""  HVESP01
 SG_ HVESP01_CellBalance_127_4 m15 : 14|1@1+ (1,0) [0|1] ""  HVESP01
 SG_ HVESP01_CellBalance_128_4 m15 : 15|1@1+ (1,0) [0|1] ""  HVESP01
 SG_ HVESP01_CellBalance_129_4 m16 : 8|1@1+ (1,0) [0|1] ""  HVESP01
 SG_ HVESP01_CellBalance_130_4 m16 : 9|1@1+ (1,0) [0|1] ""  HVESP01
 SG_ HVESP01_CellBalance_131_4 m16 : 10|1@1+ (1,0) [0|1] ""  HVESP01
 SG_ HVESP01_CellBalance_132_4 m16 : 11|1@1+ (1,0) [0|1] ""  HVESP01
 SG_ HVESP01_CellBalance_133_4 m16 : 12|1@1+ (1,0) [0|1] ""  HVESP01
 SG_ HVESP01_CellBalance_134_4 m16 : 13|1@1+ (1,0) [0|1] ""  HVESP01
 SG_ HVESP01_CellBalance_135_4 m16 : 14|1@1+ (1,0) [0|1] ""  HVESP01
 SG_ HVESP01_CellBalance_136_4 m16 : 15|1@1+ (1,0) [0|1] ""  HVESP01
 SG_ HVESP01_CellBalance_137_4 m17 : 8|1@1+ (1,0) [0|1] ""  HVESP01
 SG_ HVESP01_CellBalance_138_4 m17 : 9|1@1+ (1,0) [0|1] ""  HVESP01
 SG_ HVESP01_CellBalance_139_4 m17 : 10|1@1+ (1,0) [0|1] ""  HVESP01
 SG_ HVESP01_CellBalance_140_4 m17 : 11|1@1+ (1,0) [0|1] ""  HVESP01
 SG_ HVESP01_CellBalance_141_4 m17 : 12|1@1+ (1,0) [0|1] ""  HVESP01
 SG_ HVESP01_CellBalance_142_4 m17 : 13|1@1+ (1,0) [0|1] ""  HVESP01
 SG_ HVESP01_CellBalance_143_4 m17 : 14|1@1+ (1,0) [0|1] ""  HVESP01
 SG_ HVESP01_CellBalance_144_4 m17 : 15|1@1+ (1,0) [0|1] ""  HVESP01
 SG_ HVESP01_CellBalance_145_4 m18 : 8|1@1+ (1,0) [0|1] ""  HVESP01
 SG_ HVESP01_CellBalance_146_4 m18 : 9|1@1+ (1,0) [0|1] ""  HVESP01
 SG_ HVESP01_CellBalance_147_4 m18 : 10|1@1+ (1,0) [0|1] ""  HVESP01
 SG_ HVESP01_CellBalance_148_4 m18 : 11|1@1+ (1,0) [0|1] ""  HVESP01
 SG_ HVESP01_CellBalance_149_4 m18 : 12|1@1+ (1,0) [0|1] ""  HVESP01
 SG_ HVESP01_CellBalance_150_4 m18 : 13|1@1+ (1,0) [0|1] ""  HVESP01
 SG_ HVESP01_CellBalance_151_4 m18 : 14|1@1+ (1,0) [0|1] ""  HVESP01
 SG_ HVESP01_CellBalance_152_4 m18 : 15|1@1+ (1,0) [0|1] ""  HVESP01
 SG_ HVESP01_CellBalance_153_4 m19 : 8|1@1+ (1,0) [0|1] ""  HVESP01
 SG_ HVESP01_CellBalance_154_4 m19 : 9|1@1+ (1,0) [0|1] ""  HVESP01
 SG_ HVESP01_CellBalance_155_4 m19 : 10|1@1+ (1,0) [0|1] ""  HVESP01
 SG_ HVESP01_CellBalance_156_4 m19 : 11|1@1+ (1,0) [0|1] ""  HVESP01
 SG_ HVESP01_CellBalance_157_4 m19 : 12|1@1+ (1,0) [0|1] ""  HVESP01
 SG_ HVESP01_CellBalance_158_4 m19 : 13|1@1+ (1,0) [0|1] ""  HVESP01
 SG_ HVESP01_CellBalance_159_4 m19 : 14|1@1+ (1,0) [0|1] ""  HVESP01
 SG_ HVESP01_CellBalance_160_4 m19 : 15|1@1+ (1,0) [0|1] ""  HVESP01
 SG_ HVESP01_CellBalance_161_4 m20 : 8|1@1+ (1,0) [0|1] ""  HVESP01
 SG_ HVESP01_CellBalance_162_4 m20 : 9|1@1+ (1,0) [0|1] ""  HVESP01
 SG_ HVESP01_CellBalance_163_4 m20 : 10|1@1+ (1,0) [0|1] ""  HVESP01
 SG_ HVESP01_CellBalance_164_4 m20 : 11|1@1+ (1,0) [0|1] ""  HVESP01
 SG_ HVESP01_CellBalance_165_4 m20 : 12|1@1+ (1,0) [0|1] ""  HVESP01
 SG_ HVESP01_CellBalance_166_4 m20 : 13|1@1+ (1,0) [0|1] ""  HVESP01
 SG_ HVESP01_CellBalance_167_4 m20 : 14|1@1+ (1,0) [0|1] ""  HVESP01
 SG_ HVESP01_CellBalance_168_4 m20 : 15|1@1+ (1,0) [0|1] ""  HVESP01
 SG_ HVESP01_CellBalance_169_4 m21 : 8|1@1+ (1,0) [0|1] ""  HVESP01
 SG_ HVESP01_CellBalance_170_4 m21 : 9|1@1+ (1,0) [0|1] ""  HVESP01
 SG_ HVESP01_CellBalance_171_4 m21 : 10|1@1+ (1,0) [0|1] ""  HVESP01
 SG_ HVESP01_CellBalance_172_4 m21 : 11|1@1+ (1,0) [0|1] ""  HVESP01
 SG_ HVESP01_CellBalance_173_4 m21 : 12|1@1+ (1,0) [0|1] ""  HVESP01
 SG_ HVESP01_CellBalance_174_4 m21 : 13|1@1+ (1,0) [0|1] ""  HVESP01
 SG_ HVESP01_CellBalance_175_4 m21 : 14|1@1+ (1,0) [0|1] ""  HVESP01
 SG_ HVESP01_CellBalance_176_4 m21 : 15|1@1+ (1,0) [0|1] ""  HVESP01
 SG_ HVESP01_CellBalance_177_4 m22 : 8|1@1+ (1,0) [0|1] ""  HVESP01
 SG_ HVESP01_CellBalance_178_4 m22 : 9|1@1+ (1,0) [0|1] ""  HVESP01
 SG_ HVESP01_CellBalance_179_4 m22 : 10|1@1+ (1,0) [0|1] ""  HVESP01
 SG_ HVESP01_CellBalance_180_4 m22 : 11|1@1+ (1,0) [0|1] ""  HVESP01
 SG_ HVESP01_CellBalance_181_4 m22 : 12|1@1+ (1,0) [0|1] ""  HVESP01
 SG_ HVESP01_CellBalance_182_4 m22 : 13|1@1+ (1,0) [0|1] ""  HVESP01
 SG_ HVESP01_CellBalance_183_4 m22 : 14|1@1+ (1,0) [0|1] ""  HVESP01
 SG_ HVESP01_CellBalance_184_4 m22 : 15|1@1+ (1,0) [0|1] ""  HVESP01
 SG_ multiplexorcb_4 M : 0|8@1+ (1,0) [0|255] ""  HVESP01

BO_ 2499743337 HVESP01_CellBalance_5: 8 HVESP01
 SG_ HVESP01_CellBalance_01_5 m0 : 8|1@1+ (1,0) [0|1] ""  HVESP01
 SG_ HVESP01_CellBalance_02_5 m0 : 9|1@1+ (1,0) [0|1] ""  HVESP01
 SG_ HVESP01_CellBalance_03_5 m0 : 10|1@1+ (1,0) [0|1] ""  HVESP01
 SG_ HVESP01_CellBalance_04_5 m0 : 11|1@1+ (1,0) [0|1] ""  HVESP01
 SG_ HVESP01_CellBalance_05_5 m0 : 12|1@1+ (1,0) [0|1] ""  HVESP01
 SG_ HVESP01_CellBalance_06_5 m0 : 13|1@1+ (1,0) [0|1] ""  HVESP01
 SG_ HVESP01_CellBalance_07_5 m0 : 14|1@1+ (1,0) [0|1] ""  HVESP01
 SG_ HVESP01_CellBalance_08_5 m0 : 15|1@1+ (1,0) [0|1] ""  HVESP01
 SG_ HVESP01_CellBalance_09_5 m1 : 8|1@1+ (1,0) [0|1] ""  HVESP01
 SG_ HVESP01_CellBalance_10_5 m1 : 9|1@1+ (1,0) [0|1] ""  HVESP01
 SG_ HVESP01_CellBalance_11_5 m1 : 10|1@1+ (1,0) [0|1] ""  HVESP01
 SG_ HVESP01_CellBalance_12_5 m1 : 11|1@1+ (1,0) [0|1] ""  HVESP01
 SG_ HVESP01_CellBalance_13_5 m1 : 12|1@1+ (1,0) [0|1] ""  HVESP01
 SG_ HVESP01_CellBalance_14_5 m1 : 13|1@1+ (1,0) [0|1] ""  HVESP01
 SG_ HVESP01_CellBalance_15_5 m1 : 14|1@1+ (1,0) [0|1] ""  HVESP01
 SG_ HVESP01_CellBalance_16_5 m1 : 15|1@1+ (1,0) [0|1] ""  HVESP01
 SG_ HVESP01_CellBalance_17_5 m2 : 8|1@1+ (1,0) [0|1] ""  HVESP01
 SG_ HVESP01_CellBalance_18_5 m2 : 9|1@1+ (1,0) [0|1] ""  HVESP01
 SG_ HVESP01_CellBalance_19_5 m2 : 10|1@1+ (1,0) [0|1] ""  HVESP01
 SG_ HVESP01_CellBalance_20_5 m2 : 11|1@1+ (1,0) [0|1] ""  HVESP01
 SG_ HVESP01_CellBalance_21_5 m2 : 12|1@1+ (1,0) [0|1] ""  HVESP01
 SG_ HVESP01_CellBalance_22_5 m2 : 13|1@1+ (1,0) [0|1] ""  HVESP01
 SG_ HVESP01_CellBalance_23_5 m2 : 14|1@1+ (1,0) [0|1] ""  HVESP01
 SG_ HVESP01_CellBalance_24_5 m2 : 15|1@1+ (1,0) [0|1] ""  HVESP01
 SG_ HVESP01_CellBalance_25_5 m3 : 8|1@1+ (1,0) [0|1] ""  HVESP01
 SG_ HVESP01_CellBalance_26_5 m3 : 9|1@1+ (1,0) [0|1] ""  HVESP01
 SG_ HVESP01_CellBalance_27_5 m3 : 10|1@1+ (1,0) [0|1] ""  HVESP01
 SG_ HVESP01_CellBalance_28_5 m3 : 11|1@1+ (1,0) [0|1] ""  HVESP01
 SG_ HVESP01_CellBalance_29_5 m3 : 12|1@1+ (1,0) [0|1] ""  HVESP01
 SG_ HVESP01_CellBalance_30_5 m3 : 13|1@1+ (1,0) [0|1] ""  HVESP01
 SG_ HVESP01_CellBalance_31_5 m3 : 14|1@1+ (1,0) [0|1] ""  HVESP01
 SG_ HVESP01_CellBalance_32_5 m3 : 15|1@1+ (1,0) [0|1] ""  HVESP01
 SG_ HVESP01_CellBalance_33_5 m4 : 8|1@1+ (1,0) [0|1] ""  HVESP01
 SG_ HVESP01_CellBalance_34_5 m4 : 9|1@1+ (1,0) [0|1] ""  HVESP01
 SG_ HVESP01_CellBalance_35_5 m4 : 10|1@1+ (1,0) [0|1] ""  HVESP01
 SG_ HVESP01_CellBalance_36_5 m4 : 11|1@1+ (1,0) [0|1] ""  HVESP01
 SG_ HVESP01_CellBalance_37_5 m4 : 12|1@1+ (1,0) [0|1] ""  HVESP01
 SG_ HVESP01_CellBalance_38_5 m4 : 13|1@1+ (1,0) [0|1] ""  HVESP01
 SG_ HVESP01_CellBalance_39_5 m4 : 14|1@1+ (1,0) [0|1] ""  HVESP01
 SG_ HVESP01_CellBalance_40_5 m4 : 15|1@1+ (1,0) [0|1] ""  HVESP01
 SG_ HVESP01_CellBalance_41_5 m5 : 8|1@1+ (1,0) [0|1] ""  HVESP01
 SG_ HVESP01_CellBalance_42_5 m5 : 9|1@1+ (1,0) [0|1] ""  HVESP01
 SG_ HVESP01_CellBalance_43_5 m5 : 10|1@1+ (1,0) [0|1] ""  HVESP01
 SG_ HVESP01_CellBalance_44_5 m5 : 11|1@1+ (1,0) [0|1] ""  HVESP01
 SG_ HVESP01_CellBalance_45_5 m5 : 12|1@1+ (1,0) [0|1] ""  HVESP01
 SG_ HVESP01_CellBalance_46_5 m5 : 13|1@1+ (1,0) [0|1] ""  HVESP01
 SG_ HVESP01_CellBalance_47_5 m5 : 14|1@1+ (1,0) [0|1] ""  HVESP01
 SG_ HVESP01_CellBalance_48_5 m5 : 15|1@1+ (1,0) [0|1] ""  HVESP01
 SG_ HVESP01_CellBalance_49_5 m6 : 8|1@1+ (1,0) [0|1] ""  HVESP01
 SG_ HVESP01_CellBalance_50_5 m6 : 9|1@1+ (1,0) [0|1] ""  HVESP01
 SG_ HVESP01_CellBalance_51_5 m6 : 10|1@1+ (1,0) [0|1] ""  HVESP01
 SG_ HVESP01_CellBalance_52_5 m6 : 11|1@1+ (1,0) [0|1] ""  HVESP01
 SG_ HVESP01_CellBalance_53_5 m6 : 12|1@1+ (1,0) [0|1] ""  HVESP01
 SG_ HVESP01_CellBalance_54_5 m6 : 13|1@1+ (1,0) [0|1] ""  HVESP01
 SG_ HVESP01_CellBalance_55_5 m6 : 14|1@1+ (1,0) [0|1] ""  HVESP01
 SG_ HVESP01_CellBalance_56_5 m6 : 15|1@1+ (1,0) [0|1] ""  HVESP01
 SG_ HVESP01_CellBalance_57_5 m7 : 8|1@1+ (1,0) [0|1] ""  HVESP01
 SG_ HVESP01_CellBalance_58_5 m7 : 9|1@1+ (1,0) [0|1] ""  HVESP01
 SG_ HVESP01_CellBalance_59_5 m7 : 10|1@1+ (1,0) [0|1] ""  HVESP01
 SG_ HVESP01_CellBalance_60_5 m7 : 11|1@1+ (1,0) [0|1] ""  HVESP01
 SG_ HVESP01_CellBalance_61_5 m7 : 12|1@1+ (1,0) [0|1] ""  HVESP01
 SG_ HVESP01_CellBalance_62_5 m7 : 13|1@1+ (1,0) [0|1] ""  HVESP01
 SG_ HVESP01_CellBalance_63_5 m7 : 14|1@1+ (1,0) [0|1] ""  HVESP01
 SG_ HVESP01_CellBalance_64_5 m7 : 15|1@1+ (1,0) [0|1] ""  HVESP01
 SG_ HVESP01_CellBalance_65_5 m8 : 8|1@1+ (1,0) [0|1] ""  HVESP01
 SG_ HVESP01_CellBalance_66_5 m8 : 9|1@1+ (1,0) [0|1] ""  HVESP01
 SG_ HVESP01_CellBalance_67_5 m8 : 10|1@1+ (1,0) [0|1] ""  HVESP01
 SG_ HVESP01_CellBalance_68_5 m8 : 11|1@1+ (1,0) [0|1] ""  HVESP01
 SG_ HVESP01_CellBalance_69_5 m8 : 12|1@1+ (1,0) [0|1] ""  HVESP01
 SG_ HVESP01_CellBalance_70_5 m8 : 13|1@1+ (1,0) [0|1] ""  HVESP01
 SG_ HVESP01_CellBalance_71_5 m8 : 14|1@1+ (1,0) [0|1] ""  HVESP01
 SG_ HVESP01_CellBalance_72_5 m8 : 15|1@1+ (1,0) [0|1] ""  HVESP01
 SG_ HVESP01_CellBalance_73_5 m9 : 8|1@1+ (1,0) [0|1] ""  HVESP01
 SG_ HVESP01_CellBalance_74_5 m9 : 9|1@1+ (1,0) [0|1] ""  HVESP01
 SG_ HVESP01_CellBalance_75_5 m9 : 10|1@1+ (1,0) [0|1] ""  HVESP01
 SG_ HVESP01_CellBalance_76_5 m9 : 11|1@1+ (1,0) [0|1] ""  HVESP01
 SG_ HVESP01_CellBalance_77_5 m9 : 12|1@1+ (1,0) [0|1] ""  HVESP01
 SG_ HVESP01_CellBalance_78_5 m9 : 13|1@1+ (1,0) [0|1] ""  HVESP01
 SG_ HVESP01_CellBalance_79_5 m9 : 14|1@1+ (1,0) [0|1] ""  HVESP01
 SG_ HVESP01_CellBalance_80_5 m9 : 15|1@1+ (1,0) [0|1] ""  HVESP01
 SG_ HVESP01_CellBalance_81_5 m10 : 8|1@1+ (1,0) [0|1] ""  HVESP01
 SG_ HVESP01_CellBalance_82_5 m10 : 9|1@1+ (1,0) [0|1] ""  HVESP01
 SG_ HVESP01_CellBalance_83_5 m10 : 10|1@1+ (1,0) [0|1] ""  HVESP01
 SG_ HVESP01_CellBalance_84_5 m10 : 11|1@1+ (1,0) [0|1] ""  HVESP01
 SG_ HVESP01_CellBalance_85_5 m10 : 12|1@1+ (1,0) [0|1] ""  HVESP01
 SG_ HVESP01_CellBalance_86_5 m10 : 13|1@1+ (1,0) [0|1] ""  HVESP01
 SG_ HVESP01_CellBalance_87_5 m10 : 14|1@1+ (1,0) [0|1] ""  HVESP01
 SG_ HVESP01_CellBalance_88_5 m10 : 15|1@1+ (1,0) [0|1] ""  HVESP01
 SG_ HVESP01_CellBalance_89_5 m11 : 8|1@1+ (1,0) [0|1] ""  HVESP01
 SG_ HVESP01_CellBalance_90_5 m11 : 9|1@1+ (1,0) [0|1] ""  HVESP01
 SG_ HVESP01_CellBalance_91_5 m11 : 10|1@1+ (1,0) [0|1] ""  HVESP01
 SG_ HVESP01_CellBalance_92_5 m11 : 11|1@1+ (1,0) [0|1] ""  HVESP01
 SG_ HVESP01_CellBalance_93_5 m11 : 12|1@1+ (1,0) [0|1] ""  HVESP01
 SG_ HVESP01_CellBalance_94_5 m11 : 13|1@1+ (1,0) [0|1] ""  HVESP01
 SG_ HVESP01_CellBalance_95_5 m11 : 14|1@1+ (1,0) [0|1] ""  HVESP01
 SG_ HVESP01_CellBalance_96_5 m11 : 15|1@1+ (1,0) [0|1] ""  HVESP01
 SG_ HVESP01_CellBalance_97_5 m12 : 8|1@1+ (1,0) [0|1] ""  HVESP01
 SG_ HVESP01_CellBalance_98_5 m12 : 9|1@1+ (1,0) [0|1] ""  HVESP01
 SG_ HVESP01_CellBalance_99_5 m12 : 10|1@1+ (1,0) [0|1] ""  HVESP01
 SG_ HVESP01_CellBalance_100_5 m12 : 11|1@1+ (1,0) [0|1] ""  HVESP01
 SG_ HVESP01_CellBalance_101_5 m12 : 12|1@1+ (1,0) [0|1] ""  HVESP01
 SG_ HVESP01_CellBalance_102_5 m12 : 13|1@1+ (1,0) [0|1] ""  HVESP01
 SG_ HVESP01_CellBalance_103_5 m12 : 14|1@1+ (1,0) [0|1] ""  HVESP01
 SG_ HVESP01_CellBalance_104_5 m12 : 15|1@1+ (1,0) [0|1] ""  HVESP01
 SG_ HVESP01_CellBalance_105_5 m13 : 8|1@1+ (1,0) [0|1] ""  HVESP01
 SG_ HVESP01_CellBalance_106_5 m13 : 9|1@1+ (1,0) [0|1] ""  HVESP01
 SG_ HVESP01_CellBalance_107_5 m13 : 10|1@1+ (1,0) [0|1] ""  HVESP01
 SG_ HVESP01_CellBalance_108_5 m13 : 11|1@1+ (1,0) [0|1] ""  HVESP01
 SG_ HVESP01_CellBalance_109_5 m13 : 12|1@1+ (1,0) [0|1] ""  HVESP01
 SG_ HVESP01_CellBalance_110_5 m13 : 13|1@1+ (1,0) [0|1] ""  HVESP01
 SG_ HVESP01_CellBalance_111_5 m13 : 14|1@1+ (1,0) [0|1] ""  HVESP01
 SG_ HVESP01_CellBalance_112_5 m13 : 15|1@1+ (1,0) [0|1] ""  HVESP01
 SG_ HVESP01_CellBalance_113_5 m14 : 8|1@1+ (1,0) [0|1] ""  HVESP01
 SG_ HVESP01_CellBalance_114_5 m14 : 9|1@1+ (1,0) [0|1] ""  HVESP01
 SG_ HVESP01_CellBalance_115_5 m14 : 10|1@1+ (1,0) [0|1] ""  HVESP01
 SG_ HVESP01_CellBalance_116_5 m14 : 11|1@1+ (1,0) [0|1] ""  HVESP01
 SG_ HVESP01_CellBalance_117_5 m14 : 12|1@1+ (1,0) [0|1] ""  HVESP01
 SG_ HVESP01_CellBalance_118_5 m14 : 13|1@1+ (1,0) [0|1] ""  HVESP01
 SG_ HVESP01_CellBalance_119_5 m14 : 14|1@1+ (1,0) [0|1] ""  HVESP01
 SG_ HVESP01_CellBalance_120_5 m14 : 15|1@1+ (1,0) [0|1] ""  HVESP01
 SG_ HVESP01_CellBalance_121_5 m15 : 8|1@1+ (1,0) [0|1] ""  HVESP01
 SG_ HVESP01_CellBalance_122_5 m15 : 9|1@1+ (1,0) [0|1] ""  HVESP01
 SG_ HVESP01_CellBalance_123_5 m15 : 10|1@1+ (1,0) [0|1] ""  HVESP01
 SG_ HVESP01_CellBalance_124_5 m15 : 11|1@1+ (1,0) [0|1] ""  HVESP01
 SG_ HVESP01_CellBalance_125_5 m15 : 12|1@1+ (1,0) [0|1] ""  HVESP01
 SG_ HVESP01_CellBalance_126_5 m15 : 13|1@1+ (1,0) [0|1] ""  HVESP01
 SG_ HVESP01_CellBalance_127_5 m15 : 14|1@1+ (1,0) [0|1] ""  HVESP01
 SG_ HVESP01_CellBalance_128_5 m15 : 15|1@1+ (1,0) [0|1] ""  HVESP01
 SG_ HVESP01_CellBalance_129_5 m16 : 8|1@1+ (1,0) [0|1] ""  HVESP01
 SG_ HVESP01_CellBalance_130_5 m16 : 9|1@1+ (1,0) [0|1] ""  HVESP01
 SG_ HVESP01_CellBalance_131_5 m16 : 10|1@1+ (1,0) [0|1] ""  HVESP01
 SG_ HVESP01_CellBalance_132_5 m16 : 11|1@1+ (1,0) [0|1] ""  HVESP01
 SG_ HVESP01_CellBalance_133_5 m16 : 12|1@1+ (1,0) [0|1] ""  HVESP01
 SG_ HVESP01_CellBalance_134_5 m16 : 13|1@1+ (1,0) [0|1] ""  HVESP01
 SG_ HVESP01_CellBalance_135_5 m16 : 14|1@1+ (1,0) [0|1] ""  HVESP01
 SG_ HVESP01_CellBalance_136_5 m16 : 15|1@1+ (1,0) [0|1] ""  HVESP01
 SG_ HVESP01_CellBalance_137_5 m17 : 8|1@1+ (1,0) [0|1] ""  HVESP01
 SG_ HVESP01_CellBalance_138_5 m17 : 9|1@1+ (1,0) [0|1] ""  HVESP01
 SG_ HVESP01_CellBalance_139_5 m17 : 10|1@1+ (1,0) [0|1] ""  HVESP01
 SG_ HVESP01_CellBalance_140_5 m17 : 11|1@1+ (1,0) [0|1] ""  HVESP01
 SG_ HVESP01_CellBalance_141_5 m17 : 12|1@1+ (1,0) [0|1] ""  HVESP01
 SG_ HVESP01_CellBalance_142_5 m17 : 13|1@1+ (1,0) [0|1] ""  HVESP01
 SG_ HVESP01_CellBalance_143_5 m17 : 14|1@1+ (1,0) [0|1] ""  HVESP01
 SG_ HVESP01_CellBalance_144_5 m17 : 15|1@1+ (1,0) [0|1] ""  HVESP01
 SG_ HVESP01_CellBalance_145_5 m18 : 8|1@1+ (1,0) [0|1] ""  HVESP01
 SG_ HVESP01_CellBalance_146_5 m18 : 9|1@1+ (1,0) [0|1] ""  HVESP01
 SG_ HVESP01_CellBalance_147_5 m18 : 10|1@1+ (1,0) [0|1] ""  HVESP01
 SG_ HVESP01_CellBalance_148_5 m18 : 11|1@1+ (1,0) [0|1] ""  HVESP01
 SG_ HVESP01_CellBalance_149_5 m18 : 12|1@1+ (1,0) [0|1] ""  HVESP01
 SG_ HVESP01_CellBalance_150_5 m18 : 13|1@1+ (1,0) [0|1] ""  HVESP01
 SG_ HVESP01_CellBalance_151_5 m18 : 14|1@1+ (1,0) [0|1] ""  HVESP01
 SG_ HVESP01_CellBalance_152_5 m18 : 15|1@1+ (1,0) [0|1] ""  HVESP01
 SG_ HVESP01_CellBalance_153_5 m19 : 8|1@1+ (1,0) [0|1] ""  HVESP01
 SG_ HVESP01_CellBalance_154_5 m19 : 9|1@1+ (1,0) [0|1] ""  HVESP01
 SG_ HVESP01_CellBalance_155_5 m19 : 10|1@1+ (1,0) [0|1] ""  HVESP01
 SG_ HVESP01_CellBalance_156_5 m19 : 11|1@1+ (1,0) [0|1] ""  HVESP01
 SG_ HVESP01_CellBalance_157_5 m19 : 12|1@1+ (1,0) [0|1] ""  HVESP01
 SG_ HVESP01_CellBalance_158_5 m19 : 13|1@1+ (1,0) [0|1] ""  HVESP01
 SG_ HVESP01_CellBalance_159_5 m19 : 14|1@1+ (1,0) [0|1] ""  HVESP01
 SG_ HVESP01_CellBalance_160_5 m19 : 15|1@1+ (1,0) [0|1] ""  HVESP01
 SG_ HVESP01_CellBalance_161_5 m20 : 8|1@1+ (1,0) [0|1] ""  HVESP01
 SG_ HVESP01_CellBalance_162_5 m20 : 9|1@1+ (1,0) [0|1] ""  HVESP01
 SG_ HVESP01_CellBalance_163_5 m20 : 10|1@1+ (1,0) [0|1] ""  HVESP01
 SG_ HVESP01_CellBalance_164_5 m20 : 11|1@1+ (1,0) [0|1] ""  HVESP01
 SG_ HVESP01_CellBalance_165_5 m20 : 12|1@1+ (1,0) [0|1] ""  HVESP01
 SG_ HVESP01_CellBalance_166_5 m20 : 13|1@1+ (1,0) [0|1] ""  HVESP01
 SG_ HVESP01_CellBalance_167_5 m20 : 14|1@1+ (1,0) [0|1] ""  HVESP01
 SG_ HVESP01_CellBalance_168_5 m20 : 15|1@1+ (1,0) [0|1] ""  HVESP01
 SG_ HVESP01_CellBalance_169_5 m21 : 8|1@1+ (1,0) [0|1] ""  HVESP01
 SG_ HVESP01_CellBalance_170_5 m21 : 9|1@1+ (1,0) [0|1] ""  HVESP01
 SG_ HVESP01_CellBalance_171_5 m21 : 10|1@1+ (1,0) [0|1] ""  HVESP01
 SG_ HVESP01_CellBalance_172_5 m21 : 11|1@1+ (1,0) [0|1] ""  HVESP01
 SG_ HVESP01_CellBalance_173_5 m21 : 12|1@1+ (1,0) [0|1] ""  HVESP01
 SG_ HVESP01_CellBalance_174_5 m21 : 13|1@1+ (1,0) [0|1] ""  HVESP01
 SG_ HVESP01_CellBalance_175_5 m21 : 14|1@1+ (1,0) [0|1] ""  HVESP01
 SG_ HVESP01_CellBalance_176_5 m21 : 15|1@1+ (1,0) [0|1] ""  HVESP01
 SG_ HVESP01_CellBalance_177_5 m22 : 8|1@1+ (1,0) [0|1] ""  HVESP01
 SG_ HVESP01_CellBalance_178_5 m22 : 9|1@1+ (1,0) [0|1] ""  HVESP01
 SG_ HVESP01_CellBalance_179_5 m22 : 10|1@1+ (1,0) [0|1] ""  HVESP01
 SG_ HVESP01_CellBalance_180_5 m22 : 11|1@1+ (1,0) [0|1] ""  HVESP01
 SG_ HVESP01_CellBalance_181_5 m22 : 12|1@1+ (1,0) [0|1] ""  HVESP01
 SG_ HVESP01_CellBalance_182_5 m22 : 13|1@1+ (1,0) [0|1] ""  HVESP01
 SG_ HVESP01_CellBalance_183_5 m22 : 14|1@1+ (1,0) [0|1] ""  HVESP01
 SG_ HVESP01_CellBalance_184_5 m22 : 15|1@1+ (1,0) [0|1] ""  HVESP01
 SG_ multiplexorcb_5 M : 0|8@1+ (1,0) [0|255] ""  HVESP01

BO_ 2499743338 HVESP01_CellBalance_6: 8 HVESP01
 SG_ HVESP01_CellBalance_01_6 m0 : 8|1@1+ (1,0) [0|1] ""  HVESP01
 SG_ HVESP01_CellBalance_02_6 m0 : 9|1@1+ (1,0) [0|1] ""  HVESP01
 SG_ HVESP01_CellBalance_03_6 m0 : 10|1@1+ (1,0) [0|1] ""  HVESP01
 SG_ HVESP01_CellBalance_04_6 m0 : 11|1@1+ (1,0) [0|1] ""  HVESP01
 SG_ HVESP01_CellBalance_05_6 m0 : 12|1@1+ (1,0) [0|1] ""  HVESP01
 SG_ HVESP01_CellBalance_06_6 m0 : 13|1@1+ (1,0) [0|1] ""  HVESP01
 SG_ HVESP01_CellBalance_07_6 m0 : 14|1@1+ (1,0) [0|1] ""  HVESP01
 SG_ HVESP01_CellBalance_08_6 m0 : 15|1@1+ (1,0) [0|1] ""  HVESP01
 SG_ HVESP01_CellBalance_09_6 m1 : 8|1@1+ (1,0) [0|1] ""  HVESP01
 SG_ HVESP01_CellBalance_10_6 m1 : 9|1@1+ (1,0) [0|1] ""  HVESP01
 SG_ HVESP01_CellBalance_11_6 m1 : 10|1@1+ (1,0) [0|1] ""  HVESP01
 SG_ HVESP01_CellBalance_12_6 m1 : 11|1@1+ (1,0) [0|1] ""  HVESP01
 SG_ HVESP01_CellBalance_13_6 m1 : 12|1@1+ (1,0) [0|1] ""  HVESP01
 SG_ HVESP01_CellBalance_14_6 m1 : 13|1@1+ (1,0) [0|1] ""  HVESP01
 SG_ HVESP01_CellBalance_15_6 m1 : 14|1@1+ (1,0) [0|1] ""  HVESP01
 SG_ HVESP01_CellBalance_16_6 m1 : 15|1@1+ (1,0) [0|1] ""  HVESP01
 SG_ HVESP01_CellBalance_17_6 m2 : 8|1@1+ (1,0) [0|1] ""  HVESP01
 SG_ HVESP01_CellBalance_18_6 m2 : 9|1@1+ (1,0) [0|1] ""  HVESP01
 SG_ HVESP01_CellBalance_19_6 m2 : 10|1@1+ (1,0) [0|1] ""  HVESP01
 SG_ HVESP01_CellBalance_20_6 m2 : 11|1@1+ (1,0) [0|1] ""  HVESP01
 SG_ HVESP01_CellBalance_21_6 m2 : 12|1@1+ (1,0) [0|1] ""  HVESP01
 SG_ HVESP01_CellBalance_22_6 m2 : 13|1@1+ (1,0) [0|1] ""  HVESP01
 SG_ HVESP01_CellBalance_23_6 m2 : 14|1@1+ (1,0) [0|1] ""  HVESP01
 SG_ HVESP01_CellBalance_24_6 m2 : 15|1@1+ (1,0) [0|1] ""  HVESP01
 SG_ HVESP01_CellBalance_25_6 m3 : 8|1@1+ (1,0) [0|1] ""  HVESP01
 SG_ HVESP01_CellBalance_26_6 m3 : 9|1@1+ (1,0) [0|1] ""  HVESP01
 SG_ HVESP01_CellBalance_27_6 m3 : 10|1@1+ (1,0) [0|1] ""  HVESP01
 SG_ HVESP01_CellBalance_28_6 m3 : 11|1@1+ (1,0) [0|1] ""  HVESP01
 SG_ HVESP01_CellBalance_29_6 m3 : 12|1@1+ (1,0) [0|1] ""  HVESP01
 SG_ HVESP01_CellBalance_30_6 m3 : 13|1@1+ (1,0) [0|1] ""  HVESP01
 SG_ HVESP01_CellBalance_31_6 m3 : 14|1@1+ (1,0) [0|1] ""  HVESP01
 SG_ HVESP01_CellBalance_32_6 m3 : 15|1@1+ (1,0) [0|1] ""  HVESP01
 SG_ HVESP01_CellBalance_33_6 m4 : 8|1@1+ (1,0) [0|1] ""  HVESP01
 SG_ HVESP01_CellBalance_34_6 m4 : 9|1@1+ (1,0) [0|1] ""  HVESP01
 SG_ HVESP01_CellBalance_35_6 m4 : 10|1@1+ (1,0) [0|1] ""  HVESP01
 SG_ HVESP01_CellBalance_36_6 m4 : 11|1@1+ (1,0) [0|1] ""  HVESP01
 SG_ HVESP01_CellBalance_37_6 m4 : 12|1@1+ (1,0) [0|1] ""  HVESP01
 SG_ HVESP01_CellBalance_38_6 m4 : 13|1@1+ (1,0) [0|1] ""  HVESP01
 SG_ HVESP01_CellBalance_39_6 m4 : 14|1@1+ (1,0) [0|1] ""  HVESP01
 SG_ HVESP01_CellBalance_40_6 m4 : 15|1@1+ (1,0) [0|1] ""  HVESP01
 SG_ HVESP01_CellBalance_41_6 m5 : 8|1@1+ (1,0) [0|1] ""  HVESP01
 SG_ HVESP01_CellBalance_42_6 m5 : 9|1@1+ (1,0) [0|1] ""  HVESP01
 SG_ HVESP01_CellBalance_43_6 m5 : 10|1@1+ (1,0) [0|1] ""  HVESP01
 SG_ HVESP01_CellBalance_44_6 m5 : 11|1@1+ (1,0) [0|1] ""  HVESP01
 SG_ HVESP01_CellBalance_45_6 m5 : 12|1@1+ (1,0) [0|1] ""  HVESP01
 SG_ HVESP01_CellBalance_46_6 m5 : 13|1@1+ (1,0) [0|1] ""  HVESP01
 SG_ HVESP01_CellBalance_47_6 m5 : 14|1@1+ (1,0) [0|1] ""  HVESP01
 SG_ HVESP01_CellBalance_48_6 m5 : 15|1@1+ (1,0) [0|1] ""  HVESP01
 SG_ HVESP01_CellBalance_49_6 m6 : 8|1@1+ (1,0) [0|1] ""  HVESP01
 SG_ HVESP01_CellBalance_50_6 m6 : 9|1@1+ (1,0) [0|1] ""  HVESP01
 SG_ HVESP01_CellBalance_51_6 m6 : 10|1@1+ (1,0) [0|1] ""  HVESP01
 SG_ HVESP01_CellBalance_52_6 m6 : 11|1@1+ (1,0) [0|1] ""  HVESP01
 SG_ HVESP01_CellBalance_53_6 m6 : 12|1@1+ (1,0) [0|1] ""  HVESP01
 SG_ HVESP01_CellBalance_54_6 m6 : 13|1@1+ (1,0) [0|1] ""  HVESP01
 SG_ HVESP01_CellBalance_55_6 m6 : 14|1@1+ (1,0) [0|1] ""  HVESP01
 SG_ HVESP01_CellBalance_56_6 m6 : 15|1@1+ (1,0) [0|1] ""  HVESP01
 SG_ HVESP01_CellBalance_57_6 m7 : 8|1@1+ (1,0) [0|1] ""  HVESP01
 SG_ HVESP01_CellBalance_58_6 m7 : 9|1@1+ (1,0) [0|1] ""  HVESP01
 SG_ HVESP01_CellBalance_59_6 m7 : 10|1@1+ (1,0) [0|1] ""  HVESP01
 SG_ HVESP01_CellBalance_60_6 m7 : 11|1@1+ (1,0) [0|1] ""  HVESP01
 SG_ HVESP01_CellBalance_61_6 m7 : 12|1@1+ (1,0) [0|1] ""  HVESP01
 SG_ HVESP01_CellBalance_62_6 m7 : 13|1@1+ (1,0) [0|1] ""  HVESP01
 SG_ HVESP01_CellBalance_63_6 m7 : 14|1@1+ (1,0) [0|1] ""  HVESP01
 SG_ HVESP01_CellBalance_64_6 m7 : 15|1@1+ (1,0) [0|1] ""  HVESP01
 SG_ HVESP01_CellBalance_65_6 m8 : 8|1@1+ (1,0) [0|1] ""  HVESP01
 SG_ HVESP01_CellBalance_66_6 m8 : 9|1@1+ (1,0) [0|1] ""  HVESP01
 SG_ HVESP01_CellBalance_67_6 m8 : 10|1@1+ (1,0) [0|1] ""  HVESP01
 SG_ HVESP01_CellBalance_68_6 m8 : 11|1@1+ (1,0) [0|1] ""  HVESP01
 SG_ HVESP01_CellBalance_69_6 m8 : 12|1@1+ (1,0) [0|1] ""  HVESP01
 SG_ HVESP01_CellBalance_70_6 m8 : 13|1@1+ (1,0) [0|1] ""  HVESP01
 SG_ HVESP01_CellBalance_71_6 m8 : 14|1@1+ (1,0) [0|1] ""  HVESP01
 SG_ HVESP01_CellBalance_72_6 m8 : 15|1@1+ (1,0) [0|1] ""  HVESP01
 SG_ HVESP01_CellBalance_73_6 m9 : 8|1@1+ (1,0) [0|1] ""  HVESP01
 SG_ HVESP01_CellBalance_74_6 m9 : 9|1@1+ (1,0) [0|1] ""  HVESP01
 SG_ HVESP01_CellBalance_75_6 m9 : 10|1@1+ (1,0) [0|1] ""  HVESP01
 SG_ HVESP01_CellBalance_76_6 m9 : 11|1@1+ (1,0) [0|1] ""  HVESP01
 SG_ HVESP01_CellBalance_77_6 m9 : 12|1@1+ (1,0) [0|1] ""  HVESP01
 SG_ HVESP01_CellBalance_78_6 m9 : 13|1@1+ (1,0) [0|1] ""  HVESP01
 SG_ HVESP01_CellBalance_79_6 m9 : 14|1@1+ (1,0) [0|1] ""  HVESP01
 SG_ HVESP01_CellBalance_80_6 m9 : 15|1@1+ (1,0) [0|1] ""  HVESP01
 SG_ HVESP01_CellBalance_81_6 m10 : 8|1@1+ (1,0) [0|1] ""  HVESP01
 SG_ HVESP01_CellBalance_82_6 m10 : 9|1@1+ (1,0) [0|1] ""  HVESP01
 SG_ HVESP01_CellBalance_83_6 m10 : 10|1@1+ (1,0) [0|1] ""  HVESP01
 SG_ HVESP01_CellBalance_84_6 m10 : 11|1@1+ (1,0) [0|1] ""  HVESP01
 SG_ HVESP01_CellBalance_85_6 m10 : 12|1@1+ (1,0) [0|1] ""  HVESP01
 SG_ HVESP01_CellBalance_86_6 m10 : 13|1@1+ (1,0) [0|1] ""  HVESP01
 SG_ HVESP01_CellBalance_87_6 m10 : 14|1@1+ (1,0) [0|1] ""  HVESP01
 SG_ HVESP01_CellBalance_88_6 m10 : 15|1@1+ (1,0) [0|1] ""  HVESP01
 SG_ HVESP01_CellBalance_89_6 m11 : 8|1@1+ (1,0) [0|1] ""  HVESP01
 SG_ HVESP01_CellBalance_90_6 m11 : 9|1@1+ (1,0) [0|1] ""  HVESP01
 SG_ HVESP01_CellBalance_91_6 m11 : 10|1@1+ (1,0) [0|1] ""  HVESP01
 SG_ HVESP01_CellBalance_92_6 m11 : 11|1@1+ (1,0) [0|1] ""  HVESP01
 SG_ HVESP01_CellBalance_93_6 m11 : 12|1@1+ (1,0) [0|1] ""  HVESP01
 SG_ HVESP01_CellBalance_94_6 m11 : 13|1@1+ (1,0) [0|1] ""  HVESP01
 SG_ HVESP01_CellBalance_95_6 m11 : 14|1@1+ (1,0) [0|1] ""  HVESP01
 SG_ HVESP01_CellBalance_96_6 m11 : 15|1@1+ (1,0) [0|1] ""  HVESP01
 SG_ HVESP01_CellBalance_97_6 m12 : 8|1@1+ (1,0) [0|1] ""  HVESP01
 SG_ HVESP01_CellBalance_98_6 m12 : 9|1@1+ (1,0) [0|1] ""  HVESP01
 SG_ HVESP01_CellBalance_99_6 m12 : 10|1@1+ (1,0) [0|1] ""  HVESP01
 SG_ HVESP01_CellBalance_100_6 m12 : 11|1@1+ (1,0) [0|1] ""  HVESP01
 SG_ HVESP01_CellBalance_101_6 m12 : 12|1@1+ (1,0) [0|1] ""  HVESP01
 SG_ HVESP01_CellBalance_102_6 m12 : 13|1@1+ (1,0) [0|1] ""  HVESP01
 SG_ HVESP01_CellBalance_103_6 m12 : 14|1@1+ (1,0) [0|1] ""  HVESP01
 SG_ HVESP01_CellBalance_104_6 m12 : 15|1@1+ (1,0) [0|1] ""  HVESP01
 SG_ HVESP01_CellBalance_105_6 m13 : 8|1@1+ (1,0) [0|1] ""  HVESP01
 SG_ HVESP01_CellBalance_106_6 m13 : 9|1@1+ (1,0) [0|1] ""  HVESP01
 SG_ HVESP01_CellBalance_107_6 m13 : 10|1@1+ (1,0) [0|1] ""  HVESP01
 SG_ HVESP01_CellBalance_108_6 m13 : 11|1@1+ (1,0) [0|1] ""  HVESP01
 SG_ HVESP01_CellBalance_109_6 m13 : 12|1@1+ (1,0) [0|1] ""  HVESP01
 SG_ HVESP01_CellBalance_110_6 m13 : 13|1@1+ (1,0) [0|1] ""  HVESP01
 SG_ HVESP01_CellBalance_111_6 m13 : 14|1@1+ (1,0) [0|1] ""  HVESP01
 SG_ HVESP01_CellBalance_112_6 m13 : 15|1@1+ (1,0) [0|1] ""  HVESP01
 SG_ HVESP01_CellBalance_113_6 m14 : 8|1@1+ (1,0) [0|1] ""  HVESP01
 SG_ HVESP01_CellBalance_114_6 m14 : 9|1@1+ (1,0) [0|1] ""  HVESP01
 SG_ HVESP01_CellBalance_115_6 m14 : 10|1@1+ (1,0) [0|1] ""  HVESP01
 SG_ HVESP01_CellBalance_116_6 m14 : 11|1@1+ (1,0) [0|1] ""  HVESP01
 SG_ HVESP01_CellBalance_117_6 m14 : 12|1@1+ (1,0) [0|1] ""  HVESP01
 SG_ HVESP01_CellBalance_118_6 m14 : 13|1@1+ (1,0) [0|1] ""  HVESP01
 SG_ HVESP01_CellBalance_119_6 m14 : 14|1@1+ (1,0) [0|1] ""  HVESP01
 SG_ HVESP01_CellBalance_120_6 m14 : 15|1@1+ (1,0) [0|1] ""  HVESP01
 SG_ HVESP01_CellBalance_121_6 m15 : 8|1@1+ (1,0) [0|1] ""  HVESP01
 SG_ HVESP01_CellBalance_122_6 m15 : 9|1@1+ (1,0) [0|1] ""  HVESP01
 SG_ HVESP01_CellBalance_123_6 m15 : 10|1@1+ (1,0) [0|1] ""  HVESP01
 SG_ HVESP01_CellBalance_124_6 m15 : 11|1@1+ (1,0) [0|1] ""  HVESP01
 SG_ HVESP01_CellBalance_125_6 m15 : 12|1@1+ (1,0) [0|1] ""  HVESP01
 SG_ HVESP01_CellBalance_126_6 m15 : 13|1@1+ (1,0) [0|1] ""  HVESP01
 SG_ HVESP01_CellBalance_127_6 m15 : 14|1@1+ (1,0) [0|1] ""  HVESP01
 SG_ HVESP01_CellBalance_128_6 m15 : 15|1@1+ (1,0) [0|1] ""  HVESP01
 SG_ HVESP01_CellBalance_129_6 m16 : 8|1@1+ (1,0) [0|1] ""  HVESP01
 SG_ HVESP01_CellBalance_130_6 m16 : 9|1@1+ (1,0) [0|1] ""  HVESP01
 SG_ HVESP01_CellBalance_131_6 m16 : 10|1@1+ (1,0) [0|1] ""  HVESP01
 SG_ HVESP01_CellBalance_132_6 m16 : 11|1@1+ (1,0) [0|1] ""  HVESP01
 SG_ HVESP01_CellBalance_133_6 m16 : 12|1@1+ (1,0) [0|1] ""  HVESP01
 SG_ HVESP01_CellBalance_134_6 m16 : 13|1@1+ (1,0) [0|1] ""  HVESP01
 SG_ HVESP01_CellBalance_135_6 m16 : 14|1@1+ (1,0) [0|1] ""  HVESP01
 SG_ HVESP01_CellBalance_136_6 m16 : 15|1@1+ (1,0) [0|1] ""  HVESP01
 SG_ HVESP01_CellBalance_137_6 m17 : 8|1@1+ (1,0) [0|1] ""  HVESP01
 SG_ HVESP01_CellBalance_138_6 m17 : 9|1@1+ (1,0) [0|1] ""  HVESP01
 SG_ HVESP01_CellBalance_139_6 m17 : 10|1@1+ (1,0) [0|1] ""  HVESP01
 SG_ HVESP01_CellBalance_140_6 m17 : 11|1@1+ (1,0) [0|1] ""  HVESP01
 SG_ HVESP01_CellBalance_141_6 m17 : 12|1@1+ (1,0) [0|1] ""  HVESP01
 SG_ HVESP01_CellBalance_142_6 m17 : 13|1@1+ (1,0) [0|1] ""  HVESP01
 SG_ HVESP01_CellBalance_143_6 m17 : 14|1@1+ (1,0) [0|1] ""  HVESP01
 SG_ HVESP01_CellBalance_144_6 m17 : 15|1@1+ (1,0) [0|1] ""  HVESP01
 SG_ HVESP01_CellBalance_145_6 m18 : 8|1@1+ (1,0) [0|1] ""  HVESP01
 SG_ HVESP01_CellBalance_146_6 m18 : 9|1@1+ (1,0) [0|1] ""  HVESP01
 SG_ HVESP01_CellBalance_147_6 m18 : 10|1@1+ (1,0) [0|1] ""  HVESP01
 SG_ HVESP01_CellBalance_148_6 m18 : 11|1@1+ (1,0) [0|1] ""  HVESP01
 SG_ HVESP01_CellBalance_149_6 m18 : 12|1@1+ (1,0) [0|1] ""  HVESP01
 SG_ HVESP01_CellBalance_150_6 m18 : 13|1@1+ (1,0) [0|1] ""  HVESP01
 SG_ HVESP01_CellBalance_151_6 m18 : 14|1@1+ (1,0) [0|1] ""  HVESP01
 SG_ HVESP01_CellBalance_152_6 m18 : 15|1@1+ (1,0) [0|1] ""  HVESP01
 SG_ HVESP01_CellBalance_153_6 m19 : 8|1@1+ (1,0) [0|1] ""  HVESP01
 SG_ HVESP01_CellBalance_154_6 m19 : 9|1@1+ (1,0) [0|1] ""  HVESP01
 SG_ HVESP01_CellBalance_155_6 m19 : 10|1@1+ (1,0) [0|1] ""  HVESP01
 SG_ HVESP01_CellBalance_156_6 m19 : 11|1@1+ (1,0) [0|1] ""  HVESP01
 SG_ HVESP01_CellBalance_157_6 m19 : 12|1@1+ (1,0) [0|1] ""  HVESP01
 SG_ HVESP01_CellBalance_158_6 m19 : 13|1@1+ (1,0) [0|1] ""  HVESP01
 SG_ HVESP01_CellBalance_159_6 m19 : 14|1@1+ (1,0) [0|1] ""  HVESP01
 SG_ HVESP01_CellBalance_160_6 m19 : 15|1@1+ (1,0) [0|1] ""  HVESP01
 SG_ HVESP01_CellBalance_161_6 m20 : 8|1@1+ (1,0) [0|1] ""  HVESP01
 SG_ HVESP01_CellBalance_162_6 m20 : 9|1@1+ (1,0) [0|1] ""  HVESP01
 SG_ HVESP01_CellBalance_163_6 m20 : 10|1@1+ (1,0) [0|1] ""  HVESP01
 SG_ HVESP01_CellBalance_164_6 m20 : 11|1@1+ (1,0) [0|1] ""  HVESP01
 SG_ HVESP01_CellBalance_165_6 m20 : 12|1@1+ (1,0) [0|1] ""  HVESP01
 SG_ HVESP01_CellBalance_166_6 m20 : 13|1@1+ (1,0) [0|1] ""  HVESP01
 SG_ HVESP01_CellBalance_167_6 m20 : 14|1@1+ (1,0) [0|1] ""  HVESP01
 SG_ HVESP01_CellBalance_168_6 m20 : 15|1@1+ (1,0) [0|1] ""  HVESP01
 SG_ HVESP01_CellBalance_169_6 m21 : 8|1@1+ (1,0) [0|1] ""  HVESP01
 SG_ HVESP01_CellBalance_170_6 m21 : 9|1@1+ (1,0) [0|1] ""  HVESP01
 SG_ HVESP01_CellBalance_171_6 m21 : 10|1@1+ (1,0) [0|1] ""  HVESP01
 SG_ HVESP01_CellBalance_172_6 m21 : 11|1@1+ (1,0) [0|1] ""  HVESP01
 SG_ HVESP01_CellBalance_173_6 m21 : 12|1@1+ (1,0) [0|1] ""  HVESP01
 SG_ HVESP01_CellBalance_174_6 m21 : 13|1@1+ (1,0) [0|1] ""  HVESP01
 SG_ HVESP01_CellBalance_175_6 m21 : 14|1@1+ (1,0) [0|1] ""  HVESP01
 SG_ HVESP01_CellBalance_176_6 m21 : 15|1@1+ (1,0) [0|1] ""  HVESP01
 SG_ HVESP01_CellBalance_177_6 m22 : 8|1@1+ (1,0) [0|1] ""  HVESP01
 SG_ HVESP01_CellBalance_178_6 m22 : 9|1@1+ (1,0) [0|1] ""  HVESP01
 SG_ HVESP01_CellBalance_179_6 m22 : 10|1@1+ (1,0) [0|1] ""  HVESP01
 SG_ HVESP01_CellBalance_180_6 m22 : 11|1@1+ (1,0) [0|1] ""  HVESP01
 SG_ HVESP01_CellBalance_181_6 m22 : 12|1@1+ (1,0) [0|1] ""  HVESP01
 SG_ HVESP01_CellBalance_182_6 m22 : 13|1@1+ (1,0) [0|1] ""  HVESP01
 SG_ HVESP01_CellBalance_183_6 m22 : 14|1@1+ (1,0) [0|1] ""  HVESP01
 SG_ HVESP01_CellBalance_184_6 m22 : 15|1@1+ (1,0) [0|1] ""  HVESP01
 SG_ multiplexorcb_6 M : 0|8@1+ (1,0) [0|255] ""  HVESP01

BA_DEF_ BO_  "GenMsgDiag" ENUM  "No","Yes";
BA_DEF_ BO_  "GenMsgInstanced" STRING ;
BA_DEF_ SG_  "SigType" ENUM  "Default","Range","RangeSigned","ASCII","Discrete","Control","ReferencePGN","DTC","StringDelimiter","StringLength","StringLengthControl","MessageCounter","MessageChecksum";
BA_DEF_ SG_  "GenSigEVName" STRING ;
BA_DEF_ SG_  "GenSigILSupport" ENUM  "No","Yes";
BA_DEF_ SG_  "GenSigSendType" ENUM  "Cyclic","OnWrite","OnWriteWithRepetition","OnChange","OnChangeWithRepetition","IfActive","IfActiveWithRepetition","NoSigSendType";
BA_DEF_ SG_  "GenSigStartValue" INT 0 10000;
BA_DEF_ BO_  "GenMsgILSupport" ENUM  "No","Yes";
BA_DEF_ BO_  "GenMsgSendType" ENUM  "cyclic","NotUsed","IfActive","NotUsed","NotUsed","NotUsed","NotUsed","NotUsed","noMsgSendType";
BA_DEF_ BO_  "GenMsgRequestable" INT 0 1;
BA_DEF_ BO_  "GenMsgCycleTime" INT 0 3600000;
BA_DEF_ BO_  "VFrameFormat" ENUM  "StandardCAN","ExtendedCAN","reserved","J1939PG";
BA_DEF_ SG_  "SystemSignalLongSymbol" STRING ;
BA_DEF_ BO_  "SystemMessageLongSymbol" STRING ;
BA_DEF_DEF_  "GenMsgDiag" "No";
BA_DEF_DEF_  "GenMsgInstanced" "No";
BA_DEF_DEF_  "SigType" "Default";
BA_DEF_DEF_  "GenSigEVName" "Env@Nodename_@Signame";
BA_DEF_DEF_  "GenSigILSupport" "Yes";
BA_DEF_DEF_  "GenSigSendType" "NoSigSendType";
BA_DEF_DEF_  "GenSigStartValue" 0;
BA_DEF_DEF_  "GenMsgILSupport" "Yes";
BA_DEF_DEF_  "GenMsgSendType" "noMsgSendType";
BA_DEF_DEF_  "GenMsgRequestable" 1;
BA_DEF_DEF_  "GenMsgCycleTime" 0;
BA_DEF_DEF_  "VFrameFormat" "J1939PG";
BA_DEF_DEF_  "SystemSignalLongSymbol" "";
BA_DEF_DEF_  "SystemMessageLongSymbol" "";
BA_ "GenMsgInstanced" BO_ 2499742056 "False";
BA_ "GenMsgInstanced" BO_ 2499742057 "False";
BA_ "GenMsgInstanced" BO_ 2499742058 "False";
BA_ "GenMsgInstanced" BO_ 2499742059 "False";
BA_ "GenMsgInstanced" BO_ 2499742060 "False";
BA_ "GenMsgCycleTime" BO_ 2499742309 100;
BA_ "GenMsgInstanced" BO_ 2499742309 "False";
BA_ "GenMsgCycleTime" BO_ 2499742310 100;
BA_ "GenMsgInstanced" BO_ 2499742310 "False";
BA_ "GenMsgCycleTime" BO_ 2499742311 100;
BA_ "GenMsgInstanced" BO_ 2499742311 "False";
BA_ "GenMsgCycleTime" BO_ 2499742312 100;
BA_ "GenMsgInstanced" BO_ 2499742312 "False";
BA_ "GenMsgCycleTime" BO_ 2499742313 100;
BA_ "GenMsgInstanced" BO_ 2499742313 "False";
BA_ "GenMsgCycleTime" BO_ 2499742314 100;
BA_ "GenMsgInstanced" BO_ 2499742314 "False";
BA_ "GenMsgCycleTime" BO_ 2499742315 100;
BA_ "GenMsgInstanced" BO_ 2499742315 "False";
BA_ "GenMsgCycleTime" BO_ 2499742316 100;
BA_ "GenMsgInstanced" BO_ 2499742316 "False";
BA_ "GenMsgCycleTime" BO_ 2499742565 100;
BA_ "GenMsgInstanced" BO_ 2499742565 "False";
BA_ "GenMsgCycleTime" BO_ 2499742566 100;
BA_ "GenMsgInstanced" BO_ 2499742566 "False";
BA_ "GenMsgCycleTime" BO_ 2499742567 100;
BA_ "GenMsgInstanced" BO_ 2499742567 "False";
BA_ "GenMsgCycleTime" BO_ 2499742568 100;
BA_ "GenMsgInstanced" BO_ 2499742568 "False";
BA_ "GenMsgCycleTime" BO_ 2499742569 100;
BA_ "GenMsgInstanced" BO_ 2499742569 "False";
BA_ "GenMsgCycleTime" BO_ 2499742570 100;
BA_ "GenMsgInstanced" BO_ 2499742570 "False";
BA_ "GenMsgCycleTime" BO_ 2499742571 100;
BA_ "GenMsgInstanced" BO_ 2499742571 "False";
BA_ "GenMsgCycleTime" BO_ 2499742572 100;
BA_ "GenMsgInstanced" BO_ 2499742572 "False";
BA_ "VFrameFormat" BO_ 2499742821 1;
BA_ "GenMsgCycleTime" BO_ 2499742821 100;
BA_ "GenMsgInstanced" BO_ 2499742821 "False";
BA_ "VFrameFormat" BO_ 2499742822 1;
BA_ "GenMsgCycleTime" BO_ 2499742822 100;
BA_ "GenMsgInstanced" BO_ 2499742822 "False";
BA_ "VFrameFormat" BO_ 2499742823 1;
BA_ "GenMsgCycleTime" BO_ 2499742823 100;
BA_ "GenMsgInstanced" BO_ 2499742823 "False";
BA_ "VFrameFormat" BO_ 2499742824 1;
BA_ "GenMsgCycleTime" BO_ 2499742824 100;
BA_ "GenMsgInstanced" BO_ 2499742824 "False";
BA_ "VFrameFormat" BO_ 2499742825 1;
BA_ "GenMsgCycleTime" BO_ 2499742825 100;
BA_ "GenMsgInstanced" BO_ 2499742825 "False";
BA_ "VFrameFormat" BO_ 2499742826 1;
BA_ "GenMsgCycleTime" BO_ 2499742826 100;
BA_ "GenMsgInstanced" BO_ 2499742826 "False";
BA_ "VFrameFormat" BO_ 2499742827 1;
BA_ "GenMsgCycleTime" BO_ 2499742827 100;
BA_ "GenMsgInstanced" BO_ 2499742827 "False";
BA_ "VFrameFormat" BO_ 2499742828 1;
BA_ "GenMsgCycleTime" BO_ 2499742828 100;
BA_ "GenMsgInstanced" BO_ 2499742828 "False";
BA_ "VFrameFormat" BO_ 2499743077 1;
BA_ "GenMsgInstanced" BO_ 2499743077 "False";
BA_ "VFrameFormat" BO_ 2499743078 1;
BA_ "GenMsgInstanced" BO_ 2499743078 "False";
BA_ "VFrameFormat" BO_ 2499743079 1;
BA_ "GenMsgInstanced" BO_ 2499743079 "False";
BA_ "VFrameFormat" BO_ 2499743080 1;
BA_ "GenMsgInstanced" BO_ 2499743080 "False";
BA_ "VFrameFormat" BO_ 2499743081 1;
BA_ "GenMsgInstanced" BO_ 2499743081 "False";
BA_ "VFrameFormat" BO_ 2499743082 1;
BA_ "GenMsgInstanced" BO_ 2499743082 "False";
BA_ "VFrameFormat" BO_ 2499743083 1;
BA_ "GenMsgInstanced" BO_ 2499743083 "False";
BA_ "VFrameFormat" BO_ 2499743084 1;
BA_ "GenMsgInstanced" BO_ 2499743084 "False";
BA_ "GenMsgInstanced" BO_ 2499743333 "False";
BA_ "GenMsgInstanced" BO_ 2499743334 "False";
BA_ "GenMsgInstanced" BO_ 2499743335 "False";
BA_ "GenMsgInstanced" BO_ 2499743336 "False";
BA_ "GenMsgInstanced" BO_ 2499743337 "False";
BA_ "GenMsgInstanced" BO_ 2499743338 "False";
BA_ "SystemSignalLongSymbol" SG_ 2499743077 HVESP01_SerNum_PartNo_SubVersion "HVESP01_SerNum_PartNo_SubVersion_1";
BA_ "SystemSignalLongSymbol" SG_ 2499743078 HVESP01_SerNum_PartNo_SubVe_0000 "HVESP01_SerNum_PartNo_SubVersion_2";
BA_ "SystemSignalLongSymbol" SG_ 2499743079 HVESP01_SerNum_PartNo_SubVe_0001 "HVESP01_SerNum_PartNo_SubVersion_3";
BA_ "SystemSignalLongSymbol" SG_ 2499743080 HVESP01_SerNum_PartNo_SubVe_0002 "HVESP01_SerNum_PartNo_SubVersion_4";
BA_ "SystemSignalLongSymbol" SG_ 2499743081 HVESP01_SerNum_PartNo_SubVe_0003 "HVESP01_SerNum_PartNo_SubVersion_5";
BA_ "SystemSignalLongSymbol" SG_ 2499743082 HVESP01_SerNum_PartNo_SubVe_0004 "HVESP01_SerNum_PartNo_SubVersion_6";
BA_ "SystemSignalLongSymbol" SG_ 2499743083 HVESP01_SerNum_PartNo_SubVe_0005 "HVESP01_SerNum_PartNo_SubVersion_7";
BA_ "SystemSignalLongSymbol" SG_ 2499743084 HVESP01_SerNum_PartNo_SubVe_0006 "HVESP01_SerNum_PartNo_SubVersion_8";
VAL_ 2499742821 HVESP01_fcposPackConStatusReq_1 3 "DontCare" 2 "EmergencyContactorClose" 1 "CloseContactor" 0 "OpenContactor" ;
VAL_ 2499742821 HVESP01_fcnegPackConStatusReq_1 3 "DontCare" 2 "EmergencyContactorClose" 1 "CloseContactor" 0 "OpenContactor" ;
VAL_ 2499742821 HVESP01_packstate_1 7 "Disengage" 6 "Connected" 5 "ExternalIsolationCheck" 4 "PrepareBusJoin" 3 "PrepareBusPrecharge" 2 "StandbyReady" 1 "StandbyNotReady" 0 "StandbyInit" ;
VAL_ 2499742821 HVESP01_negPackConStatusReq_1 3 "DontCare" 2 "EmergencyContactorClose" 1 "CloseContactor" 0 "OpenContactor" ;
VAL_ 2499742821 HVESP01_posPackConStatusReq_1 3 "DontCare" 2 "EmergencyContactorClose" 1 "CloseContactor" 0 "OpenContactor" ;
VAL_ 2499742821 HVESP01_prechargeConStatusReq_1 3 "DontCare" 2 "EmergencyContactorClose" 1 "CloseContactor" 0 "OpenContactor" ;
VAL_ 2499742822 HVESP01_fcposPackConStatusReq_2 3 "DontCare" 2 "EmergencyContactorClose" 1 "CloseContactor" 0 "OpenContactor" ;
VAL_ 2499742822 HVESP01_fcnegPackConStatusReq_2 3 "DontCare" 2 "EmergencyContactorClose" 1 "CloseContactor" 0 "OpenContactor" ;
VAL_ 2499742822 HVESP01_packstate_2 7 "Disengage" 6 "Connected" 5 "ExternalIsolationCheck" 4 "PrepareBusJoin" 3 "PrepareBusPrecharge" 2 "StandbyReady" 1 "StandbyNotReady" 0 "StandbyInit" ;
VAL_ 2499742822 HVESP01_negPackConStatusReq_2 3 "DontCare" 2 "EmergencyContactorClose" 1 "CloseContactor" 0 "OpenContactor" ;
VAL_ 2499742822 HVESP01_posPackConStatusReq_2 3 "DontCare" 2 "EmergencyContactorClose" 1 "CloseContactor" 0 "OpenContactor" ;
VAL_ 2499742822 HVESP01_prechargeConStatusReq_2 3 "DontCare" 2 "EmergencyContactorClose" 1 "CloseContactor" 0 "OpenContactor" ;
VAL_ 2499742823 HVESP01_fcposPackConStatusReq_3 3 "DontCare" 2 "EmergencyContactorClose" 1 "CloseContactor" 0 "OpenContactor" ;
VAL_ 2499742823 HVESP01_fcnegPackConStatusReq_3 3 "DontCare" 2 "EmergencyContactorClose" 1 "CloseContactor" 0 "OpenContactor" ;
VAL_ 2499742823 HVESP01_packstate_3 7 "Disengage" 6 "Connected" 5 "ExternalIsolationCheck" 4 "PrepareBusJoin" 3 "PrepareBusPrecharge" 2 "StandbyReady" 1 "StandbyNotReady" 0 "StandbyInit" ;
VAL_ 2499742823 HVESP01_negPackConStatusReq_3 3 "DontCare" 2 "EmergencyContactorClose" 1 "CloseContactor" 0 "OpenContactor" ;
VAL_ 2499742823 HVESP01_posPackConStatusReq_3 3 "DontCare" 2 "EmergencyContactorClose" 1 "CloseContactor" 0 "OpenContactor" ;
VAL_ 2499742823 HVESP01_prechargeConStatusReq_3 3 "DontCare" 2 "EmergencyContactorClose" 1 "CloseContactor" 0 "OpenContactor" ;
VAL_ 2499742824 HVESP01_fcposPackConStatusReq_4 3 "DontCare" 2 "EmergencyContactorClose" 1 "CloseContactor" 0 "OpenContactor" ;
VAL_ 2499742824 HVESP01_fcnegPackConStatusReq_4 3 "DontCare" 2 "EmergencyContactorClose" 1 "CloseContactor" 0 "OpenContactor" ;
VAL_ 2499742824 HVESP01_packstate_4 7 "Disengage" 6 "Connected" 5 "ExternalIsolationCheck" 4 "PrepareBusJoin" 3 "PrepareBusPrecharge" 2 "StandbyReady" 1 "StandbyNotReady" 0 "StandbyInit" ;
VAL_ 2499742824 HVESP01_negPackConStatusReq_4 3 "DontCare" 2 "EmergencyContactorClose" 1 "CloseContactor" 0 "OpenContactor" ;
VAL_ 2499742824 HVESP01_posPackConStatusReq_4 3 "DontCare" 2 "EmergencyContactorClose" 1 "CloseContactor" 0 "OpenContactor" ;
VAL_ 2499742824 HVESP01_prechargeConStatusReq_4 3 "DontCare" 2 "EmergencyContactorClose" 1 "CloseContactor" 0 "OpenContactor" ;
VAL_ 2499742825 HVESP01_fcposPackConStatusReq_5 3 "DontCare" 2 "EmergencyContactorClose" 1 "CloseContactor" 0 "OpenContactor" ;
VAL_ 2499742825 HVESP01_fcnegPackConStatusReq_5 3 "DontCare" 2 "EmergencyContactorClose" 1 "CloseContactor" 0 "OpenContactor" ;
VAL_ 2499742825 HVESP01_packstate_5 7 "Disengage" 6 "Connected" 5 "ExternalIsolationCheck" 4 "PrepareBusJoin" 3 "PrepareBusPrecharge" 2 "StandbyReady" 1 "StandbyNotReady" 0 "StandbyInit" ;
VAL_ 2499742825 HVESP01_negPackConStatusReq_5 3 "DontCare" 2 "EmergencyContactorClose" 1 "CloseContactor" 0 "OpenContactor" ;
VAL_ 2499742825 HVESP01_posPackConStatusReq_5 3 "DontCare" 2 "EmergencyContactorClose" 1 "CloseContactor" 0 "OpenContactor" ;
VAL_ 2499742825 HVESP01_prechargeConStatusReq_5 3 "DontCare" 2 "EmergencyContactorClose" 1 "CloseContactor" 0 "OpenContactor" ;
VAL_ 2499742826 HVESP01_fcposPackConStatusReq_6 3 "DontCare" 2 "EmergencyContactorClose" 1 "CloseContactor" 0 "OpenContactor" ;
VAL_ 2499742826 HVESP01_fcnegPackConStatusReq_6 3 "DontCare" 2 "EmergencyContactorClose" 1 "CloseContactor" 0 "OpenContactor" ;
VAL_ 2499742826 HVESP01_packstate_6 7 "Disengage" 6 "Connected" 5 "ExternalIsolationCheck" 4 "PrepareBusJoin" 3 "PrepareBusPrecharge" 2 "StandbyReady" 1 "StandbyNotReady" 0 "StandbyInit" ;
VAL_ 2499742826 HVESP01_negPackConStatusReq_6 3 "DontCare" 2 "EmergencyContactorClose" 1 "CloseContactor" 0 "OpenContactor" ;
VAL_ 2499742826 HVESP01_posPackConStatusReq_6 3 "DontCare" 2 "EmergencyContactorClose" 1 "CloseContactor" 0 "OpenContactor" ;
VAL_ 2499742826 HVESP01_prechargeConStatusReq_6 3 "DontCare" 2 "EmergencyContactorClose" 1 "CloseContactor" 0 "OpenContactor" ;
VAL_ 2499742827 HVESP01_fcposPackConStatusReq_7 3 "DontCare" 2 "EmergencyContactorClose" 1 "CloseContactor" 0 "OpenContactor" ;
VAL_ 2499742827 HVESP01_fcnegPackConStatusReq_7 3 "DontCare" 2 "EmergencyContactorClose" 1 "CloseContactor" 0 "OpenContactor" ;
VAL_ 2499742827 HVESP01_packstate_7 7 "Disengage" 6 "Connected" 5 "ExternalIsolationCheck" 4 "PrepareBusJoin" 3 "PrepareBusPrecharge" 2 "StandbyReady" 1 "StandbyNotReady" 0 "StandbyInit" ;
VAL_ 2499742827 HVESP01_negPackConStatusReq_7 3 "DontCare" 2 "EmergencyContactorClose" 1 "CloseContactor" 0 "OpenContactor" ;
VAL_ 2499742827 HVESP01_posPackConStatusReq_7 3 "DontCare" 2 "EmergencyContactorClose" 1 "CloseContactor" 0 "OpenContactor" ;
VAL_ 2499742827 HVESP01_prechargeConStatusReq_7 3 "DontCare" 2 "EmergencyContactorClose" 1 "CloseContactor" 0 "OpenContactor" ;
VAL_ 2499742828 HVESP01_fcposPackConStatusReq_8 3 "DontCare" 2 "EmergencyContactorClose" 1 "CloseContactor" 0 "OpenContactor" ;
VAL_ 2499742828 HVESP01_fcnegPackConStatusReq_8 3 "DontCare" 2 "EmergencyContactorClose" 1 "CloseContactor" 0 "OpenContactor" ;
VAL_ 2499742828 HVESP01_packstate_8 7 "Disengage" 6 "Connected" 5 "ExternalIsolationCheck" 4 "PrepareBusJoin" 3 "PrepareBusPrecharge" 2 "StandbyReady" 1 "StandbyNotReady" 0 "StandbyInit" ;
VAL_ 2499742828 HVESP01_negPackConStatusReq_8 3 "DontCare" 2 "EmergencyContactorClose" 1 "CloseContactor" 0 "OpenContactor" ;
VAL_ 2499742828 HVESP01_posPackConStatusReq_8 3 "DontCare" 2 "EmergencyContactorClose" 1 "CloseContactor" 0 "OpenContactor" ;
VAL_ 2499742828 HVESP01_prechargeConStatusReq_8 3 "DontCare" 2 "EmergencyContactorClose" 1 "CloseContactor" 0 "OpenContactor" ;
VAL_ 2499743077 HVESP01_SerNum_Location_1 2 "Springboro" 1 "Lake Orion Tech Center" 0 "Unknown" ;
VAL_ 2499743077 HVESP01_SerNum_PartNo_SubVersion 825 "ZZ" 824 "ZY" 823 "ZX" 822 "ZW" 821 "ZV" 820 "ZU" 819 "ZT" 818 "ZS" 817 "ZR" 816 "ZQ" 815 "ZP" 814 "ZO" 813 "ZN" 812 "ZM" 811 "ZL" 810 "ZK" 809 "ZJ" 808 "ZI" 807 "ZH" 806 "ZG" 805 "ZF" 804 "ZE" 803 "ZD" 802 "ZC" 801 "ZB" 800 "ZA" 793 "YZ" 792 "YY" 791 "YX" 790 "YW" 789 "YV" 788 "YU" 787 "YT" 786 "YS" 785 "YR" 784 "YQ" 783 "YP" 782 "YO" 781 "YN" 780 "YM" 779 "YL" 778 "YK" 777 "YJ" 776 "YI" 775 "YH" 774 "YG" 773 "YF" 772 "YE" 771 "YD" 770 "YC" 769 "YB" 768 "YA" 761 "XZ" 760 "XY" 759 "XX" 758 "XW" 757 "XV" 756 "XU" 755 "XT" 754 "XS" 753 "XR" 752 "XQ" 751 "XP" 750 "XO" 749 "XN" 748 "XM" 747 "XL" 746 "XK" 745 "XJ" 744 "XI" 743 "XH" 742 "XG" 741 "XF" 740 "XE" 739 "XD" 738 "XC" 737 "XB" 736 "XA" 729 "WZ" 728 "WY" 727 "WX" 726 "WW" 725 "WV" 724 "WU" 723 "WT" 722 "WS" 721 "WR" 720 "WQ" 719 "WP" 718 "WO" 717 "WN" 716 "WM" 715 "WL" 714 "WK" 713 "WJ" 712 "WI" 711 "WH" 710 "WG" 709 "WF" 708 "WE" 707 "WD" 706 "WC" 705 "WB" 704 "WA" 697 "VZ" 696 "VY" 695 "VX" 694 "VW" 693 "VV" 692 "VU" 691 "VT" 690 "VS" 689 "VR" 688 "VQ" 687 "VP" 686 "VO" 685 "VN" 684 "VM" 683 "VL" 682 "VK" 681 "VJ" 680 "VI" 679 "VH" 678 "VG" 677 "VF" 676 "VE" 675 "VD" 674 "VC" 673 "VB" 672 "VA" 665 "UZ" 664 "UY" 663 "UX" 662 "UW" 661 "UV" 660 "UU" 659 "UT" 658 "US" 657 "UR" 656 "UQ" 655 "UP" 654 "UO" 653 "UN" 652 "UM" 651 "UL" 650 "UK" 649 "UJ" 648 "UI" 647 "UH" 646 "UG" 645 "UF" 644 "UE" 643 "UD" 642 "UC" 641 "UB" 640 "UA" 633 "TZ" 632 "TY" 631 "TX" 630 "TW" 629 "TV" 628 "TU" 627 "TT" 626 "TS" 625 "TR" 624 "TQ" 623 "TP" 622 "TO" 621 "TN" 620 "TM" 619 "TL" 618 "TK" 617 "TJ" 616 "TI" 615 "TH" 614 "TG" 613 "TF" 612 "TE" 611 "TD" 610 "TC" 609 "TB" 608 "TA" 601 "SZ" 600 "SY" 599 "SX" 598 "SW" 597 "SV" 596 "SU" 595 "ST" 594 "SS" 593 "SR" 592 "SQ" 591 "SP" 590 "SO" 589 "SN" 588 "SM" 587 "SL" 586 "SK" 585 "SJ" 584 "SI" 583 "SH" 582 "SG" 581 "SF" 580 "SE" 579 "SD" 578 "SC" 577 "SB" 576 "SA" 569 "RZ" 568 "RY" 567 "RX" 566 "RW" 565 "RV" 564 "RU" 563 "RT" 562 "RS" 561 "RR" 560 "RQ" 559 "RP" 558 "RO" 557 "RN" 556 "RM" 555 "RL" 554 "RK" 553 "RJ" 552 "RI" 551 "RH" 550 "RG" 549 "RF" 548 "RE" 547 "RD" 546 "RC" 545 "RB" 544 "RA" 537 "QZ" 536 "QY" 535 "QX" 534 "QW" 533 "QV" 532 "QU" 531 "QT" 530 "QS" 529 "QR" 528 "QQ" 527 "QP" 526 "QO" 525 "QN" 524 "QM" 523 "QL" 522 "QK" 521 "QJ" 520 "QI" 519 "QH" 518 "QG" 517 "QF" 516 "QE" 515 "QD" 514 "QC" 513 "QB" 512 "QA" 505 "PZ" 504 "PY" 503 "PX" 502 "PW" 501 "PV" 500 "PU" 499 "PT" 498 "PS" 497 "PR" 496 "PQ" 495 "PP" 494 "PO" 493 "PN" 492 "PM" 491 "PL" 490 "PK" 489 "PJ" 488 "PI" 487 "PH" 486 "PG" 485 "PF" 484 "PE" 483 "PD" 482 "PC" 481 "PB" 480 "PA" 473 "OZ" 472 "OY" 471 "OX" 470 "OW" 469 "OV" 468 "OU" 467 "OT" 466 "OS" 465 "OR" 464 "OQ" 463 "OP" 462 "OO" 461 "ON" 460 "OM" 459 "OL" 458 "OK" 457 "OJ" 456 "OI" 455 "OH" 454 "OG" 453 "OF" 452 "OE" 451 "OD" 450 "OC" 449 "OB" 448 "OA" 441 "NZ" 440 "NY" 439 "NX" 438 "NW" 437 "NV" 436 "NU" 435 "NT" 434 "NS" 433 "NR" 432 "NQ" 431 "NP" 430 "NO" 429 "NN" 428 "NM" 427 "NL" 426 "NK" 425 "NJ" 424 "NI" 423 "NH" 422 "NG" 421 "NF" 420 "NE" 419 "ND" 418 "NC" 417 "NB" 416 "NA" 409 "MZ" 408 "MY" 407 "MX" 406 "MW" 405 "MV" 404 "MU" 403 "MT" 402 "MS" 401 "MR" 400 "MQ" 399 "MP" 398 "MO" 397 "MN" 396 "MM" 395 "ML" 394 "MK" 393 "MJ" 392 "MI" 391 "MH" 390 "MG" 389 "MF" 388 "ME" 387 "MD" 386 "MC" 385 "MB" 384 "MA" 377 "LZ" 376 "LY" 375 "LX" 374 "LW" 373 "LV" 372 "LU" 371 "LT" 370 "LS" 369 "LR" 368 "LQ" 367 "LP" 366 "LO" 365 "LN" 364 "LM" 363 "LL" 362 "LK" 361 "LJ" 360 "LI" 359 "LH" 358 "LG" 357 "LF" 356 "LE" 355 "LD" 354 "LC" 353 "LB" 352 "LA" 345 "KZ" 344 "KY" 343 "KX" 342 "KW" 341 "KV" 340 "KU" 339 "KT" 338 "KS" 337 "KR" 336 "KQ" 335 "KP" 334 "KO" 333 "KN" 332 "KM" 331 "KL" 330 "KK" 329 "KJ" 328 "KI" 327 "KH" 326 "KG" 325 "KF" 324 "KE" 323 "KD" 322 "KC" 321 "KB" 320 "KA" 313 "JZ" 312 "JY" 311 "JX" 310 "JW" 309 "JV" 308 "JU" 307 "JT" 306 "JS" 305 "JR" 304 "JQ" 303 "JP" 302 "JO" 301 "JN" 300 "JM" 299 "JL" 298 "JK" 297 "JJ" 296 "JI" 295 "JH" 294 "JG" 293 "JF" 292 "JE" 291 "JD" 290 "JC" 289 "JB" 288 "JA" 281 "IZ" 280 "IY" 279 "IX" 278 "IW" 277 "IV" 276 "IU" 275 "IT" 274 "IS" 273 "IR" 272 "IQ" 271 "IP" 270 "IO" 269 "IN" 268 "IM" 267 "IL" 266 "IK" 265 "IJ" 264 "II" 263 "IH" 262 "IG" 261 "IF" 260 "IE" 259 "ID" 258 "IC" 257 "IB" 256 "IA" 249 "HZ" 248 "HY" 247 "HX" 246 "HW" 245 "HV" 244 "HU" 243 "HT" 242 "HS" 241 "HR" 240 "HQ" 239 "HP" 238 "HO" 237 "HN" 236 "HM" 235 "HL" 234 "HK" 233 "HJ" 232 "HI" 231 "HH" 230 "HG" 229 "HF" 228 "HE" 227 "HD" 226 "HC" 225 "HB" 224 "HA" 217 "GZ" 216 "GY" 215 "GX" 214 "GW" 213 "GV" 212 "GU" 211 "GT" 210 "GS" 209 "GR" 208 "GQ" 207 "GP" 206 "GO" 205 "GN" 204 "GM" 203 "GL" 202 "GK" 201 "GJ" 200 "GI" 199 "GH" 198 "GG" 197 "GF" 196 "GE" 195 "GD" 194 "GC" 193 "GB" 192 "GA" 185 "FZ" 184 "FY" 183 "FX" 182 "FW" 181 "FV" 180 "FU" 179 "FT" 178 "FS" 177 "FR" 176 "FQ" 175 "FP" 174 "FO" 173 "FN" 172 "FM" 171 "FL" 170 "FK" 169 "FJ" 168 "FI" 167 "FH" 166 "FG" 165 "FF" 164 "FE" 163 "FD" 162 "FC" 161 "FB" 160 "FA" 153 "EZ" 152 "EY" 151 "EX" 150 "EW" 149 "EV" 148 "EU" 147 "ET" 146 "ES" 145 "ER" 144 "EQ" 143 "EP" 142 "EO" 141 "EN" 140 "EM" 139 "EL" 138 "EK" 137 "EJ" 136 "EI" 135 "EH" 134 "EG" 133 "EF" 132 "EE" 131 "ED" 130 "EC" 129 "EB" 128 "EA" 121 "DZ" 120 "DY" 119 "DX" 118 "DW" 117 "DV" 116 "DU" 115 "DT" 114 "DS" 113 "DR" 112 "DQ" 111 "DP" 110 "DO" 109 "DN" 108 "DM" 107 "DL" 106 "DK" 105 "DJ" 104 "DI" 103 "DH" 102 "DG" 101 "DF" 100 "DE" 99 "DD" 98 "DC" 97 "DB" 96 "DA" 89 "CZ" 88 "CY" 87 "CX" 86 "CW" 85 "CV" 84 "CU" 83 "CT" 82 "CS" 81 "CR" 80 "CQ" 79 "CP" 78 "CO" 77 "CN" 76 "CM" 75 "CL" 74 "CK" 73 "CJ" 72 "CI" 71 "CH" 70 "CG" 69 "CF" 68 "CE" 67 "CD" 66 "CC" 65 "CB" 64 "CA" 57 "BZ" 56 "BY" 55 "BX" 54 "BW" 53 "BV" 52 "BU" 51 "BT" 50 "BS" 49 "BR" 48 "BQ" 47 "BP" 46 "BO" 45 "BN" 44 "BM" 43 "BL" 42 "BK" 41 "BJ" 40 "BI" 39 "BH" 38 "BG" 37 "BF" 36 "BE" 35 "BD" 34 "BC" 33 "BB" 32 "BA" 25 "AZ" 24 "AY" 23 "AX" 22 "AW" 21 "AV" 20 "AU" 19 "AT" 18 "AS" 17 "AR" 16 "AQ" 15 "AP" 14 "AO" 13 "AN" 12 "AM" 11 "AL" 10 "AK" 9 "AJ" 8 "AI" 7 "AH" 6 "AG" 5 "AF" 4 "AE" 3 "AD" 2 "AC" 1 "AB" 0 "AA" ;
VAL_ 2499743078 HVESP01_SerNum_Location_2 2 "Springboro" 1 "Lake Orion Tech Center" 0 "Unknown" ;
VAL_ 2499743078 HVESP01_SerNum_PartNo_SubVe_0000 825 "ZZ" 824 "ZY" 823 "ZX" 822 "ZW" 821 "ZV" 820 "ZU" 819 "ZT" 818 "ZS" 817 "ZR" 816 "ZQ" 815 "ZP" 814 "ZO" 813 "ZN" 812 "ZM" 811 "ZL" 810 "ZK" 809 "ZJ" 808 "ZI" 807 "ZH" 806 "ZG" 805 "ZF" 804 "ZE" 803 "ZD" 802 "ZC" 801 "ZB" 800 "ZA" 793 "YZ" 792 "YY" 791 "YX" 790 "YW" 789 "YV" 788 "YU" 787 "YT" 786 "YS" 785 "YR" 784 "YQ" 783 "YP" 782 "YO" 781 "YN" 780 "YM" 779 "YL" 778 "YK" 777 "YJ" 776 "YI" 775 "YH" 774 "YG" 773 "YF" 772 "YE" 771 "YD" 770 "YC" 769 "YB" 768 "YA" 761 "XZ" 760 "XY" 759 "XX" 758 "XW" 757 "XV" 756 "XU" 755 "XT" 754 "XS" 753 "XR" 752 "XQ" 751 "XP" 750 "XO" 749 "XN" 748 "XM" 747 "XL" 746 "XK" 745 "XJ" 744 "XI" 743 "XH" 742 "XG" 741 "XF" 740 "XE" 739 "XD" 738 "XC" 737 "XB" 736 "XA" 729 "WZ" 728 "WY" 727 "WX" 726 "WW" 725 "WV" 724 "WU" 723 "WT" 722 "WS" 721 "WR" 720 "WQ" 719 "WP" 718 "WO" 717 "WN" 716 "WM" 715 "WL" 714 "WK" 713 "WJ" 712 "WI" 711 "WH" 710 "WG" 709 "WF" 708 "WE" 707 "WD" 706 "WC" 705 "WB" 704 "WA" 697 "VZ" 696 "VY" 695 "VX" 694 "VW" 693 "VV" 692 "VU" 691 "VT" 690 "VS" 689 "VR" 688 "VQ" 687 "VP" 686 "VO" 685 "VN" 684 "VM" 683 "VL" 682 "VK" 681 "VJ" 680 "VI" 679 "VH" 678 "VG" 677 "VF" 676 "VE" 675 "VD" 674 "VC" 673 "VB" 672 "VA" 665 "UZ" 664 "UY" 663 "UX" 662 "UW" 661 "UV" 660 "UU" 659 "UT" 658 "US" 657 "UR" 656 "UQ" 655 "UP" 654 "UO" 653 "UN" 652 "UM" 651 "UL" 650 "UK" 649 "UJ" 648 "UI" 647 "UH" 646 "UG" 645 "UF" 644 "UE" 643 "UD" 642 "UC" 641 "UB" 640 "UA" 633 "TZ" 632 "TY" 631 "TX" 630 "TW" 629 "TV" 628 "TU" 627 "TT" 626 "TS" 625 "TR" 624 "TQ" 623 "TP" 622 "TO" 621 "TN" 620 "TM" 619 "TL" 618 "TK" 617 "TJ" 616 "TI" 615 "TH" 614 "TG" 613 "TF" 612 "TE" 611 "TD" 610 "TC" 609 "TB" 608 "TA" 601 "SZ" 600 "SY" 599 "SX" 598 "SW" 597 "SV" 596 "SU" 595 "ST" 594 "SS" 593 "SR" 592 "SQ" 591 "SP" 590 "SO" 589 "SN" 588 "SM" 587 "SL" 586 "SK" 585 "SJ" 584 "SI" 583 "SH" 582 "SG" 581 "SF" 580 "SE" 579 "SD" 578 "SC" 577 "SB" 576 "SA" 569 "RZ" 568 "RY" 567 "RX" 566 "RW" 565 "RV" 564 "RU" 563 "RT" 562 "RS" 561 "RR" 560 "RQ" 559 "RP" 558 "RO" 557 "RN" 556 "RM" 555 "RL" 554 "RK" 553 "RJ" 552 "RI" 551 "RH" 550 "RG" 549 "RF" 548 "RE" 547 "RD" 546 "RC" 545 "RB" 544 "RA" 537 "QZ" 536 "QY" 535 "QX" 534 "QW" 533 "QV" 532 "QU" 531 "QT" 530 "QS" 529 "QR" 528 "QQ" 527 "QP" 526 "QO" 525 "QN" 524 "QM" 523 "QL" 522 "QK" 521 "QJ" 520 "QI" 519 "QH" 518 "QG" 517 "QF" 516 "QE" 515 "QD" 514 "QC" 513 "QB" 512 "QA" 505 "PZ" 504 "PY" 503 "PX" 502 "PW" 501 "PV" 500 "PU" 499 "PT" 498 "PS" 497 "PR" 496 "PQ" 495 "PP" 494 "PO" 493 "PN" 492 "PM" 491 "PL" 490 "PK" 489 "PJ" 488 "PI" 487 "PH" 486 "PG" 485 "PF" 484 "PE" 483 "PD" 482 "PC" 481 "PB" 480 "PA" 473 "OZ" 472 "OY" 471 "OX" 470 "OW" 469 "OV" 468 "OU" 467 "OT" 466 "OS" 465 "OR" 464 "OQ" 463 "OP" 462 "OO" 461 "ON" 460 "OM" 459 "OL" 458 "OK" 457 "OJ" 456 "OI" 455 "OH" 454 "OG" 453 "OF" 452 "OE" 451 "OD" 450 "OC" 449 "OB" 448 "OA" 441 "NZ" 440 "NY" 439 "NX" 438 "NW" 437 "NV" 436 "NU" 435 "NT" 434 "NS" 433 "NR" 432 "NQ" 431 "NP" 430 "NO" 429 "NN" 428 "NM" 427 "NL" 426 "NK" 425 "NJ" 424 "NI" 423 "NH" 422 "NG" 421 "NF" 420 "NE" 419 "ND" 418 "NC" 417 "NB" 416 "NA" 409 "MZ" 408 "MY" 407 "MX" 406 "MW" 405 "MV" 404 "MU" 403 "MT" 402 "MS" 401 "MR" 400 "MQ" 399 "MP" 398 "MO" 397 "MN" 396 "MM" 395 "ML" 394 "MK" 393 "MJ" 392 "MI" 391 "MH" 390 "MG" 389 "MF" 388 "ME" 387 "MD" 386 "MC" 385 "MB" 384 "MA" 377 "LZ" 376 "LY" 375 "LX" 374 "LW" 373 "LV" 372 "LU" 371 "LT" 370 "LS" 369 "LR" 368 "LQ" 367 "LP" 366 "LO" 365 "LN" 364 "LM" 363 "LL" 362 "LK" 361 "LJ" 360 "LI" 359 "LH" 358 "LG" 357 "LF" 356 "LE" 355 "LD" 354 "LC" 353 "LB" 352 "LA" 345 "KZ" 344 "KY" 343 "KX" 342 "KW" 341 "KV" 340 "KU" 339 "KT" 338 "KS" 337 "KR" 336 "KQ" 335 "KP" 334 "KO" 333 "KN" 332 "KM" 331 "KL" 330 "KK" 329 "KJ" 328 "KI" 327 "KH" 326 "KG" 325 "KF" 324 "KE" 323 "KD" 322 "KC" 321 "KB" 320 "KA" 313 "JZ" 312 "JY" 311 "JX" 310 "JW" 309 "JV" 308 "JU" 307 "JT" 306 "JS" 305 "JR" 304 "JQ" 303 "JP" 302 "JO" 301 "JN" 300 "JM" 299 "JL" 298 "JK" 297 "JJ" 296 "JI" 295 "JH" 294 "JG" 293 "JF" 292 "JE" 291 "JD" 290 "JC" 289 "JB" 288 "JA" 281 "IZ" 280 "IY" 279 "IX" 278 "IW" 277 "IV" 276 "IU" 275 "IT" 274 "IS" 273 "IR" 272 "IQ" 271 "IP" 270 "IO" 269 "IN" 268 "IM" 267 "IL" 266 "IK" 265 "IJ" 264 "II" 263 "IH" 262 "IG" 261 "IF" 260 "IE" 259 "ID" 258 "IC" 257 "IB" 256 "IA" 249 "HZ" 248 "HY" 247 "HX" 246 "HW" 245 "HV" 244 "HU" 243 "HT" 242 "HS" 241 "HR" 240 "HQ" 239 "HP" 238 "HO" 237 "HN" 236 "HM" 235 "HL" 234 "HK" 233 "HJ" 232 "HI" 231 "HH" 230 "HG" 229 "HF" 228 "HE" 227 "HD" 226 "HC" 225 "HB" 224 "HA" 217 "GZ" 216 "GY" 215 "GX" 214 "GW" 213 "GV" 212 "GU" 211 "GT" 210 "GS" 209 "GR" 208 "GQ" 207 "GP" 206 "GO" 205 "GN" 204 "GM" 203 "GL" 202 "GK" 201 "GJ" 200 "GI" 199 "GH" 198 "GG" 197 "GF" 196 "GE" 195 "GD" 194 "GC" 193 "GB" 192 "GA" 185 "FZ" 184 "FY" 183 "FX" 182 "FW" 181 "FV" 180 "FU" 179 "FT" 178 "FS" 177 "FR" 176 "FQ" 175 "FP" 174 "FO" 173 "FN" 172 "FM" 171 "FL" 170 "FK" 169 "FJ" 168 "FI" 167 "FH" 166 "FG" 165 "FF" 164 "FE" 163 "FD" 162 "FC" 161 "FB" 160 "FA" 153 "EZ" 152 "EY" 151 "EX" 150 "EW" 149 "EV" 148 "EU" 147 "ET" 146 "ES" 145 "ER" 144 "EQ" 143 "EP" 142 "EO" 141 "EN" 140 "EM" 139 "EL" 138 "EK" 137 "EJ" 136 "EI" 135 "EH" 134 "EG" 133 "EF" 132 "EE" 131 "ED" 130 "EC" 129 "EB" 128 "EA" 121 "DZ" 120 "DY" 119 "DX" 118 "DW" 117 "DV" 116 "DU" 115 "DT" 114 "DS" 113 "DR" 112 "DQ" 111 "DP" 110 "DO" 109 "DN" 108 "DM" 107 "DL" 106 "DK" 105 "DJ" 104 "DI" 103 "DH" 102 "DG" 101 "DF" 100 "DE" 99 "DD" 98 "DC" 97 "DB" 96 "DA" 89 "CZ" 88 "CY" 87 "CX" 86 "CW" 85 "CV" 84 "CU" 83 "CT" 82 "CS" 81 "CR" 80 "CQ" 79 "CP" 78 "CO" 77 "CN" 76 "CM" 75 "CL" 74 "CK" 73 "CJ" 72 "CI" 71 "CH" 70 "CG" 69 "CF" 68 "CE" 67 "CD" 66 "CC" 65 "CB" 64 "CA" 57 "BZ" 56 "BY" 55 "BX" 54 "BW" 53 "BV" 52 "BU" 51 "BT" 50 "BS" 49 "BR" 48 "BQ" 47 "BP" 46 "BO" 45 "BN" 44 "BM" 43 "BL" 42 "BK" 41 "BJ" 40 "BI" 39 "BH" 38 "BG" 37 "BF" 36 "BE" 35 "BD" 34 "BC" 33 "BB" 32 "BA" 25 "AZ" 24 "AY" 23 "AX" 22 "AW" 21 "AV" 20 "AU" 19 "AT" 18 "AS" 17 "AR" 16 "AQ" 15 "AP" 14 "AO" 13 "AN" 12 "AM" 11 "AL" 10 "AK" 9 "AJ" 8 "AI" 7 "AH" 6 "AG" 5 "AF" 4 "AE" 3 "AD" 2 "AC" 1 "AB" 0 "AA" ;
VAL_ 2499743079 HVESP01_SerNum_Location_3 2 "Springboro" 1 "Lake Orion Tech Center" 0 "Unknown" ;
VAL_ 2499743079 HVESP01_SerNum_PartNo_SubVe_0001 825 "ZZ" 824 "ZY" 823 "ZX" 822 "ZW" 821 "ZV" 820 "ZU" 819 "ZT" 818 "ZS" 817 "ZR" 816 "ZQ" 815 "ZP" 814 "ZO" 813 "ZN" 812 "ZM" 811 "ZL" 810 "ZK" 809 "ZJ" 808 "ZI" 807 "ZH" 806 "ZG" 805 "ZF" 804 "ZE" 803 "ZD" 802 "ZC" 801 "ZB" 800 "ZA" 793 "YZ" 792 "YY" 791 "YX" 790 "YW" 789 "YV" 788 "YU" 787 "YT" 786 "YS" 785 "YR" 784 "YQ" 783 "YP" 782 "YO" 781 "YN" 780 "YM" 779 "YL" 778 "YK" 777 "YJ" 776 "YI" 775 "YH" 774 "YG" 773 "YF" 772 "YE" 771 "YD" 770 "YC" 769 "YB" 768 "YA" 761 "XZ" 760 "XY" 759 "XX" 758 "XW" 757 "XV" 756 "XU" 755 "XT" 754 "XS" 753 "XR" 752 "XQ" 751 "XP" 750 "XO" 749 "XN" 748 "XM" 747 "XL" 746 "XK" 745 "XJ" 744 "XI" 743 "XH" 742 "XG" 741 "XF" 740 "XE" 739 "XD" 738 "XC" 737 "XB" 736 "XA" 729 "WZ" 728 "WY" 727 "WX" 726 "WW" 725 "WV" 724 "WU" 723 "WT" 722 "WS" 721 "WR" 720 "WQ" 719 "WP" 718 "WO" 717 "WN" 716 "WM" 715 "WL" 714 "WK" 713 "WJ" 712 "WI" 711 "WH" 710 "WG" 709 "WF" 708 "WE" 707 "WD" 706 "WC" 705 "WB" 704 "WA" 697 "VZ" 696 "VY" 695 "VX" 694 "VW" 693 "VV" 692 "VU" 691 "VT" 690 "VS" 689 "VR" 688 "VQ" 687 "VP" 686 "VO" 685 "VN" 684 "VM" 683 "VL" 682 "VK" 681 "VJ" 680 "VI" 679 "VH" 678 "VG" 677 "VF" 676 "VE" 675 "VD" 674 "VC" 673 "VB" 672 "VA" 665 "UZ" 664 "UY" 663 "UX" 662 "UW" 661 "UV" 660 "UU" 659 "UT" 658 "US" 657 "UR" 656 "UQ" 655 "UP" 654 "UO" 653 "UN" 652 "UM" 651 "UL" 650 "UK" 649 "UJ" 648 "UI" 647 "UH" 646 "UG" 645 "UF" 644 "UE" 643 "UD" 642 "UC" 641 "UB" 640 "UA" 633 "TZ" 632 "TY" 631 "TX" 630 "TW" 629 "TV" 628 "TU" 627 "TT" 626 "TS" 625 "TR" 624 "TQ" 623 "TP" 622 "TO" 621 "TN" 620 "TM" 619 "TL" 618 "TK" 617 "TJ" 616 "TI" 615 "TH" 614 "TG" 613 "TF" 612 "TE" 611 "TD" 610 "TC" 609 "TB" 608 "TA" 601 "SZ" 600 "SY" 599 "SX" 598 "SW" 597 "SV" 596 "SU" 595 "ST" 594 "SS" 593 "SR" 592 "SQ" 591 "SP" 590 "SO" 589 "SN" 588 "SM" 587 "SL" 586 "SK" 585 "SJ" 584 "SI" 583 "SH" 582 "SG" 581 "SF" 580 "SE" 579 "SD" 578 "SC" 577 "SB" 576 "SA" 569 "RZ" 568 "RY" 567 "RX" 566 "RW" 565 "RV" 564 "RU" 563 "RT" 562 "RS" 561 "RR" 560 "RQ" 559 "RP" 558 "RO" 557 "RN" 556 "RM" 555 "RL" 554 "RK" 553 "RJ" 552 "RI" 551 "RH" 550 "RG" 549 "RF" 548 "RE" 547 "RD" 546 "RC" 545 "RB" 544 "RA" 537 "QZ" 536 "QY" 535 "QX" 534 "QW" 533 "QV" 532 "QU" 531 "QT" 530 "QS" 529 "QR" 528 "QQ" 527 "QP" 526 "QO" 525 "QN" 524 "QM" 523 "QL" 522 "QK" 521 "QJ" 520 "QI" 519 "QH" 518 "QG" 517 "QF" 516 "QE" 515 "QD" 514 "QC" 513 "QB" 512 "QA" 505 "PZ" 504 "PY" 503 "PX" 502 "PW" 501 "PV" 500 "PU" 499 "PT" 498 "PS" 497 "PR" 496 "PQ" 495 "PP" 494 "PO" 493 "PN" 492 "PM" 491 "PL" 490 "PK" 489 "PJ" 488 "PI" 487 "PH" 486 "PG" 485 "PF" 484 "PE" 483 "PD" 482 "PC" 481 "PB" 480 "PA" 473 "OZ" 472 "OY" 471 "OX" 470 "OW" 469 "OV" 468 "OU" 467 "OT" 466 "OS" 465 "OR" 464 "OQ" 463 "OP" 462 "OO" 461 "ON" 460 "OM" 459 "OL" 458 "OK" 457 "OJ" 456 "OI" 455 "OH" 454 "OG" 453 "OF" 452 "OE" 451 "OD" 450 "OC" 449 "OB" 448 "OA" 441 "NZ" 440 "NY" 439 "NX" 438 "NW" 437 "NV" 436 "NU" 435 "NT" 434 "NS" 433 "NR" 432 "NQ" 431 "NP" 430 "NO" 429 "NN" 428 "NM" 427 "NL" 426 "NK" 425 "NJ" 424 "NI" 423 "NH" 422 "NG" 421 "NF" 420 "NE" 419 "ND" 418 "NC" 417 "NB" 416 "NA" 409 "MZ" 408 "MY" 407 "MX" 406 "MW" 405 "MV" 404 "MU" 403 "MT" 402 "MS" 401 "MR" 400 "MQ" 399 "MP" 398 "MO" 397 "MN" 396 "MM" 395 "ML" 394 "MK" 393 "MJ" 392 "MI" 391 "MH" 390 "MG" 389 "MF" 388 "ME" 387 "MD" 386 "MC" 385 "MB" 384 "MA" 377 "LZ" 376 "LY" 375 "LX" 374 "LW" 373 "LV" 372 "LU" 371 "LT" 370 "LS" 369 "LR" 368 "LQ" 367 "LP" 366 "LO" 365 "LN" 364 "LM" 363 "LL" 362 "LK" 361 "LJ" 360 "LI" 359 "LH" 358 "LG" 357 "LF" 356 "LE" 355 "LD" 354 "LC" 353 "LB" 352 "LA" 345 "KZ" 344 "KY" 343 "KX" 342 "KW" 341 "KV" 340 "KU" 339 "KT" 338 "KS" 337 "KR" 336 "KQ" 335 "KP" 334 "KO" 333 "KN" 332 "KM" 331 "KL" 330 "KK" 329 "KJ" 328 "KI" 327 "KH" 326 "KG" 325 "KF" 324 "KE" 323 "KD" 322 "KC" 321 "KB" 320 "KA" 313 "JZ" 312 "JY" 311 "JX" 310 "JW" 309 "JV" 308 "JU" 307 "JT" 306 "JS" 305 "JR" 304 "JQ" 303 "JP" 302 "JO" 301 "JN" 300 "JM" 299 "JL" 298 "JK" 297 "JJ" 296 "JI" 295 "JH" 294 "JG" 293 "JF" 292 "JE" 291 "JD" 290 "JC" 289 "JB" 288 "JA" 281 "IZ" 280 "IY" 279 "IX" 278 "IW" 277 "IV" 276 "IU" 275 "IT" 274 "IS" 273 "IR" 272 "IQ" 271 "IP" 270 "IO" 269 "IN" 268 "IM" 267 "IL" 266 "IK" 265 "IJ" 264 "II" 263 "IH" 262 "IG" 261 "IF" 260 "IE" 259 "ID" 258 "IC" 257 "IB" 256 "IA" 249 "HZ" 248 "HY" 247 "HX" 246 "HW" 245 "HV" 244 "HU" 243 "HT" 242 "HS" 241 "HR" 240 "HQ" 239 "HP" 238 "HO" 237 "HN" 236 "HM" 235 "HL" 234 "HK" 233 "HJ" 232 "HI" 231 "HH" 230 "HG" 229 "HF" 228 "HE" 227 "HD" 226 "HC" 225 "HB" 224 "HA" 217 "GZ" 216 "GY" 215 "GX" 214 "GW" 213 "GV" 212 "GU" 211 "GT" 210 "GS" 209 "GR" 208 "GQ" 207 "GP" 206 "GO" 205 "GN" 204 "GM" 203 "GL" 202 "GK" 201 "GJ" 200 "GI" 199 "GH" 198 "GG" 197 "GF" 196 "GE" 195 "GD" 194 "GC" 193 "GB" 192 "GA" 185 "FZ" 184 "FY" 183 "FX" 182 "FW" 181 "FV" 180 "FU" 179 "FT" 178 "FS" 177 "FR" 176 "FQ" 175 "FP" 174 "FO" 173 "FN" 172 "FM" 171 "FL" 170 "FK" 169 "FJ" 168 "FI" 167 "FH" 166 "FG" 165 "FF" 164 "FE" 163 "FD" 162 "FC" 161 "FB" 160 "FA" 153 "EZ" 152 "EY" 151 "EX" 150 "EW" 149 "EV" 148 "EU" 147 "ET" 146 "ES" 145 "ER" 144 "EQ" 143 "EP" 142 "EO" 141 "EN" 140 "EM" 139 "EL" 138 "EK" 137 "EJ" 136 "EI" 135 "EH" 134 "EG" 133 "EF" 132 "EE" 131 "ED" 130 "EC" 129 "EB" 128 "EA" 121 "DZ" 120 "DY" 119 "DX" 118 "DW" 117 "DV" 116 "DU" 115 "DT" 114 "DS" 113 "DR" 112 "DQ" 111 "DP" 110 "DO" 109 "DN" 108 "DM" 107 "DL" 106 "DK" 105 "DJ" 104 "DI" 103 "DH" 102 "DG" 101 "DF" 100 "DE" 99 "DD" 98 "DC" 97 "DB" 96 "DA" 89 "CZ" 88 "CY" 87 "CX" 86 "CW" 85 "CV" 84 "CU" 83 "CT" 82 "CS" 81 "CR" 80 "CQ" 79 "CP" 78 "CO" 77 "CN" 76 "CM" 75 "CL" 74 "CK" 73 "CJ" 72 "CI" 71 "CH" 70 "CG" 69 "CF" 68 "CE" 67 "CD" 66 "CC" 65 "CB" 64 "CA" 57 "BZ" 56 "BY" 55 "BX" 54 "BW" 53 "BV" 52 "BU" 51 "BT" 50 "BS" 49 "BR" 48 "BQ" 47 "BP" 46 "BO" 45 "BN" 44 "BM" 43 "BL" 42 "BK" 41 "BJ" 40 "BI" 39 "BH" 38 "BG" 37 "BF" 36 "BE" 35 "BD" 34 "BC" 33 "BB" 32 "BA" 25 "AZ" 24 "AY" 23 "AX" 22 "AW" 21 "AV" 20 "AU" 19 "AT" 18 "AS" 17 "AR" 16 "AQ" 15 "AP" 14 "AO" 13 "AN" 12 "AM" 11 "AL" 10 "AK" 9 "AJ" 8 "AI" 7 "AH" 6 "AG" 5 "AF" 4 "AE" 3 "AD" 2 "AC" 1 "AB" 0 "AA" ;
VAL_ 2499743080 HVESP01_SerNum_Location_4 2 "Springboro" 1 "Lake Orion Tech Center" 0 "Unknown" ;
VAL_ 2499743080 HVESP01_SerNum_PartNo_SubVe_0002 825 "ZZ" 824 "ZY" 823 "ZX" 822 "ZW" 821 "ZV" 820 "ZU" 819 "ZT" 818 "ZS" 817 "ZR" 816 "ZQ" 815 "ZP" 814 "ZO" 813 "ZN" 812 "ZM" 811 "ZL" 810 "ZK" 809 "ZJ" 808 "ZI" 807 "ZH" 806 "ZG" 805 "ZF" 804 "ZE" 803 "ZD" 802 "ZC" 801 "ZB" 800 "ZA" 793 "YZ" 792 "YY" 791 "YX" 790 "YW" 789 "YV" 788 "YU" 787 "YT" 786 "YS" 785 "YR" 784 "YQ" 783 "YP" 782 "YO" 781 "YN" 780 "YM" 779 "YL" 778 "YK" 777 "YJ" 776 "YI" 775 "YH" 774 "YG" 773 "YF" 772 "YE" 771 "YD" 770 "YC" 769 "YB" 768 "YA" 761 "XZ" 760 "XY" 759 "XX" 758 "XW" 757 "XV" 756 "XU" 755 "XT" 754 "XS" 753 "XR" 752 "XQ" 751 "XP" 750 "XO" 749 "XN" 748 "XM" 747 "XL" 746 "XK" 745 "XJ" 744 "XI" 743 "XH" 742 "XG" 741 "XF" 740 "XE" 739 "XD" 738 "XC" 737 "XB" 736 "XA" 729 "WZ" 728 "WY" 727 "WX" 726 "WW" 725 "WV" 724 "WU" 723 "WT" 722 "WS" 721 "WR" 720 "WQ" 719 "WP" 718 "WO" 717 "WN" 716 "WM" 715 "WL" 714 "WK" 713 "WJ" 712 "WI" 711 "WH" 710 "WG" 709 "WF" 708 "WE" 707 "WD" 706 "WC" 705 "WB" 704 "WA" 697 "VZ" 696 "VY" 695 "VX" 694 "VW" 693 "VV" 692 "VU" 691 "VT" 690 "VS" 689 "VR" 688 "VQ" 687 "VP" 686 "VO" 685 "VN" 684 "VM" 683 "VL" 682 "VK" 681 "VJ" 680 "VI" 679 "VH" 678 "VG" 677 "VF" 676 "VE" 675 "VD" 674 "VC" 673 "VB" 672 "VA" 665 "UZ" 664 "UY" 663 "UX" 662 "UW" 661 "UV" 660 "UU" 659 "UT" 658 "US" 657 "UR" 656 "UQ" 655 "UP" 654 "UO" 653 "UN" 652 "UM" 651 "UL" 650 "UK" 649 "UJ" 648 "UI" 647 "UH" 646 "UG" 645 "UF" 644 "UE" 643 "UD" 642 "UC" 641 "UB" 640 "UA" 633 "TZ" 632 "TY" 631 "TX" 630 "TW" 629 "TV" 628 "TU" 627 "TT" 626 "TS" 625 "TR" 624 "TQ" 623 "TP" 622 "TO" 621 "TN" 620 "TM" 619 "TL" 618 "TK" 617 "TJ" 616 "TI" 615 "TH" 614 "TG" 613 "TF" 612 "TE" 611 "TD" 610 "TC" 609 "TB" 608 "TA" 601 "SZ" 600 "SY" 599 "SX" 598 "SW" 597 "SV" 596 "SU" 595 "ST" 594 "SS" 593 "SR" 592 "SQ" 591 "SP" 590 "SO" 589 "SN" 588 "SM" 587 "SL" 586 "SK" 585 "SJ" 584 "SI" 583 "SH" 582 "SG" 581 "SF" 580 "SE" 579 "SD" 578 "SC" 577 "SB" 576 "SA" 569 "RZ" 568 "RY" 567 "RX" 566 "RW" 565 "RV" 564 "RU" 563 "RT" 562 "RS" 561 "RR" 560 "RQ" 559 "RP" 558 "RO" 557 "RN" 556 "RM" 555 "RL" 554 "RK" 553 "RJ" 552 "RI" 551 "RH" 550 "RG" 549 "RF" 548 "RE" 547 "RD" 546 "RC" 545 "RB" 544 "RA" 537 "QZ" 536 "QY" 535 "QX" 534 "QW" 533 "QV" 532 "QU" 531 "QT" 530 "QS" 529 "QR" 528 "QQ" 527 "QP" 526 "QO" 525 "QN" 524 "QM" 523 "QL" 522 "QK" 521 "QJ" 520 "QI" 519 "QH" 518 "QG" 517 "QF" 516 "QE" 515 "QD" 514 "QC" 513 "QB" 512 "QA" 505 "PZ" 504 "PY" 503 "PX" 502 "PW" 501 "PV" 500 "PU" 499 "PT" 498 "PS" 497 "PR" 496 "PQ" 495 "PP" 494 "PO" 493 "PN" 492 "PM" 491 "PL" 490 "PK" 489 "PJ" 488 "PI" 487 "PH" 486 "PG" 485 "PF" 484 "PE" 483 "PD" 482 "PC" 481 "PB" 480 "PA" 473 "OZ" 472 "OY" 471 "OX" 470 "OW" 469 "OV" 468 "OU" 467 "OT" 466 "OS" 465 "OR" 464 "OQ" 463 "OP" 462 "OO" 461 "ON" 460 "OM" 459 "OL" 458 "OK" 457 "OJ" 456 "OI" 455 "OH" 454 "OG" 453 "OF" 452 "OE" 451 "OD" 450 "OC" 449 "OB" 448 "OA" 441 "NZ" 440 "NY" 439 "NX" 438 "NW" 437 "NV" 436 "NU" 435 "NT" 434 "NS" 433 "NR" 432 "NQ" 431 "NP" 430 "NO" 429 "NN" 428 "NM" 427 "NL" 426 "NK" 425 "NJ" 424 "NI" 423 "NH" 422 "NG" 421 "NF" 420 "NE" 419 "ND" 418 "NC" 417 "NB" 416 "NA" 409 "MZ" 408 "MY" 407 "MX" 406 "MW" 405 "MV" 404 "MU" 403 "MT" 402 "MS" 401 "MR" 400 "MQ" 399 "MP" 398 "MO" 397 "MN" 396 "MM" 395 "ML" 394 "MK" 393 "MJ" 392 "MI" 391 "MH" 390 "MG" 389 "MF" 388 "ME" 387 "MD" 386 "MC" 385 "MB" 384 "MA" 377 "LZ" 376 "LY" 375 "LX" 374 "LW" 373 "LV" 372 "LU" 371 "LT" 370 "LS" 369 "LR" 368 "LQ" 367 "LP" 366 "LO" 365 "LN" 364 "LM" 363 "LL" 362 "LK" 361 "LJ" 360 "LI" 359 "LH" 358 "LG" 357 "LF" 356 "LE" 355 "LD" 354 "LC" 353 "LB" 352 "LA" 345 "KZ" 344 "KY" 343 "KX" 342 "KW" 341 "KV" 340 "KU" 339 "KT" 338 "KS" 337 "KR" 336 "KQ" 335 "KP" 334 "KO" 333 "KN" 332 "KM" 331 "KL" 330 "KK" 329 "KJ" 328 "KI" 327 "KH" 326 "KG" 325 "KF" 324 "KE" 323 "KD" 322 "KC" 321 "KB" 320 "KA" 313 "JZ" 312 "JY" 311 "JX" 310 "JW" 309 "JV" 308 "JU" 307 "JT" 306 "JS" 305 "JR" 304 "JQ" 303 "JP" 302 "JO" 301 "JN" 300 "JM" 299 "JL" 298 "JK" 297 "JJ" 296 "JI" 295 "JH" 294 "JG" 293 "JF" 292 "JE" 291 "JD" 290 "JC" 289 "JB" 288 "JA" 281 "IZ" 280 "IY" 279 "IX" 278 "IW" 277 "IV" 276 "IU" 275 "IT" 274 "IS" 273 "IR" 272 "IQ" 271 "IP" 270 "IO" 269 "IN" 268 "IM" 267 "IL" 266 "IK" 265 "IJ" 264 "II" 263 "IH" 262 "IG" 261 "IF" 260 "IE" 259 "ID" 258 "IC" 257 "IB" 256 "IA" 249 "HZ" 248 "HY" 247 "HX" 246 "HW" 245 "HV" 244 "HU" 243 "HT" 242 "HS" 241 "HR" 240 "HQ" 239 "HP" 238 "HO" 237 "HN" 236 "HM" 235 "HL" 234 "HK" 233 "HJ" 232 "HI" 231 "HH" 230 "HG" 229 "HF" 228 "HE" 227 "HD" 226 "HC" 225 "HB" 224 "HA" 217 "GZ" 216 "GY" 215 "GX" 214 "GW" 213 "GV" 212 "GU" 211 "GT" 210 "GS" 209 "GR" 208 "GQ" 207 "GP" 206 "GO" 205 "GN" 204 "GM" 203 "GL" 202 "GK" 201 "GJ" 200 "GI" 199 "GH" 198 "GG" 197 "GF" 196 "GE" 195 "GD" 194 "GC" 193 "GB" 192 "GA" 185 "FZ" 184 "FY" 183 "FX" 182 "FW" 181 "FV" 180 "FU" 179 "FT" 178 "FS" 177 "FR" 176 "FQ" 175 "FP" 174 "FO" 173 "FN" 172 "FM" 171 "FL" 170 "FK" 169 "FJ" 168 "FI" 167 "FH" 166 "FG" 165 "FF" 164 "FE" 163 "FD" 162 "FC" 161 "FB" 160 "FA" 153 "EZ" 152 "EY" 151 "EX" 150 "EW" 149 "EV" 148 "EU" 147 "ET" 146 "ES" 145 "ER" 144 "EQ" 143 "EP" 142 "EO" 141 "EN" 140 "EM" 139 "EL" 138 "EK" 137 "EJ" 136 "EI" 135 "EH" 134 "EG" 133 "EF" 132 "EE" 131 "ED" 130 "EC" 129 "EB" 128 "EA" 121 "DZ" 120 "DY" 119 "DX" 118 "DW" 117 "DV" 116 "DU" 115 "DT" 114 "DS" 113 "DR" 112 "DQ" 111 "DP" 110 "DO" 109 "DN" 108 "DM" 107 "DL" 106 "DK" 105 "DJ" 104 "DI" 103 "DH" 102 "DG" 101 "DF" 100 "DE" 99 "DD" 98 "DC" 97 "DB" 96 "DA" 89 "CZ" 88 "CY" 87 "CX" 86 "CW" 85 "CV" 84 "CU" 83 "CT" 82 "CS" 81 "CR" 80 "CQ" 79 "CP" 78 "CO" 77 "CN" 76 "CM" 75 "CL" 74 "CK" 73 "CJ" 72 "CI" 71 "CH" 70 "CG" 69 "CF" 68 "CE" 67 "CD" 66 "CC" 65 "CB" 64 "CA" 57 "BZ" 56 "BY" 55 "BX" 54 "BW" 53 "BV" 52 "BU" 51 "BT" 50 "BS" 49 "BR" 48 "BQ" 47 "BP" 46 "BO" 45 "BN" 44 "BM" 43 "BL" 42 "BK" 41 "BJ" 40 "BI" 39 "BH" 38 "BG" 37 "BF" 36 "BE" 35 "BD" 34 "BC" 33 "BB" 32 "BA" 25 "AZ" 24 "AY" 23 "AX" 22 "AW" 21 "AV" 20 "AU" 19 "AT" 18 "AS" 17 "AR" 16 "AQ" 15 "AP" 14 "AO" 13 "AN" 12 "AM" 11 "AL" 10 "AK" 9 "AJ" 8 "AI" 7 "AH" 6 "AG" 5 "AF" 4 "AE" 3 "AD" 2 "AC" 1 "AB" 0 "AA" ;
VAL_ 2499743081 HVESP01_SerNum_Location_5 2 "Springboro" 1 "Lake Orion Tech Center" 0 "Unknown" ;
VAL_ 2499743081 HVESP01_SerNum_PartNo_SubVe_0003 825 "ZZ" 824 "ZY" 823 "ZX" 822 "ZW" 821 "ZV" 820 "ZU" 819 "ZT" 818 "ZS" 817 "ZR" 816 "ZQ" 815 "ZP" 814 "ZO" 813 "ZN" 812 "ZM" 811 "ZL" 810 "ZK" 809 "ZJ" 808 "ZI" 807 "ZH" 806 "ZG" 805 "ZF" 804 "ZE" 803 "ZD" 802 "ZC" 801 "ZB" 800 "ZA" 793 "YZ" 792 "YY" 791 "YX" 790 "YW" 789 "YV" 788 "YU" 787 "YT" 786 "YS" 785 "YR" 784 "YQ" 783 "YP" 782 "YO" 781 "YN" 780 "YM" 779 "YL" 778 "YK" 777 "YJ" 776 "YI" 775 "YH" 774 "YG" 773 "YF" 772 "YE" 771 "YD" 770 "YC" 769 "YB" 768 "YA" 761 "XZ" 760 "XY" 759 "XX" 758 "XW" 757 "XV" 756 "XU" 755 "XT" 754 "XS" 753 "XR" 752 "XQ" 751 "XP" 750 "XO" 749 "XN" 748 "XM" 747 "XL" 746 "XK" 745 "XJ" 744 "XI" 743 "XH" 742 "XG" 741 "XF" 740 "XE" 739 "XD" 738 "XC" 737 "XB" 736 "XA" 729 "WZ" 728 "WY" 727 "WX" 726 "WW" 725 "WV" 724 "WU" 723 "WT" 722 "WS" 721 "WR" 720 "WQ" 719 "WP" 718 "WO" 717 "WN" 716 "WM" 715 "WL" 714 "WK" 713 "WJ" 712 "WI" 711 "WH" 710 "WG" 709 "WF" 708 "WE" 707 "WD" 706 "WC" 705 "WB" 704 "WA" 697 "VZ" 696 "VY" 695 "VX" 694 "VW" 693 "VV" 692 "VU" 691 "VT" 690 "VS" 689 "VR" 688 "VQ" 687 "VP" 686 "VO" 685 "VN" 684 "VM" 683 "VL" 682 "VK" 681 "VJ" 680 "VI" 679 "VH" 678 "VG" 677 "VF" 676 "VE" 675 "VD" 674 "VC" 673 "VB" 672 "VA" 665 "UZ" 664 "UY" 663 "UX" 662 "UW" 661 "UV" 660 "UU" 659 "UT" 658 "US" 657 "UR" 656 "UQ" 655 "UP" 654 "UO" 653 "UN" 652 "UM" 651 "UL" 650 "UK" 649 "UJ" 648 "UI" 647 "UH" 646 "UG" 645 "UF" 644 "UE" 643 "UD" 642 "UC" 641 "UB" 640 "UA" 633 "TZ" 632 "TY" 631 "TX" 630 "TW" 629 "TV" 628 "TU" 627 "TT" 626 "TS" 625 "TR" 624 "TQ" 623 "TP" 622 "TO" 621 "TN" 620 "TM" 619 "TL" 618 "TK" 617 "TJ" 616 "TI" 615 "TH" 614 "TG" 613 "TF" 612 "TE" 611 "TD" 610 "TC" 609 "TB" 608 "TA" 601 "SZ" 600 "SY" 599 "SX" 598 "SW" 597 "SV" 596 "SU" 595 "ST" 594 "SS" 593 "SR" 592 "SQ" 591 "SP" 590 "SO" 589 "SN" 588 "SM" 587 "SL" 586 "SK" 585 "SJ" 584 "SI" 583 "SH" 582 "SG" 581 "SF" 580 "SE" 579 "SD" 578 "SC" 577 "SB" 576 "SA" 569 "RZ" 568 "RY" 567 "RX" 566 "RW" 565 "RV" 564 "RU" 563 "RT" 562 "RS" 561 "RR" 560 "RQ" 559 "RP" 558 "RO" 557 "RN" 556 "RM" 555 "RL" 554 "RK" 553 "RJ" 552 "RI" 551 "RH" 550 "RG" 549 "RF" 548 "RE" 547 "RD" 546 "RC" 545 "RB" 544 "RA" 537 "QZ" 536 "QY" 535 "QX" 534 "QW" 533 "QV" 532 "QU" 531 "QT" 530 "QS" 529 "QR" 528 "QQ" 527 "QP" 526 "QO" 525 "QN" 524 "QM" 523 "QL" 522 "QK" 521 "QJ" 520 "QI" 519 "QH" 518 "QG" 517 "QF" 516 "QE" 515 "QD" 514 "QC" 513 "QB" 512 "QA" 505 "PZ" 504 "PY" 503 "PX" 502 "PW" 501 "PV" 500 "PU" 499 "PT" 498 "PS" 497 "PR" 496 "PQ" 495 "PP" 494 "PO" 493 "PN" 492 "PM" 491 "PL" 490 "PK" 489 "PJ" 488 "PI" 487 "PH" 486 "PG" 485 "PF" 484 "PE" 483 "PD" 482 "PC" 481 "PB" 480 "PA" 473 "OZ" 472 "OY" 471 "OX" 470 "OW" 469 "OV" 468 "OU" 467 "OT" 466 "OS" 465 "OR" 464 "OQ" 463 "OP" 462 "OO" 461 "ON" 460 "OM" 459 "OL" 458 "OK" 457 "OJ" 456 "OI" 455 "OH" 454 "OG" 453 "OF" 452 "OE" 451 "OD" 450 "OC" 449 "OB" 448 "OA" 441 "NZ" 440 "NY" 439 "NX" 438 "NW" 437 "NV" 436 "NU" 435 "NT" 434 "NS" 433 "NR" 432 "NQ" 431 "NP" 430 "NO" 429 "NN" 428 "NM" 427 "NL" 426 "NK" 425 "NJ" 424 "NI" 423 "NH" 422 "NG" 421 "NF" 420 "NE" 419 "ND" 418 "NC" 417 "NB" 416 "NA" 409 "MZ" 408 "MY" 407 "MX" 406 "MW" 405 "MV" 404 "MU" 403 "MT" 402 "MS" 401 "MR" 400 "MQ" 399 "MP" 398 "MO" 397 "MN" 396 "MM" 395 "ML" 394 "MK" 393 "MJ" 392 "MI" 391 "MH" 390 "MG" 389 "MF" 388 "ME" 387 "MD" 386 "MC" 385 "MB" 384 "MA" 377 "LZ" 376 "LY" 375 "LX" 374 "LW" 373 "LV" 372 "LU" 371 "LT" 370 "LS" 369 "LR" 368 "LQ" 367 "LP" 366 "LO" 365 "LN" 364 "LM" 363 "LL" 362 "LK" 361 "LJ" 360 "LI" 359 "LH" 358 "LG" 357 "LF" 356 "LE" 355 "LD" 354 "LC" 353 "LB" 352 "LA" 345 "KZ" 344 "KY" 343 "KX" 342 "KW" 341 "KV" 340 "KU" 339 "KT" 338 "KS" 337 "KR" 336 "KQ" 335 "KP" 334 "KO" 333 "KN" 332 "KM" 331 "KL" 330 "KK" 329 "KJ" 328 "KI" 327 "KH" 326 "KG" 325 "KF" 324 "KE" 323 "KD" 322 "KC" 321 "KB" 320 "KA" 313 "JZ" 312 "JY" 311 "JX" 310 "JW" 309 "JV" 308 "JU" 307 "JT" 306 "JS" 305 "JR" 304 "JQ" 303 "JP" 302 "JO" 301 "JN" 300 "JM" 299 "JL" 298 "JK" 297 "JJ" 296 "JI" 295 "JH" 294 "JG" 293 "JF" 292 "JE" 291 "JD" 290 "JC" 289 "JB" 288 "JA" 281 "IZ" 280 "IY" 279 "IX" 278 "IW" 277 "IV" 276 "IU" 275 "IT" 274 "IS" 273 "IR" 272 "IQ" 271 "IP" 270 "IO" 269 "IN" 268 "IM" 267 "IL" 266 "IK" 265 "IJ" 264 "II" 263 "IH" 262 "IG" 261 "IF" 260 "IE" 259 "ID" 258 "IC" 257 "IB" 256 "IA" 249 "HZ" 248 "HY" 247 "HX" 246 "HW" 245 "HV" 244 "HU" 243 "HT" 242 "HS" 241 "HR" 240 "HQ" 239 "HP" 238 "HO" 237 "HN" 236 "HM" 235 "HL" 234 "HK" 233 "HJ" 232 "HI" 231 "HH" 230 "HG" 229 "HF" 228 "HE" 227 "HD" 226 "HC" 225 "HB" 224 "HA" 217 "GZ" 216 "GY" 215 "GX" 214 "GW" 213 "GV" 212 "GU" 211 "GT" 210 "GS" 209 "GR" 208 "GQ" 207 "GP" 206 "GO" 205 "GN" 204 "GM" 203 "GL" 202 "GK" 201 "GJ" 200 "GI" 199 "GH" 198 "GG" 197 "GF" 196 "GE" 195 "GD" 194 "GC" 193 "GB" 192 "GA" 185 "FZ" 184 "FY" 183 "FX" 182 "FW" 181 "FV" 180 "FU" 179 "FT" 178 "FS" 177 "FR" 176 "FQ" 175 "FP" 174 "FO" 173 "FN" 172 "FM" 171 "FL" 170 "FK" 169 "FJ" 168 "FI" 167 "FH" 166 "FG" 165 "FF" 164 "FE" 163 "FD" 162 "FC" 161 "FB" 160 "FA" 153 "EZ" 152 "EY" 151 "EX" 150 "EW" 149 "EV" 148 "EU" 147 "ET" 146 "ES" 145 "ER" 144 "EQ" 143 "EP" 142 "EO" 141 "EN" 140 "EM" 139 "EL" 138 "EK" 137 "EJ" 136 "EI" 135 "EH" 134 "EG" 133 "EF" 132 "EE" 131 "ED" 130 "EC" 129 "EB" 128 "EA" 121 "DZ" 120 "DY" 119 "DX" 118 "DW" 117 "DV" 116 "DU" 115 "DT" 114 "DS" 113 "DR" 112 "DQ" 111 "DP" 110 "DO" 109 "DN" 108 "DM" 107 "DL" 106 "DK" 105 "DJ" 104 "DI" 103 "DH" 102 "DG" 101 "DF" 100 "DE" 99 "DD" 98 "DC" 97 "DB" 96 "DA" 89 "CZ" 88 "CY" 87 "CX" 86 "CW" 85 "CV" 84 "CU" 83 "CT" 82 "CS" 81 "CR" 80 "CQ" 79 "CP" 78 "CO" 77 "CN" 76 "CM" 75 "CL" 74 "CK" 73 "CJ" 72 "CI" 71 "CH" 70 "CG" 69 "CF" 68 "CE" 67 "CD" 66 "CC" 65 "CB" 64 "CA" 57 "BZ" 56 "BY" 55 "BX" 54 "BW" 53 "BV" 52 "BU" 51 "BT" 50 "BS" 49 "BR" 48 "BQ" 47 "BP" 46 "BO" 45 "BN" 44 "BM" 43 "BL" 42 "BK" 41 "BJ" 40 "BI" 39 "BH" 38 "BG" 37 "BF" 36 "BE" 35 "BD" 34 "BC" 33 "BB" 32 "BA" 25 "AZ" 24 "AY" 23 "AX" 22 "AW" 21 "AV" 20 "AU" 19 "AT" 18 "AS" 17 "AR" 16 "AQ" 15 "AP" 14 "AO" 13 "AN" 12 "AM" 11 "AL" 10 "AK" 9 "AJ" 8 "AI" 7 "AH" 6 "AG" 5 "AF" 4 "AE" 3 "AD" 2 "AC" 1 "AB" 0 "AA" ;
VAL_ 2499743082 HVESP01_SerNum_Location_6 2 "Springboro" 1 "Lake Orion Tech Center" 0 "Unknown" ;
VAL_ 2499743082 HVESP01_SerNum_PartNo_SubVe_0004 825 "ZZ" 824 "ZY" 823 "ZX" 822 "ZW" 821 "ZV" 820 "ZU" 819 "ZT" 818 "ZS" 817 "ZR" 816 "ZQ" 815 "ZP" 814 "ZO" 813 "ZN" 812 "ZM" 811 "ZL" 810 "ZK" 809 "ZJ" 808 "ZI" 807 "ZH" 806 "ZG" 805 "ZF" 804 "ZE" 803 "ZD" 802 "ZC" 801 "ZB" 800 "ZA" 793 "YZ" 792 "YY" 791 "YX" 790 "YW" 789 "YV" 788 "YU" 787 "YT" 786 "YS" 785 "YR" 784 "YQ" 783 "YP" 782 "YO" 781 "YN" 780 "YM" 779 "YL" 778 "YK" 777 "YJ" 776 "YI" 775 "YH" 774 "YG" 773 "YF" 772 "YE" 771 "YD" 770 "YC" 769 "YB" 768 "YA" 761 "XZ" 760 "XY" 759 "XX" 758 "XW" 757 "XV" 756 "XU" 755 "XT" 754 "XS" 753 "XR" 752 "XQ" 751 "XP" 750 "XO" 749 "XN" 748 "XM" 747 "XL" 746 "XK" 745 "XJ" 744 "XI" 743 "XH" 742 "XG" 741 "XF" 740 "XE" 739 "XD" 738 "XC" 737 "XB" 736 "XA" 729 "WZ" 728 "WY" 727 "WX" 726 "WW" 725 "WV" 724 "WU" 723 "WT" 722 "WS" 721 "WR" 720 "WQ" 719 "WP" 718 "WO" 717 "WN" 716 "WM" 715 "WL" 714 "WK" 713 "WJ" 712 "WI" 711 "WH" 710 "WG" 709 "WF" 708 "WE" 707 "WD" 706 "WC" 705 "WB" 704 "WA" 697 "VZ" 696 "VY" 695 "VX" 694 "VW" 693 "VV" 692 "VU" 691 "VT" 690 "VS" 689 "VR" 688 "VQ" 687 "VP" 686 "VO" 685 "VN" 684 "VM" 683 "VL" 682 "VK" 681 "VJ" 680 "VI" 679 "VH" 678 "VG" 677 "VF" 676 "VE" 675 "VD" 674 "VC" 673 "VB" 672 "VA" 665 "UZ" 664 "UY" 663 "UX" 662 "UW" 661 "UV" 660 "UU" 659 "UT" 658 "US" 657 "UR" 656 "UQ" 655 "UP" 654 "UO" 653 "UN" 652 "UM" 651 "UL" 650 "UK" 649 "UJ" 648 "UI" 647 "UH" 646 "UG" 645 "UF" 644 "UE" 643 "UD" 642 "UC" 641 "UB" 640 "UA" 633 "TZ" 632 "TY" 631 "TX" 630 "TW" 629 "TV" 628 "TU" 627 "TT" 626 "TS" 625 "TR" 624 "TQ" 623 "TP" 622 "TO" 621 "TN" 620 "TM" 619 "TL" 618 "TK" 617 "TJ" 616 "TI" 615 "TH" 614 "TG" 613 "TF" 612 "TE" 611 "TD" 610 "TC" 609 "TB" 608 "TA" 601 "SZ" 600 "SY" 599 "SX" 598 "SW" 597 "SV" 596 "SU" 595 "ST" 594 "SS" 593 "SR" 592 "SQ" 591 "SP" 590 "SO" 589 "SN" 588 "SM" 587 "SL" 586 "SK" 585 "SJ" 584 "SI" 583 "SH" 582 "SG" 581 "SF" 580 "SE" 579 "SD" 578 "SC" 577 "SB" 576 "SA" 569 "RZ" 568 "RY" 567 "RX" 566 "RW" 565 "RV" 564 "RU" 563 "RT" 562 "RS" 561 "RR" 560 "RQ" 559 "RP" 558 "RO" 557 "RN" 556 "RM" 555 "RL" 554 "RK" 553 "RJ" 552 "RI" 551 "RH" 550 "RG" 549 "RF" 548 "RE" 547 "RD" 546 "RC" 545 "RB" 544 "RA" 537 "QZ" 536 "QY" 535 "QX" 534 "QW" 533 "QV" 532 "QU" 531 "QT" 530 "QS" 529 "QR" 528 "QQ" 527 "QP" 526 "QO" 525 "QN" 524 "QM" 523 "QL" 522 "QK" 521 "QJ" 520 "QI" 519 "QH" 518 "QG" 517 "QF" 516 "QE" 515 "QD" 514 "QC" 513 "QB" 512 "QA" 505 "PZ" 504 "PY" 503 "PX" 502 "PW" 501 "PV" 500 "PU" 499 "PT" 498 "PS" 497 "PR" 496 "PQ" 495 "PP" 494 "PO" 493 "PN" 492 "PM" 491 "PL" 490 "PK" 489 "PJ" 488 "PI" 487 "PH" 486 "PG" 485 "PF" 484 "PE" 483 "PD" 482 "PC" 481 "PB" 480 "PA" 473 "OZ" 472 "OY" 471 "OX" 470 "OW" 469 "OV" 468 "OU" 467 "OT" 466 "OS" 465 "OR" 464 "OQ" 463 "OP" 462 "OO" 461 "ON" 460 "OM" 459 "OL" 458 "OK" 457 "OJ" 456 "OI" 455 "OH" 454 "OG" 453 "OF" 452 "OE" 451 "OD" 450 "OC" 449 "OB" 448 "OA" 441 "NZ" 440 "NY" 439 "NX" 438 "NW" 437 "NV" 436 "NU" 435 "NT" 434 "NS" 433 "NR" 432 "NQ" 431 "NP" 430 "NO" 429 "NN" 428 "NM" 427 "NL" 426 "NK" 425 "NJ" 424 "NI" 423 "NH" 422 "NG" 421 "NF" 420 "NE" 419 "ND" 418 "NC" 417 "NB" 416 "NA" 409 "MZ" 408 "MY" 407 "MX" 406 "MW" 405 "MV" 404 "MU" 403 "MT" 402 "MS" 401 "MR" 400 "MQ" 399 "MP" 398 "MO" 397 "MN" 396 "MM" 395 "ML" 394 "MK" 393 "MJ" 392 "MI" 391 "MH" 390 "MG" 389 "MF" 388 "ME" 387 "MD" 386 "MC" 385 "MB" 384 "MA" 377 "LZ" 376 "LY" 375 "LX" 374 "LW" 373 "LV" 372 "LU" 371 "LT" 370 "LS" 369 "LR" 368 "LQ" 367 "LP" 366 "LO" 365 "LN" 364 "LM" 363 "LL" 362 "LK" 361 "LJ" 360 "LI" 359 "LH" 358 "LG" 357 "LF" 356 "LE" 355 "LD" 354 "LC" 353 "LB" 352 "LA" 345 "KZ" 344 "KY" 343 "KX" 342 "KW" 341 "KV" 340 "KU" 339 "KT" 338 "KS" 337 "KR" 336 "KQ" 335 "KP" 334 "KO" 333 "KN" 332 "KM" 331 "KL" 330 "KK" 329 "KJ" 328 "KI" 327 "KH" 326 "KG" 325 "KF" 324 "KE" 323 "KD" 322 "KC" 321 "KB" 320 "KA" 313 "JZ" 312 "JY" 311 "JX" 310 "JW" 309 "JV" 308 "JU" 307 "JT" 306 "JS" 305 "JR" 304 "JQ" 303 "JP" 302 "JO" 301 "JN" 300 "JM" 299 "JL" 298 "JK" 297 "JJ" 296 "JI" 295 "JH" 294 "JG" 293 "JF" 292 "JE" 291 "JD" 290 "JC" 289 "JB" 288 "JA" 281 "IZ" 280 "IY" 279 "IX" 278 "IW" 277 "IV" 276 "IU" 275 "IT" 274 "IS" 273 "IR" 272 "IQ" 271 "IP" 270 "IO" 269 "IN" 268 "IM" 267 "IL" 266 "IK" 265 "IJ" 264 "II" 263 "IH" 262 "IG" 261 "IF" 260 "IE" 259 "ID" 258 "IC" 257 "IB" 256 "IA" 249 "HZ" 248 "HY" 247 "HX" 246 "HW" 245 "HV" 244 "HU" 243 "HT" 242 "HS" 241 "HR" 240 "HQ" 239 "HP" 238 "HO" 237 "HN" 236 "HM" 235 "HL" 234 "HK" 233 "HJ" 232 "HI" 231 "HH" 230 "HG" 229 "HF" 228 "HE" 227 "HD" 226 "HC" 225 "HB" 224 "HA" 217 "GZ" 216 "GY" 215 "GX" 214 "GW" 213 "GV" 212 "GU" 211 "GT" 210 "GS" 209 "GR" 208 "GQ" 207 "GP" 206 "GO" 205 "GN" 204 "GM" 203 "GL" 202 "GK" 201 "GJ" 200 "GI" 199 "GH" 198 "GG" 197 "GF" 196 "GE" 195 "GD" 194 "GC" 193 "GB" 192 "GA" 185 "FZ" 184 "FY" 183 "FX" 182 "FW" 181 "FV" 180 "FU" 179 "FT" 178 "FS" 177 "FR" 176 "FQ" 175 "FP" 174 "FO" 173 "FN" 172 "FM" 171 "FL" 170 "FK" 169 "FJ" 168 "FI" 167 "FH" 166 "FG" 165 "FF" 164 "FE" 163 "FD" 162 "FC" 161 "FB" 160 "FA" 153 "EZ" 152 "EY" 151 "EX" 150 "EW" 149 "EV" 148 "EU" 147 "ET" 146 "ES" 145 "ER" 144 "EQ" 143 "EP" 142 "EO" 141 "EN" 140 "EM" 139 "EL" 138 "EK" 137 "EJ" 136 "EI" 135 "EH" 134 "EG" 133 "EF" 132 "EE" 131 "ED" 130 "EC" 129 "EB" 128 "EA" 121 "DZ" 120 "DY" 119 "DX" 118 "DW" 117 "DV" 116 "DU" 115 "DT" 114 "DS" 113 "DR" 112 "DQ" 111 "DP" 110 "DO" 109 "DN" 108 "DM" 107 "DL" 106 "DK" 105 "DJ" 104 "DI" 103 "DH" 102 "DG" 101 "DF" 100 "DE" 99 "DD" 98 "DC" 97 "DB" 96 "DA" 89 "CZ" 88 "CY" 87 "CX" 86 "CW" 85 "CV" 84 "CU" 83 "CT" 82 "CS" 81 "CR" 80 "CQ" 79 "CP" 78 "CO" 77 "CN" 76 "CM" 75 "CL" 74 "CK" 73 "CJ" 72 "CI" 71 "CH" 70 "CG" 69 "CF" 68 "CE" 67 "CD" 66 "CC" 65 "CB" 64 "CA" 57 "BZ" 56 "BY" 55 "BX" 54 "BW" 53 "BV" 52 "BU" 51 "BT" 50 "BS" 49 "BR" 48 "BQ" 47 "BP" 46 "BO" 45 "BN" 44 "BM" 43 "BL" 42 "BK" 41 "BJ" 40 "BI" 39 "BH" 38 "BG" 37 "BF" 36 "BE" 35 "BD" 34 "BC" 33 "BB" 32 "BA" 25 "AZ" 24 "AY" 23 "AX" 22 "AW" 21 "AV" 20 "AU" 19 "AT" 18 "AS" 17 "AR" 16 "AQ" 15 "AP" 14 "AO" 13 "AN" 12 "AM" 11 "AL" 10 "AK" 9 "AJ" 8 "AI" 7 "AH" 6 "AG" 5 "AF" 4 "AE" 3 "AD" 2 "AC" 1 "AB" 0 "AA" ;
VAL_ 2499743083 HVESP01_SerNum_Location_7 2 "Springboro" 1 "Lake Orion Tech Center" 0 "Unknown" ;
VAL_ 2499743083 HVESP01_SerNum_PartNo_SubVe_0005 825 "ZZ" 824 "ZY" 823 "ZX" 822 "ZW" 821 "ZV" 820 "ZU" 819 "ZT" 818 "ZS" 817 "ZR" 816 "ZQ" 815 "ZP" 814 "ZO" 813 "ZN" 812 "ZM" 811 "ZL" 810 "ZK" 809 "ZJ" 808 "ZI" 807 "ZH" 806 "ZG" 805 "ZF" 804 "ZE" 803 "ZD" 802 "ZC" 801 "ZB" 800 "ZA" 793 "YZ" 792 "YY" 791 "YX" 790 "YW" 789 "YV" 788 "YU" 787 "YT" 786 "YS" 785 "YR" 784 "YQ" 783 "YP" 782 "YO" 781 "YN" 780 "YM" 779 "YL" 778 "YK" 777 "YJ" 776 "YI" 775 "YH" 774 "YG" 773 "YF" 772 "YE" 771 "YD" 770 "YC" 769 "YB" 768 "YA" 761 "XZ" 760 "XY" 759 "XX" 758 "XW" 757 "XV" 756 "XU" 755 "XT" 754 "XS" 753 "XR" 752 "XQ" 751 "XP" 750 "XO" 749 "XN" 748 "XM" 747 "XL" 746 "XK" 745 "XJ" 744 "XI" 743 "XH" 742 "XG" 741 "XF" 740 "XE" 739 "XD" 738 "XC" 737 "XB" 736 "XA" 729 "WZ" 728 "WY" 727 "WX" 726 "WW" 725 "WV" 724 "WU" 723 "WT" 722 "WS" 721 "WR" 720 "WQ" 719 "WP" 718 "WO" 717 "WN" 716 "WM" 715 "WL" 714 "WK" 713 "WJ" 712 "WI" 711 "WH" 710 "WG" 709 "WF" 708 "WE" 707 "WD" 706 "WC" 705 "WB" 704 "WA" 697 "VZ" 696 "VY" 695 "VX" 694 "VW" 693 "VV" 692 "VU" 691 "VT" 690 "VS" 689 "VR" 688 "VQ" 687 "VP" 686 "VO" 685 "VN" 684 "VM" 683 "VL" 682 "VK" 681 "VJ" 680 "VI" 679 "VH" 678 "VG" 677 "VF" 676 "VE" 675 "VD" 674 "VC" 673 "VB" 672 "VA" 665 "UZ" 664 "UY" 663 "UX" 662 "UW" 661 "UV" 660 "UU" 659 "UT" 658 "US" 657 "UR" 656 "UQ" 655 "UP" 654 "UO" 653 "UN" 652 "UM" 651 "UL" 650 "UK" 649 "UJ" 648 "UI" 647 "UH" 646 "UG" 645 "UF" 644 "UE" 643 "UD" 642 "UC" 641 "UB" 640 "UA" 633 "TZ" 632 "TY" 631 "TX" 630 "TW" 629 "TV" 628 "TU" 627 "TT" 626 "TS" 625 "TR" 624 "TQ" 623 "TP" 622 "TO" 621 "TN" 620 "TM" 619 "TL" 618 "TK" 617 "TJ" 616 "TI" 615 "TH" 614 "TG" 613 "TF" 612 "TE" 611 "TD" 610 "TC" 609 "TB" 608 "TA" 601 "SZ" 600 "SY" 599 "SX" 598 "SW" 597 "SV" 596 "SU" 595 "ST" 594 "SS" 593 "SR" 592 "SQ" 591 "SP" 590 "SO" 589 "SN" 588 "SM" 587 "SL" 586 "SK" 585 "SJ" 584 "SI" 583 "SH" 582 "SG" 581 "SF" 580 "SE" 579 "SD" 578 "SC" 577 "SB" 576 "SA" 569 "RZ" 568 "RY" 567 "RX" 566 "RW" 565 "RV" 564 "RU" 563 "RT" 562 "RS" 561 "RR" 560 "RQ" 559 "RP" 558 "RO" 557 "RN" 556 "RM" 555 "RL" 554 "RK" 553 "RJ" 552 "RI" 551 "RH" 550 "RG" 549 "RF" 548 "RE" 547 "RD" 546 "RC" 545 "RB" 544 "RA" 537 "QZ" 536 "QY" 535 "QX" 534 "QW" 533 "QV" 532 "QU" 531 "QT" 530 "QS" 529 "QR" 528 "QQ" 527 "QP" 526 "QO" 525 "QN" 524 "QM" 523 "QL" 522 "QK" 521 "QJ" 520 "QI" 519 "QH" 518 "QG" 517 "QF" 516 "QE" 515 "QD" 514 "QC" 513 "QB" 512 "QA" 505 "PZ" 504 "PY" 503 "PX" 502 "PW" 501 "PV" 500 "PU" 499 "PT" 498 "PS" 497 "PR" 496 "PQ" 495 "PP" 494 "PO" 493 "PN" 492 "PM" 491 "PL" 490 "PK" 489 "PJ" 488 "PI" 487 "PH" 486 "PG" 485 "PF" 484 "PE" 483 "PD" 482 "PC" 481 "PB" 480 "PA" 473 "OZ" 472 "OY" 471 "OX" 470 "OW" 469 "OV" 468 "OU" 467 "OT" 466 "OS" 465 "OR" 464 "OQ" 463 "OP" 462 "OO" 461 "ON" 460 "OM" 459 "OL" 458 "OK" 457 "OJ" 456 "OI" 455 "OH" 454 "OG" 453 "OF" 452 "OE" 451 "OD" 450 "OC" 449 "OB" 448 "OA" 441 "NZ" 440 "NY" 439 "NX" 438 "NW" 437 "NV" 436 "NU" 435 "NT" 434 "NS" 433 "NR" 432 "NQ" 431 "NP" 430 "NO" 429 "NN" 428 "NM" 427 "NL" 426 "NK" 425 "NJ" 424 "NI" 423 "NH" 422 "NG" 421 "NF" 420 "NE" 419 "ND" 418 "NC" 417 "NB" 416 "NA" 409 "MZ" 408 "MY" 407 "MX" 406 "MW" 405 "MV" 404 "MU" 403 "MT" 402 "MS" 401 "MR" 400 "MQ" 399 "MP" 398 "MO" 397 "MN" 396 "MM" 395 "ML" 394 "MK" 393 "MJ" 392 "MI" 391 "MH" 390 "MG" 389 "MF" 388 "ME" 387 "MD" 386 "MC" 385 "MB" 384 "MA" 377 "LZ" 376 "LY" 375 "LX" 374 "LW" 373 "LV" 372 "LU" 371 "LT" 370 "LS" 369 "LR" 368 "LQ" 367 "LP" 366 "LO" 365 "LN" 364 "LM" 363 "LL" 362 "LK" 361 "LJ" 360 "LI" 359 "LH" 358 "LG" 357 "LF" 356 "LE" 355 "LD" 354 "LC" 353 "LB" 352 "LA" 345 "KZ" 344 "KY" 343 "KX" 342 "KW" 341 "KV" 340 "KU" 339 "KT" 338 "KS" 337 "KR" 336 "KQ" 335 "KP" 334 "KO" 333 "KN" 332 "KM" 331 "KL" 330 "KK" 329 "KJ" 328 "KI" 327 "KH" 326 "KG" 325 "KF" 324 "KE" 323 "KD" 322 "KC" 321 "KB" 320 "KA" 313 "JZ" 312 "JY" 311 "JX" 310 "JW" 309 "JV" 308 "JU" 307 "JT" 306 "JS" 305 "JR" 304 "JQ" 303 "JP" 302 "JO" 301 "JN" 300 "JM" 299 "JL" 298 "JK" 297 "JJ" 296 "JI" 295 "JH" 294 "JG" 293 "JF" 292 "JE" 291 "JD" 290 "JC" 289 "JB" 288 "JA" 281 "IZ" 280 "IY" 279 "IX" 278 "IW" 277 "IV" 276 "IU" 275 "IT" 274 "IS" 273 "IR" 272 "IQ" 271 "IP" 270 "IO" 269 "IN" 268 "IM" 267 "IL" 266 "IK" 265 "IJ" 264 "II" 263 "IH" 262 "IG" 261 "IF" 260 "IE" 259 "ID" 258 "IC" 257 "IB" 256 "IA" 249 "HZ" 248 "HY" 247 "HX" 246 "HW" 245 "HV" 244 "HU" 243 "HT" 242 "HS" 241 "HR" 240 "HQ" 239 "HP" 238 "HO" 237 "HN" 236 "HM" 235 "HL" 234 "HK" 233 "HJ" 232 "HI" 231 "HH" 230 "HG" 229 "HF" 228 "HE" 227 "HD" 226 "HC" 225 "HB" 224 "HA" 217 "GZ" 216 "GY" 215 "GX" 214 "GW" 213 "GV" 212 "GU" 211 "GT" 210 "GS" 209 "GR" 208 "GQ" 207 "GP" 206 "GO" 205 "GN" 204 "GM" 203 "GL" 202 "GK" 201 "GJ" 200 "GI" 199 "GH" 198 "GG" 197 "GF" 196 "GE" 195 "GD" 194 "GC" 193 "GB" 192 "GA" 185 "FZ" 184 "FY" 183 "FX" 182 "FW" 181 "FV" 180 "FU" 179 "FT" 178 "FS" 177 "FR" 176 "FQ" 175 "FP" 174 "FO" 173 "FN" 172 "FM" 171 "FL" 170 "FK" 169 "FJ" 168 "FI" 167 "FH" 166 "FG" 165 "FF" 164 "FE" 163 "FD" 162 "FC" 161 "FB" 160 "FA" 153 "EZ" 152 "EY" 151 "EX" 150 "EW" 149 "EV" 148 "EU" 147 "ET" 146 "ES" 145 "ER" 144 "EQ" 143 "EP" 142 "EO" 141 "EN" 140 "EM" 139 "EL" 138 "EK" 137 "EJ" 136 "EI" 135 "EH" 134 "EG" 133 "EF" 132 "EE" 131 "ED" 130 "EC" 129 "EB" 128 "EA" 121 "DZ" 120 "DY" 119 "DX" 118 "DW" 117 "DV" 116 "DU" 115 "DT" 114 "DS" 113 "DR" 112 "DQ" 111 "DP" 110 "DO" 109 "DN" 108 "DM" 107 "DL" 106 "DK" 105 "DJ" 104 "DI" 103 "DH" 102 "DG" 101 "DF" 100 "DE" 99 "DD" 98 "DC" 97 "DB" 96 "DA" 89 "CZ" 88 "CY" 87 "CX" 86 "CW" 85 "CV" 84 "CU" 83 "CT" 82 "CS" 81 "CR" 80 "CQ" 79 "CP" 78 "CO" 77 "CN" 76 "CM" 75 "CL" 74 "CK" 73 "CJ" 72 "CI" 71 "CH" 70 "CG" 69 "CF" 68 "CE" 67 "CD" 66 "CC" 65 "CB" 64 "CA" 57 "BZ" 56 "BY" 55 "BX" 54 "BW" 53 "BV" 52 "BU" 51 "BT" 50 "BS" 49 "BR" 48 "BQ" 47 "BP" 46 "BO" 45 "BN" 44 "BM" 43 "BL" 42 "BK" 41 "BJ" 40 "BI" 39 "BH" 38 "BG" 37 "BF" 36 "BE" 35 "BD" 34 "BC" 33 "BB" 32 "BA" 25 "AZ" 24 "AY" 23 "AX" 22 "AW" 21 "AV" 20 "AU" 19 "AT" 18 "AS" 17 "AR" 16 "AQ" 15 "AP" 14 "AO" 13 "AN" 12 "AM" 11 "AL" 10 "AK" 9 "AJ" 8 "AI" 7 "AH" 6 "AG" 5 "AF" 4 "AE" 3 "AD" 2 "AC" 1 "AB" 0 "AA" ;
VAL_ 2499743084 HVESP01_SerNum_Location_8 2 "Springboro" 1 "Lake Orion Tech Center" 0 "Unknown" ;
VAL_ 2499743084 HVESP01_SerNum_PartNo_SubVe_0006 825 "ZZ" 824 "ZY" 823 "ZX" 822 "ZW" 821 "ZV" 820 "ZU" 819 "ZT" 818 "ZS" 817 "ZR" 816 "ZQ" 815 "ZP" 814 "ZO" 813 "ZN" 812 "ZM" 811 "ZL" 810 "ZK" 809 "ZJ" 808 "ZI" 807 "ZH" 806 "ZG" 805 "ZF" 804 "ZE" 803 "ZD" 802 "ZC" 801 "ZB" 800 "ZA" 793 "YZ" 792 "YY" 791 "YX" 790 "YW" 789 "YV" 788 "YU" 787 "YT" 786 "YS" 785 "YR" 784 "YQ" 783 "YP" 782 "YO" 781 "YN" 780 "YM" 779 "YL" 778 "YK" 777 "YJ" 776 "YI" 775 "YH" 774 "YG" 773 "YF" 772 "YE" 771 "YD" 770 "YC" 769 "YB" 768 "YA" 761 "XZ" 760 "XY" 759 "XX" 758 "XW" 757 "XV" 756 "XU" 755 "XT" 754 "XS" 753 "XR" 752 "XQ" 751 "XP" 750 "XO" 749 "XN" 748 "XM" 747 "XL" 746 "XK" 745 "XJ" 744 "XI" 743 "XH" 742 "XG" 741 "XF" 740 "XE" 739 "XD" 738 "XC" 737 "XB" 736 "XA" 729 "WZ" 728 "WY" 727 "WX" 726 "WW" 725 "WV" 724 "WU" 723 "WT" 722 "WS" 721 "WR" 720 "WQ" 719 "WP" 718 "WO" 717 "WN" 716 "WM" 715 "WL" 714 "WK" 713 "WJ" 712 "WI" 711 "WH" 710 "WG" 709 "WF" 708 "WE" 707 "WD" 706 "WC" 705 "WB" 704 "WA" 697 "VZ" 696 "VY" 695 "VX" 694 "VW" 693 "VV" 692 "VU" 691 "VT" 690 "VS" 689 "VR" 688 "VQ" 687 "VP" 686 "VO" 685 "VN" 684 "VM" 683 "VL" 682 "VK" 681 "VJ" 680 "VI" 679 "VH" 678 "VG" 677 "VF" 676 "VE" 675 "VD" 674 "VC" 673 "VB" 672 "VA" 665 "UZ" 664 "UY" 663 "UX" 662 "UW" 661 "UV" 660 "UU" 659 "UT" 658 "US" 657 "UR" 656 "UQ" 655 "UP" 654 "UO" 653 "UN" 652 "UM" 651 "UL" 650 "UK" 649 "UJ" 648 "UI" 647 "UH" 646 "UG" 645 "UF" 644 "UE" 643 "UD" 642 "UC" 641 "UB" 640 "UA" 633 "TZ" 632 "TY" 631 "TX" 630 "TW" 629 "TV" 628 "TU" 627 "TT" 626 "TS" 625 "TR" 624 "TQ" 623 "TP" 622 "TO" 621 "TN" 620 "TM" 619 "TL" 618 "TK" 617 "TJ" 616 "TI" 615 "TH" 614 "TG" 613 "TF" 612 "TE" 611 "TD" 610 "TC" 609 "TB" 608 "TA" 601 "SZ" 600 "SY" 599 "SX" 598 "SW" 597 "SV" 596 "SU" 595 "ST" 594 "SS" 593 "SR" 592 "SQ" 591 "SP" 590 "SO" 589 "SN" 588 "SM" 587 "SL" 586 "SK" 585 "SJ" 584 "SI" 583 "SH" 582 "SG" 581 "SF" 580 "SE" 579 "SD" 578 "SC" 577 "SB" 576 "SA" 569 "RZ" 568 "RY" 567 "RX" 566 "RW" 565 "RV" 564 "RU" 563 "RT" 562 "RS" 561 "RR" 560 "RQ" 559 "RP" 558 "RO" 557 "RN" 556 "RM" 555 "RL" 554 "RK" 553 "RJ" 552 "RI" 551 "RH" 550 "RG" 549 "RF" 548 "RE" 547 "RD" 546 "RC" 545 "RB" 544 "RA" 537 "QZ" 536 "QY" 535 "QX" 534 "QW" 533 "QV" 532 "QU" 531 "QT" 530 "QS" 529 "QR" 528 "QQ" 527 "QP" 526 "QO" 525 "QN" 524 "QM" 523 "QL" 522 "QK" 521 "QJ" 520 "QI" 519 "QH" 518 "QG" 517 "QF" 516 "QE" 515 "QD" 514 "QC" 513 "QB" 512 "QA" 505 "PZ" 504 "PY" 503 "PX" 502 "PW" 501 "PV" 500 "PU" 499 "PT" 498 "PS" 497 "PR" 496 "PQ" 495 "PP" 494 "PO" 493 "PN" 492 "PM" 491 "PL" 490 "PK" 489 "PJ" 488 "PI" 487 "PH" 486 "PG" 485 "PF" 484 "PE" 483 "PD" 482 "PC" 481 "PB" 480 "PA" 473 "OZ" 472 "OY" 471 "OX" 470 "OW" 469 "OV" 468 "OU" 467 "OT" 466 "OS" 465 "OR" 464 "OQ" 463 "OP" 462 "OO" 461 "ON" 460 "OM" 459 "OL" 458 "OK" 457 "OJ" 456 "OI" 455 "OH" 454 "OG" 453 "OF" 452 "OE" 451 "OD" 450 "OC" 449 "OB" 448 "OA" 441 "NZ" 440 "NY" 439 "NX" 438 "NW" 437 "NV" 436 "NU" 435 "NT" 434 "NS" 433 "NR" 432 "NQ" 431 "NP" 430 "NO" 429 "NN" 428 "NM" 427 "NL" 426 "NK" 425 "NJ" 424 "NI" 423 "NH" 422 "NG" 421 "NF" 420 "NE" 419 "ND" 418 "NC" 417 "NB" 416 "NA" 409 "MZ" 408 "MY" 407 "MX" 406 "MW" 405 "MV" 404 "MU" 403 "MT" 402 "MS" 401 "MR" 400 "MQ" 399 "MP" 398 "MO" 397 "MN" 396 "MM" 395 "ML" 394 "MK" 393 "MJ" 392 "MI" 391 "MH" 390 "MG" 389 "MF" 388 "ME" 387 "MD" 386 "MC" 385 "MB" 384 "MA" 377 "LZ" 376 "LY" 375 "LX" 374 "LW" 373 "LV" 372 "LU" 371 "LT" 370 "LS" 369 "LR" 368 "LQ" 367 "LP" 366 "LO" 365 "LN" 364 "LM" 363 "LL" 362 "LK" 361 "LJ" 360 "LI" 359 "LH" 358 "LG" 357 "LF" 356 "LE" 355 "LD" 354 "LC" 353 "LB" 352 "LA" 345 "KZ" 344 "KY" 343 "KX" 342 "KW" 341 "KV" 340 "KU" 339 "KT" 338 "KS" 337 "KR" 336 "KQ" 335 "KP" 334 "KO" 333 "KN" 332 "KM" 331 "KL" 330 "KK" 329 "KJ" 328 "KI" 327 "KH" 326 "KG" 325 "KF" 324 "KE" 323 "KD" 322 "KC" 321 "KB" 320 "KA" 313 "JZ" 312 "JY" 311 "JX" 310 "JW" 309 "JV" 308 "JU" 307 "JT" 306 "JS" 305 "JR" 304 "JQ" 303 "JP" 302 "JO" 301 "JN" 300 "JM" 299 "JL" 298 "JK" 297 "JJ" 296 "JI" 295 "JH" 294 "JG" 293 "JF" 292 "JE" 291 "JD" 290 "JC" 289 "JB" 288 "JA" 281 "IZ" 280 "IY" 279 "IX" 278 "IW" 277 "IV" 276 "IU" 275 "IT" 274 "IS" 273 "IR" 272 "IQ" 271 "IP" 270 "IO" 269 "IN" 268 "IM" 267 "IL" 266 "IK" 265 "IJ" 264 "II" 263 "IH" 262 "IG" 261 "IF" 260 "IE" 259 "ID" 258 "IC" 257 "IB" 256 "IA" 249 "HZ" 248 "HY" 247 "HX" 246 "HW" 245 "HV" 244 "HU" 243 "HT" 242 "HS" 241 "HR" 240 "HQ" 239 "HP" 238 "HO" 237 "HN" 236 "HM" 235 "HL" 234 "HK" 233 "HJ" 232 "HI" 231 "HH" 230 "HG" 229 "HF" 228 "HE" 227 "HD" 226 "HC" 225 "HB" 224 "HA" 217 "GZ" 216 "GY" 215 "GX" 214 "GW" 213 "GV" 212 "GU" 211 "GT" 210 "GS" 209 "GR" 208 "GQ" 207 "GP" 206 "GO" 205 "GN" 204 "GM" 203 "GL" 202 "GK" 201 "GJ" 200 "GI" 199 "GH" 198 "GG" 197 "GF" 196 "GE" 195 "GD" 194 "GC" 193 "GB" 192 "GA" 185 "FZ" 184 "FY" 183 "FX" 182 "FW" 181 "FV" 180 "FU" 179 "FT" 178 "FS" 177 "FR" 176 "FQ" 175 "FP" 174 "FO" 173 "FN" 172 "FM" 171 "FL" 170 "FK" 169 "FJ" 168 "FI" 167 "FH" 166 "FG" 165 "FF" 164 "FE" 163 "FD" 162 "FC" 161 "FB" 160 "FA" 153 "EZ" 152 "EY" 151 "EX" 150 "EW" 149 "EV" 148 "EU" 147 "ET" 146 "ES" 145 "ER" 144 "EQ" 143 "EP" 142 "EO" 141 "EN" 140 "EM" 139 "EL" 138 "EK" 137 "EJ" 136 "EI" 135 "EH" 134 "EG" 133 "EF" 132 "EE" 131 "ED" 130 "EC" 129 "EB" 128 "EA" 121 "DZ" 120 "DY" 119 "DX" 118 "DW" 117 "DV" 116 "DU" 115 "DT" 114 "DS" 113 "DR" 112 "DQ" 111 "DP" 110 "DO" 109 "DN" 108 "DM" 107 "DL" 106 "DK" 105 "DJ" 104 "DI" 103 "DH" 102 "DG" 101 "DF" 100 "DE" 99 "DD" 98 "DC" 97 "DB" 96 "DA" 89 "CZ" 88 "CY" 87 "CX" 86 "CW" 85 "CV" 84 "CU" 83 "CT" 82 "CS" 81 "CR" 80 "CQ" 79 "CP" 78 "CO" 77 "CN" 76 "CM" 75 "CL" 74 "CK" 73 "CJ" 72 "CI" 71 "CH" 70 "CG" 69 "CF" 68 "CE" 67 "CD" 66 "CC" 65 "CB" 64 "CA" 57 "BZ" 56 "BY" 55 "BX" 54 "BW" 53 "BV" 52 "BU" 51 "BT" 50 "BS" 49 "BR" 48 "BQ" 47 "BP" 46 "BO" 45 "BN" 44 "BM" 43 "BL" 42 "BK" 41 "BJ" 40 "BI" 39 "BH" 38 "BG" 37 "BF" 36 "BE" 35 "BD" 34 "BC" 33 "BB" 32 "BA" 25 "AZ" 24 "AY" 23 "AX" 22 "AW" 21 "AV" 20 "AU" 19 "AT" 18 "AS" 17 "AR" 16 "AQ" 15 "AP" 14 "AO" 13 "AN" 12 "AM" 11 "AL" 10 "AK" 9 "AJ" 8 "AI" 7 "AH" 6 "AG" 5 "AF" 4 "AE" 3 "AD" 2 "AC" 1 "AB" 0 "AA" ;
